VERSION ""

NS_ :

BS_:

BU_: VDM CMR_DSMC SOBDMC_HPCM_FD1 IPMA_ADAS PSCM ABS_ESC TCCM TCM_DSL PCM_HEV PCM ECM_Diesel GENERIC_GWMWakeup GWM _delete TSTR

BO_ 2611055832 PARSEDPhysGWM_ECGtoSODR: 8 GWM
 SG_ PARSEDPhysGWM_ECGtoSODR : 7|29@0+ (1,0) [0|536870911] "unitless" IPMA_ADAS

BO_ 2611054808 PARSEDPhysGWM_ECGtoSODL: 8 GWM
 SG_ PARSEDPhysGWM_ECGtoSODL : 7|29@0+ (1,0) [0|536870911] "unitless" IPMA_ADAS

BO_ 2611026136 PARSEDPhysGWM_ECGtoSODCMD: 8 GWM
 SG_ PARSEDPhysGWM_ECGtoSODCMD : 7|29@0+ (1,0) [0|536870911] "unitless" IPMA_ADAS

BO_ 2611025112 PARSEDPhysGWM_ECGtoSODCMC: 8 GWM
 SG_ PARSEDPhysGWM_ECGtoSODCMC : 7|29@0+ (1,0) [0|536870911] "unitless" IPMA_ADAS

BO_ 2610975960 PARSEDPhysGWM_ECGtoCCM: 8 GWM
 SG_ PARSEDPhysGWM_ECGtoCCM : 7|29@0+ (1,0) [0|536870911] "unitless" IPMA_ADAS

BO_ 2610007256 OTAPhysGWM_ECGtoSODR: 8 GWM
 SG_ OTAPhysGWM_ECGtoSODR : 7|29@0+ (1,0) [0|536870911] "unitless" IPMA_ADAS

BO_ 2610006232 OTAPhysGWM_ECGtoSODL: 8 GWM
 SG_ OTAPhysGWM_ECGtoSODL : 7|29@0+ (1,0) [0|536870911] "unitless" IPMA_ADAS

BO_ 2609977560 OTAPhysGWM_ECGtoSODCMD: 8 GWM
 SG_ OTAPhysGWM_ECGtoSODCMD : 7|29@0+ (1,0) [0|536870911] "unitless" IPMA_ADAS

BO_ 2609976536 OTAPhysGWM_ECGtoSODCMC: 8 GWM
 SG_ OTAPhysGWM_ECGtoSODCMC : 7|29@0+ (1,0) [0|536870911] "unitless" IPMA_ADAS

BO_ 2609927384 OTAPhysGWM_ECGtoCCM: 8 GWM
 SG_ OTAPhysGWM_ECGtoCCM : 7|29@0+ (1,0) [0|536870911] "unitless" IPMA_ADAS

BO_ 2611175523 PARSEDPhysSODRtoGWM_ECG: 8 IPMA_ADAS
 SG_ PARSEDPhysSODRtoGWM_ECG : 7|29@0+ (1,0) [0|536870911] "unitless" GWM

BO_ 2612224099 PARSEDPushSODRtoGWM_ECG: 8 IPMA_ADAS
 SG_ PARSEDPhysSODR2toGWM_ECG : 7|29@0+ (1,0) [0|536870911] "unitless" GWM

BO_ 2611175522 PARSEDPhysSODLtoGWM_ECG: 8 IPMA_ADAS
 SG_ PARSEDPhysSODLtoGWM_ECG : 7|29@0+ (1,0) [0|536870911] "unitless" GWM

BO_ 2612224098 PARSEDPushSODLtoGWM_ECG: 8 IPMA_ADAS
 SG_ PARSEDPhysSODL2toGWM_ECG : 7|29@0+ (1,0) [0|536870911] "unitless" GWM

BO_ 2611175494 PARSEDPhysSODCMDtoGWM_ECG: 8 IPMA_ADAS
 SG_ PARSEDPhysSODCMDtoGWM_ECG : 7|29@0+ (1,0) [0|536870911] "unitless" GWM

BO_ 2612224070 PARSEDPushSODCMDtoGWM: 8 IPMA_ADAS
 SG_ PARSEDPhysSODCMD2toGWM_ECG : 7|29@0+ (1,0) [0|536870911] "unitless" GWM

BO_ 2611175493 PARSEDPhysSODCMCtoGWM_ECG: 8 IPMA_ADAS
 SG_ PARSEDPhysSODCMCtoGWM_ECG : 7|29@0+ (1,0) [0|536870911] "unitless" GWM

BO_ 2612224069 PARSEDPushSODCMCtoGWM: 8 IPMA_ADAS
 SG_ PARSEDPhysSODCMC2toGWM_ECG : 7|29@0+ (1,0) [0|536870911] "unitless" GWM

BO_ 2611175445 PARSEDPhysCCMtoGWM_ECG: 8 IPMA_ADAS
 SG_ PARSEDPhysCCMtoGWM_ECG : 7|29@0+ (1,0) [0|536870911] "unitless" GWM

BO_ 2612224021 PARSEDPushCCMtoGWM_ECG: 8 IPMA_ADAS
 SG_ PARSEDPhysCCM2toGWM_ECG : 7|29@0+ (1,0) [0|536870911] "unitless" GWM

BO_ 2610126947 OTAPhysSODRtoGWM_ECG: 8 IPMA_ADAS
 SG_ OTAPhysSODRtoGWM_ECG : 7|29@0+ (1,0) [0|536870911] "unitless" GWM

BO_ 2610126946 OTAPhysSODLtoGWM_ECG: 8 IPMA_ADAS
 SG_ OTAPhysSODLtoGWM_ECG : 7|29@0+ (1,0) [0|536870911] "unitless" GWM

BO_ 2610126918 OTAPhysSODCMDtoGWM_ECG: 8 IPMA_ADAS
 SG_ OTAPhysSODCMDtoGWM_ECG : 7|29@0+ (1,0) [0|536870911] "unitless" GWM

BO_ 2610126917 OTAPhysSODCMCtoGWM_ECG: 8 IPMA_ADAS
 SG_ OTAPhysSODCMCtoGWM_ECG : 7|29@0+ (1,0) [0|536870911] "unitless" GWM

BO_ 2610126869 OTAPhysCCMtoGWM_ECG: 8 IPMA_ADAS
 SG_ OTAPhysCCMtoGWM_ECG : 7|29@0+ (1,0) [0|536870911] "unitless" GWM

BO_ 984 IPMA_Data: 16 IPMA_ADAS
 SG_ FeatConfigIpmaActl : 7|16@0+ (1,0) [0|65535] "Undefined" GWM
 SG_ FeatNoIpmaActl : 23|16@0+ (1,0) [0|65535] "Number" GWM
 SG_ PersIndexIpma_D_Actl : 39|3@0+ (1,0) [0|7] "SED" GWM
 SG_ AhbcRampingV_D_Rq : 57|2@0+ (1,0) [0|3] "SED" GWM
 SG_ LaActvStats_D_Dsply : 55|5@0+ (1,0) [0|31] "SED" GWM
 SG_ LaDenyStats_B_Dsply : 32|1@0+ (1,0) [0|1] "SED" GWM
 SG_ LaHandsOff_D_Dsply : 50|2@0+ (1,0) [0|3] "SED" GWM
 SG_ CamraDefog_B_Req : 36|1@0+ (1,0) [0|1] "SED" GWM
 SG_ CamraStats_D_Dsply : 35|2@0+ (1,0) [0|3] "SED" GWM
 SG_ DasAlrtLvl_D_Dsply : 42|3@0+ (1,0) [0|7] "SED" GWM
 SG_ DasStats_D_Dsply : 47|2@0+ (1,0) [0|3] "SED" GWM
 SG_ DasWarn_D_Dsply : 44|2@0+ (1,0) [0|3] "SED" GWM
 SG_ AhbHiBeam_D_Rq : 59|2@0+ (1,0) [0|3] "SED" GWM
 SG_ Passthru_63 : 63|4@0+ (1,0) [0|15] "" XXX
 SG_ Passthru_48 : 48|1@0+ (1,0) [0|1] "" XXX

BO_ 985 IPMA_Data2: 16 IPMA_ADAS
 SG_ LdwChime_B_Rq : 34|1@0+ (1,0) [0|1] "SED" GWM
 SG_ TsrRegionTxt_D_Stat : 47|5@0+ (1,0) [0|31] "SED" GWM
 SG_ SblmPedCrossScnr_B_Stat : 33|1@0+ (1,0) [0|1] "SED" GWM
 SG_ LongCtrlEnbl_D_Rq : 42|3@0+ (1,0) [0|7] "SED" ECM_Diesel,PCM,PCM_HEV,GWM
 SG_ SblmRndAbtScnr_B_Stat : 9|1@0+ (1,0) [0|1] "SED" GWM
 SG_ DasAlrtInfo_D_Dsply : 13|2@0+ (1,0) [0|3] "SED" GWM
 SG_ IaccVLim_D_Rq : 23|8@0+ (1,0) [0|255] "SED" ECM_Diesel,GWM
 SG_ IaccVLimUnit_D_Rq : 11|2@0+ (1,0) [0|3] "SED" ECM_Diesel,GWM
 SG_ IsaVLim_D_Rq : 7|8@0+ (1,0) [0|255] "SED" ECM_Diesel,GWM
 SG_ SblmStopScnr_B_Stat : 8|1@0+ (1,0) [0|1] "SED" GWM
 SG_ SblmYieldScnr_B_Stat : 31|1@0+ (1,0) [0|1] "SED" GWM
 SG_ IsaVLimUnit_D_Rq : 15|2@0+ (1,0) [0|3] "SED" ECM_Diesel,GWM
 SG_ AdbDividedRoad_B_Stat : 30|1@0+ (1,0) [0|1] "SED" GWM
 SG_ LcwaMsgTxt_D_Stat : 37|2@0+ (1,0) [0|3] "SED" GWM
 SG_ AdbDrvSide_B_Stat : 35|1@0+ (1,0) [0|1] "SED" GWM

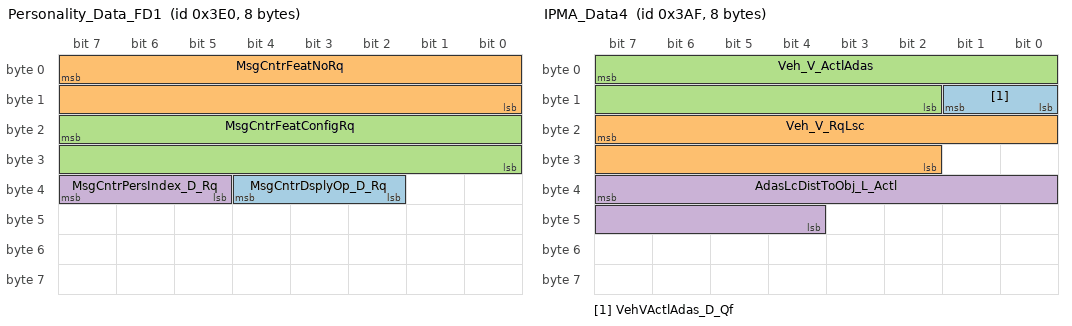
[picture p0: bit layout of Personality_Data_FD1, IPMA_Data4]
BO_ 992 Personality_Data_FD1: 8 GWM
 SG_ MsgCntrDsplyOp_D_Rq : 36|3@0+ (1,0) [0|7] "SED" IPMA_ADAS
 SG_ MsgCntrFeatNoRq : 7|16@0+ (1,0) [0|65535] "Number" IPMA_ADAS
 SG_ MsgCntrFeatConfigRq : 23|16@0+ (1,0) [0|65535] "unitless" IPMA_ADAS
 SG_ MsgCntrPersIndex_D_Rq : 39|3@0+ (1,0) [0|7] "SED" IPMA_ADAS

BO_ 2612019416 PARSEDPushFcGWM_ECGtoPCM: 8 GWM
 SG_ PARSEDPhysGWM_ECG2toPCM : 7|29@0+ (1,0) [0|536870911] "unitless" PCM,PCM_HEV,ECM_Diesel

BO_ 943 IPMA_Data4: 8 IPMA_ADAS
 SG_ VehVActlAdas_D_Qf : 9|2@0+ (1,0) [0|3] "SED" PCM,PCM_HEV,ECM_Diesel
 SG_ Veh_V_RqLsc : 23|14@0+ (0.01,0) [0|163.83] "kph" PCM,PCM_HEV,ECM_Diesel
 SG_ Veh_V_ActlAdas : 7|14@0+ (0.01,0) [0|163.83] "kph" PCM,PCM_HEV,ECM_Diesel
 SG_ AdasLcDistToObj_L_Actl : 39|12@0+ (0.002,0) [0|8.186] "meter" PCM,PCM_HEV,ECM_Diesel

BO_ 515 PowertrainData_12: 8 ECM_Diesel
 SG_ PtIgnSwtch_No_Cs : 15|8@0+ (1,0) [0|255] "Unitless" GWM
 SG_ PtIgnSwtch_No_Cnt : 5|4@0+ (1,0) [0|15] "Unitless" GWM
 SG_ PtIgnSwtch_D_Stat : 7|2@0+ (1,0) [0|3] "SED" GWM

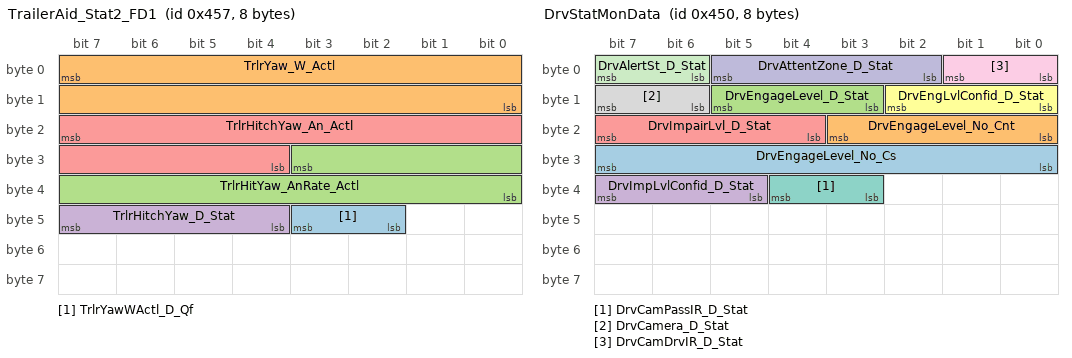
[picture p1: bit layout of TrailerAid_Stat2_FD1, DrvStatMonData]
BO_ 1111 TrailerAid_Stat2_FD1: 8 GWM
 SG_ TrlrYawWActl_D_Qf : 43|2@0+ (1,0) [0|3] "SED" IPMA_ADAS,PSCM
 SG_ TrlrYaw_W_Actl : 7|16@0+ (0.0002,-6.5) [-6.5|6.6066] "radians/second" IPMA_ADAS,PSCM
 SG_ TrlrHitYaw_AnRate_Actl : 27|12@0+ (0.1,-50) [-50|359.3] "degrees/second" IPMA_ADAS,PSCM
 SG_ TrlrHitchYaw_D_Stat : 47|4@0+ (1,0) [0|15] "SED" IPMA_ADAS,PSCM
 SG_ TrlrHitchYaw_An_Actl : 23|12@0+ (0.1,-90) [-90|319.3] "degrees" IPMA_ADAS,PSCM

BO_ 1106 TrailerAid_Stat1_FD1: 8 GWM
 SG_ TrlrSnsId_No_Actl : 7|48@0+ (1,0) [0|281474976710653] "unitless" IPMA_ADAS,PSCM

BO_ 1985 TesterPhysicalReqCMR_DSMC: 64 TSTR
 SG_ TesterPhysicalReqCMR_DSMC : 7|64@0+ (1,0) [0|1.84467E+019] "unitless" CMR_DSMC

BO_ 1993 TesterPhysicalResCMR_DSMC: 64 CMR_DSMC
 SG_ TesterPhysicalResCMR_DSMC : 7|64@0+ (1,0) [0|1.84467E+019] "unitless" TSTR

BO_ 1104 DrvStatMonData: 8 CMR_DSMC
 SG_ DrvEngageLevel_No_Cs : 31|8@0+ (1,0) [0|255] "Unitless" IPMA_ADAS
 SG_ DrvEngageLevel_No_Cnt : 19|4@0+ (1,0) [0|15] "Unitless" IPMA_ADAS
 SG_ DrvEngageLevel_D_Stat : 13|3@0+ (1,0) [0|7] "SED" IPMA_ADAS
 SG_ DrvImpLvlConfid_D_Stat : 39|3@0+ (1,0) [0|7] "SED" IPMA_ADAS
 SG_ DrvImpairLvl_D_Stat : 23|4@0+ (1,0) [0|15] "SED" IPMA_ADAS
 SG_ DrvEngLvlConfid_D_Stat : 10|3@0+ (1,0) [0|7] "SED" IPMA_ADAS
 SG_ DrvCamPassIR_D_Stat : 36|2@0+ (1,0) [0|3] "SED" IPMA_ADAS
 SG_ DrvCamera_D_Stat : 15|2@0+ (1,0) [0|3] "SED" IPMA_ADAS
 SG_ DrvCamDrvIR_D_Stat : 1|2@0+ (1,0) [0|3] "SED" IPMA_ADAS
 SG_ DrvAttentZone_D_Stat : 5|4@0+ (1,0) [0|15] "SED" IPMA_ADAS
 SG_ DrvAlertSt_D_Stat : 7|2@0+ (1,0) [0|3] "SED" IPMA_ADAS

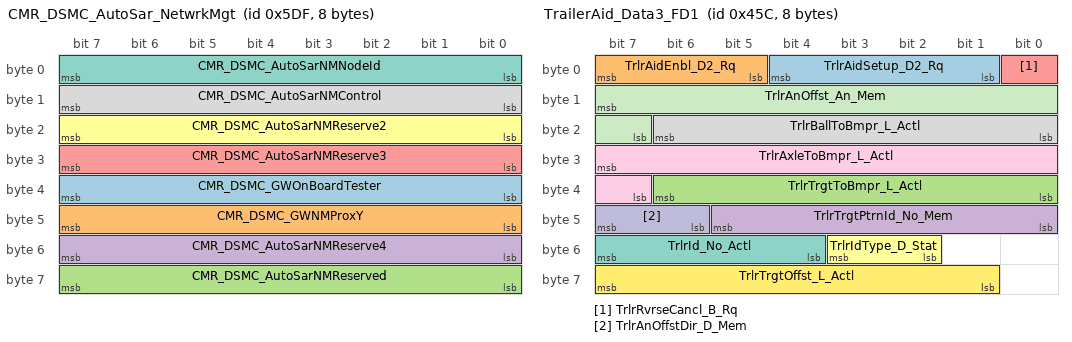
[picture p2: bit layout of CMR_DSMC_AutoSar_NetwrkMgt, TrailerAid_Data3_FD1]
BO_ 1503 CMR_DSMC_AutoSar_NetwrkMgt: 8 CMR_DSMC
 SG_ CMR_DSMC_GWOnBoardTester : 39|8@0+ (1,0) [0|255] "unitless" Vector__XXX
 SG_ CMR_DSMC_GWNMProxY : 47|8@0+ (1,0) [0|255] "unitless" Vector__XXX
 SG_ CMR_DSMC_AutoSarNMReserved : 63|8@0+ (1,0) [0|255] "unitless" Vector__XXX
 SG_ CMR_DSMC_AutoSarNMReserve4 : 55|8@0+ (1,0) [0|255] "unitless" Vector__XXX
 SG_ CMR_DSMC_AutoSarNMReserve3 : 31|8@0+ (1,0) [0|255] "unitless" Vector__XXX
 SG_ CMR_DSMC_AutoSarNMReserve2 : 23|8@0+ (1,0) [0|255] "unitless" Vector__XXX
 SG_ CMR_DSMC_AutoSarNMNodeId : 7|8@0+ (1,0) [0|255] "unitless" Vector__XXX
 SG_ CMR_DSMC_AutoSarNMControl : 15|8@0+ (1,0) [0|255] "unitless" Vector__XXX

BO_ 2610995416 PARSEDPhysGWM_ECGtoABS: 8 GWM
 SG_ PARSEDPhysGWM_ECGtoABS : 7|29@0+ (1,0) [0|536870911] "unitless"  ABS_ESC

BO_ 2612043992 PARSEDPushFcGWM_ECGtoABS: 8 GWM
 SG_ PARSEDPhysGWM_ECG2toABS : 7|29@0+ (1,0) [0|536870911] "unitless"  ABS_ESC

BO_ 2609946840 OTAPhysGWM_ECGtoABS: 8 GWM
 SG_ OTAPhysGWM_ECGtoABS : 7|29@0+ (1,0) [0|536870911] "unitless"  ABS_ESC

BO_ 2611175464 PARSEDPhysABStoGWM_ECG: 8 ABS_ESC
 SG_ PARSEDPhysABStoGWM_ECG : 7|29@0+ (1,0) [0|536870911] "Unitless"  GWM

BO_ 2612224040 PARSEDPushABStoGWM_ECG: 8 ABS_ESC
 SG_ PARSEDPhysABS2toGWM_ECG : 7|29@0+ (1,0) [0|536870911] "unitless"  GWM

BO_ 2610126888 OTAPhysABStoGWM_ECG: 8 ABS_ESC
 SG_ OTAPhysABStoGWM_ECG : 7|29@0+ (1,0) [0|536870911] "unitless"  GWM

BO_ 2610988248 PARSEDPhysGWM_ECGtoIPMA: 8 GWM
 SG_ PARSEDPhysGWM_ECGtoIPMA : 7|29@0+ (1,0) [0|536870911] "unitless"  IPMA_ADAS

BO_ 2609939672 OTAPhysGWM_ECGtoIPMA: 8 GWM
 SG_ OTAPhysGWM_ECGtoIPMA : 7|29@0+ (1,0) [0|536870911] "unitless"  IPMA_ADAS

BO_ 1114 TrailerAid_Data_FD1: 8 GWM
 SG_ TrailCtlSwtch_B_Stat2 : 16|1@0+ (1,0) [0|1] "SED"  ABS_ESC
 SG_ TrlBrkInitOut_D_Rq : 60|2@0+ (1,0) [0|3] "SED" Vector__XXX

BO_ 1116 TrailerAid_Data3_FD1: 8 GWM
 SG_ TrlrAidSetup_D2_Rq : 4|4@0+ (1,0) [0|15] "SED"  IPMA_ADAS,PSCM
 SG_ TrlrAidEnbl_D2_Rq : 7|3@0+ (1,0) [0|7] "SED"  IPMA_ADAS,PSCM
 SG_ TrlrTrgtToBmpr_L_Actl : 38|7@0+ (0.0127,0) [0|1.6129] "meter"  IPMA_ADAS
 SG_ TrlrTrgtPtrnId_No_Mem : 45|6@0+ (1,0) [0|63] "unitless"  IPMA_ADAS
 SG_ TrlrRvrseCancl_B_Rq : 0|1@0+ (1,0) [0|1] "SED"  IPMA_ADAS,PSCM
 SG_ TrlrIdType_D_Stat : 51|2@0+ (1,0) [0|3] "SED"  IPMA_ADAS,PSCM
 SG_ TrlrId_No_Actl : 55|4@0+ (1,0) [0|15] "unitless"  IPMA_ADAS,PSCM
 SG_ TrlrBallToBmpr_L_Actl : 22|7@0+ (0.0127,0) [0|1.6129] "meter"  IPMA_ADAS,PSCM
 SG_ TrlrAxleToBmpr_L_Actl : 31|9@0+ (0.0254,0) [0|12.9794] "meter"  IPMA_ADAS,PSCM
 SG_ TrlrAnOffstDir_D_Mem : 47|2@0+ (1,0) [0|3] "SED"  IPMA_ADAS,PSCM
 SG_ TrlrAnOffst_An_Mem : 15|9@0+ (0.1,0) [0|51.1] "degrees"  IPMA_ADAS
 SG_ TrlrTrgtOffst_L_Actl : 63|7@0+ (0.0127,0) [0|1.6129] "meter"  IPMA_ADAS

BO_ 2611175457 PARSEDPhysIPMAtoGWM_ECG: 8 IPMA_ADAS
 SG_ PARSEDPhysIPMAtoGWM_ECG : 7|29@0+ (1,0) [0|536870911] "unitless"  GWM

BO_ 2612224033 PARSEDPushIPMAtoGWM_ECG: 8 IPMA_ADAS
 SG_ PARSEDPhysIPMA2toGWM_ECG : 7|29@0+ (1,0) [0|536870911] "unitless"  GWM

BO_ 2610126881 OTAPhysIPMAtoGWM_ECG: 8 IPMA_ADAS
 SG_ OTAPhysIPMAtoGWM_ECG : 7|29@0+ (1,0) [0|536870911] "unitless"  GWM

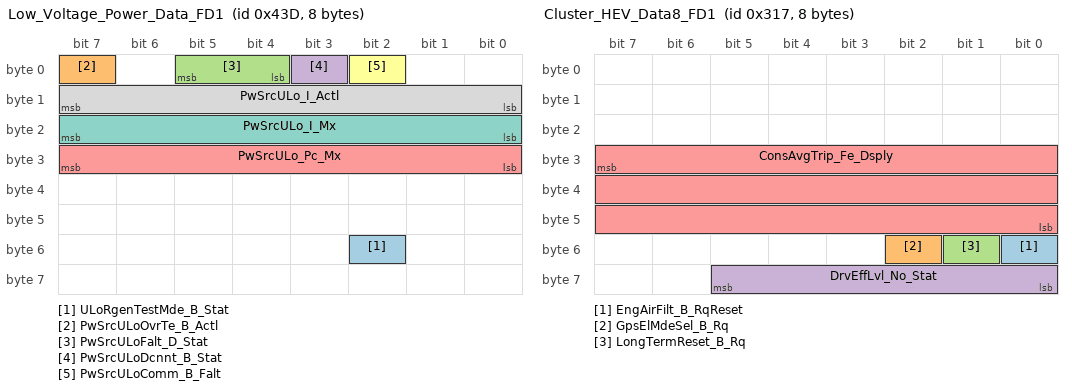
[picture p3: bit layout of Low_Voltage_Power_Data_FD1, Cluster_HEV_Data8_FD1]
BO_ 1085 Low_Voltage_Power_Data_FD1: 8 PCM
 SG_ ULoRgenTestMde_B_Stat : 50|1@0+ (1,0) [0|1] "SED"  GWM
 SG_ PwSrcULoOvrTe_B_Actl : 7|1@0+ (1,0) [0|1] "SED"  GWM
 SG_ PwSrcULoFalt_D_Stat : 5|2@0+ (1,0) [0|3] "SED"  GWM
 SG_ PwSrcULoDcnnt_B_Stat : 3|1@0+ (1,0) [0|1] "SED"  GWM
 SG_ PwSrcULo_Pc_Mx : 31|8@0+ (0.4,0) [0|101.6] "%"  GWM
 SG_ PwSrcULoComm_B_Falt : 2|1@0+ (1,0) [0|1] "SED"  GWM
 SG_ PwSrcULo_I_Mx : 23|8@0+ (1,0) [0|254] "ampere"  PCM_HEV,GWM
 SG_ PwSrcULo_I_Actl : 15|8@0+ (1,0) [0|254] "ampere"  PCM_HEV,GWM

BO_ 791 Cluster_HEV_Data8_FD1: 8 GWM
 SG_ EngAirFilt_B_RqReset : 48|1@0+ (1,0) [0|1] "SED"  ECM_Diesel
 SG_ GpsElMdeSel_B_Rq : 50|1@0+ (1,0) [0|1] "SED" Vector__XXX
 SG_ LongTermReset_B_Rq : 49|1@0+ (1,0) [0|1] "SED" Vector__XXX
 SG_ DrvEffLvl_No_Stat : 61|6@0+ (1,0) [0|61] "unitless" Vector__XXX
 SG_ ConsAvgTrip_Fe_Dsply : 31|24@0+ (0.0001,0) [0|1677.7215] "litre/100km" Vector__XXX

BO_ 2610970840 PARSEDPhysGWM_ECGtoPCM: 8 GWM
 SG_ PARSEDPhysGWM_ECGtoPCM : 7|29@0+ (1,0) [0|536870911] "unitless"  ECM_Diesel,PCM_HEV,PCM

BO_ 2609922264 OTAPhysGWM_ECGtoPCM: 8 GWM
 SG_ OTAPhysGWM_ECGtoPCM : 7|29@0+ (1,0) [0|536870911] "unitless"  ECM_Diesel,PCM_HEV,PCM

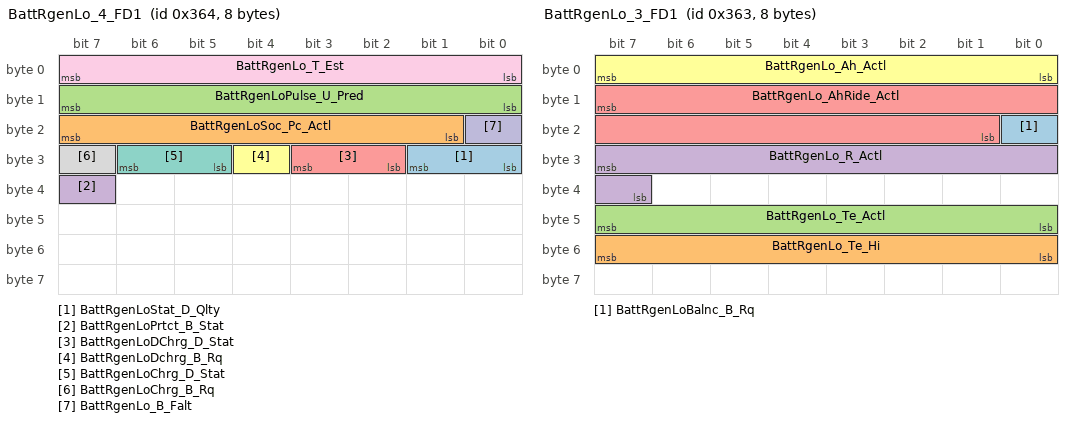
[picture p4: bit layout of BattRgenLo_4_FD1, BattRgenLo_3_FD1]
BO_ 868 BattRgenLo_4_FD1: 8 GWM
 SG_ BattRgenLoStat_D_Qlty : 25|2@0+ (1,0) [0|3] "SED"  PCM_HEV,PCM
 SG_ BattRgenLoSoc_Pc_Actl : 23|7@0+ (1,0) [0|100] "percent"  PCM_HEV,PCM
 SG_ BattRgenLoPulse_U_Pred : 15|8@0+ (0.0625,0) [0|15.9375] "volt"  PCM_HEV,PCM
 SG_ BattRgenLoPrtct_B_Stat : 39|1@0+ (1,0) [0|1] "SED"  PCM_HEV,PCM
 SG_ BattRgenLoDChrg_D_Stat : 27|2@0+ (1,0) [0|3] "SED"  PCM_HEV,PCM
 SG_ BattRgenLoDchrg_B_Rq : 28|1@0+ (1,0) [0|1] "SED"  PCM_HEV,PCM
 SG_ BattRgenLoChrg_D_Stat : 30|2@0+ (1,0) [0|3] "SED"  PCM_HEV,PCM
 SG_ BattRgenLoChrg_B_Rq : 31|1@0+ (1,0) [0|1] "SED"  PCM_HEV,PCM
 SG_ BattRgenLo_T_Est : 7|8@0+ (8,0) [0|2040] "second"  PCM_HEV,PCM
 SG_ BattRgenLo_B_Falt : 16|1@0+ (1,0) [0|1] "SED"  PCM_HEV,PCM

BO_ 867 BattRgenLo_3_FD1: 8 GWM
 SG_ BattRgenLoBalnc_B_Rq : 16|1@0+ (1,0) [0|1] "SED"  PCM_HEV,PCM
 SG_ BattRgenLo_Te_Hi : 55|8@0+ (1,-20) [-20|235] "degC"  PCM_HEV,PCM
 SG_ BattRgenLo_Te_Actl : 47|8@0+ (1,-60) [-60|194] "degC"  PCM_HEV,PCM
 SG_ BattRgenLo_R_Actl : 31|9@0+ (0.0625,0) [0|31.9375] "milliohm"  PCM_HEV,PCM
 SG_ BattRgenLo_AhRide_Actl : 15|15@0+ (0.0078125,-100) [-100|155.9921875] "amperehour"  PCM_HEV,PCM
 SG_ BattRgenLo_Ah_Actl : 7|8@0+ (0.1,0) [0|25.5] "amperehour"  PCM_HEV,PCM

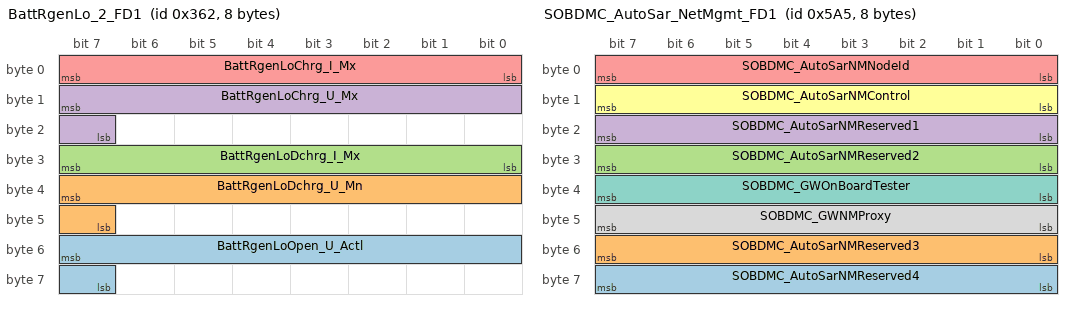
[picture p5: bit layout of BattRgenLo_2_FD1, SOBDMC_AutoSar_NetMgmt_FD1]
BO_ 866 BattRgenLo_2_FD1: 8 GWM
 SG_ BattRgenLoOpen_U_Actl : 55|9@0+ (0.025,8.5) [8.5|21.275] "volt"  PCM_HEV,PCM
 SG_ BattRgenLoDchrg_U_Mn : 39|9@0+ (0.025,4) [4|16.775] "volt"  PCM_HEV,PCM
 SG_ BattRgenLoDchrg_I_Mx : 31|8@0+ (2,0) [0|510] "ampere"  PCM_HEV,PCM
 SG_ BattRgenLoChrg_U_Mx : 15|9@0+ (0.025,10.6) [10.6|23.375] "volt"  PCM_HEV,PCM
 SG_ BattRgenLoChrg_I_Mx : 7|8@0+ (2,0) [0|510] "ampere"  PCM_HEV,PCM

BO_ 865 BattRgenLo_1_FD1: 8 GWM
 SG_ BattRgenLo_U_Actl : 23|11@0+ (0.015625,0) [0|31.96875] "volt"  PCM_HEV,PCM
 SG_ BattRgenLo_I_Actl : 7|16@0+ (0.015625,-512) [-512|511.96875] "ampere"  PCM_HEV,PCM

BO_ 2611175440 PARSEDPhysPCMtoGWM_ECG: 8 PCM
 SG_ PARSEDPhysPCMtoGWM_ECG : 7|29@0+ (1,0) [0|536870911] "unitless"  GWM

BO_ 2610126864 OTAPhysPCMtoGWM_ECG: 8 PCM
 SG_ OTAPhysPCMtoGWM_ECG : 7|29@0+ (1,0) [0|536870911] "unitless"  GWM

BO_ 2611175441 PARSEDHPCMtoGWM_ECG_FD1: 8 SOBDMC_HPCM_FD1
 SG_ PARSEDPhysHPCMtoGWM_ECG : 7|29@0+ (1,0) [0|536870911] "unitless"  GWM

BO_ 2612224017 PARSEDPushSOBDMCtoGWM_FD1: 8 SOBDMC_HPCM_FD1
 SG_ PARSEDPhysHPCM2toGWM_ECG : 7|29@0+ (1,0) [0|536870911] "unitless"  GWM

BO_ 2610126865 OTAPhysSOBDMCtoGWM_FD1: 8 SOBDMC_HPCM_FD1
 SG_ OTAPhysHPCMtoGWM_ECG : 7|29@0+ (1,0) [0|536870911] "unitless"  GWM

BO_ 1679 SOBDMC_RapidData_Resp4_FD1: 8 SOBDMC_HPCM_FD1
 SG_ UUDTSOBDMCResponse4 : 7|64@0+ (1,0) [0|1.84467440737096E+019] "unitless"  TSTR

BO_ 1678 SOBDMC_RapidData_Resp3_FD1: 8 SOBDMC_HPCM_FD1
 SG_ UUDTSOBDMCResponse3 : 7|64@0+ (1,0) [0|1.84467440737096E+019] "unitless"  TSTR

BO_ 1677 SOBDMC_RapidData_Resp2_FD1: 8 SOBDMC_HPCM_FD1
 SG_ UUDTSOBDMCResponse2 : 7|64@0+ (1,0) [0|1.84467440737096E+019] "unitless"  TSTR

BO_ 1676 SOBDMC_RapidData_Resp1_FD1: 8 SOBDMC_HPCM_FD1
 SG_ UUDTSOBDMCResponse1 : 7|64@0+ (1,0) [0|1.84467440737096E+019] "unitless"  TSTR

BO_ 1445 SOBDMC_AutoSar_NetMgmt_FD1: 8 SOBDMC_HPCM_FD1
 SG_ SOBDMC_AutoSarNMReserved4 : 63|8@0+ (1,0) [0|255] "unitless" Vector__XXX
 SG_ SOBDMC_AutoSarNMReserved3 : 55|8@0+ (1,0) [0|255] "unitless" Vector__XXX
 SG_ SOBDMC_AutoSarNMReserved2 : 31|8@0+ (1,0) [0|255] "unitless" Vector__XXX
 SG_ SOBDMC_AutoSarNMReserved1 : 23|8@0+ (1,0) [0|255] "unitless" Vector__XXX
 SG_ SOBDMC_AutoSarNMNodeId : 7|8@0+ (1,0) [0|255] "unitless" Vector__XXX
 SG_ SOBDMC_AutoSarNMControl : 15|8@0+ (1,0) [0|255] "unitless" Vector__XXX
 SG_ SOBDMC_GWOnBoardTester : 39|8@0+ (1,0) [0|255] "unitless" Vector__XXX
 SG_ SOBDMC_GWNMProxy : 47|8@0+ (1,0) [0|255] "unitless" Vector__XXX

BO_ 1144 MHT_EV_Wakeup_FD1: 8 SOBDMC_HPCM_FD1
 SG_ WakeAlarm0_T_Rq : 7|15@0+ (1,0) [0|32767] "minute"  GWM
 SG_ WakeAlarm0_B_Typ : 21|1@0+ (1,0) [0|1] "SED"  GWM
 SG_ PreCondBatt_B_Actl : 32|1@0+ (1,0) [0|1] "SED"  GWM
 SG_ HtrnDcdcDis_B_Rq : 26|1@0+ (1,0) [0|1] "SED"  GWM
 SG_ ChrgNowEvnt_B_Stat : 22|1@0+ (1,0) [0|1] "SED"  GWM
 SG_ CabinDrvSustn_B_Rq : 23|1@0+ (1,0) [0|1] "SED"  GWM
 SG_ BattChrgTrgtSoC_D_Rq : 35|3@0+ (1,0) [0|7] "Percent"  GWM
 SG_ CabnEvapSovFront_B_Rq : 38|1@0+ (1,0) [0|1] "SED"  GWM
 SG_ HeatCoreSovRear_B_Rq : 36|1@0+ (1,0) [0|1] "SED"  GWM
 SG_ BattChlrSov_B_Rq : 39|1@0+ (1,0) [0|1] "SED"  GWM
 SG_ CabnEvapSovRear_B_Rq : 37|1@0+ (1,0) [0|1] "SED"  GWM
 SG_ BrkAppl_D_RqPt : 25|2@0+ (1,0) [0|3] "SED"  GWM
 SG_ HtrnCnnctPwr_B_Stat : 16|1@0+ (1,0) [0|1] "SED"  GWM
 SG_ PtcHtr_D_Stat : 18|2@0+ (1,0) [0|3] "SED"  GWM,PCM_HEV
 SG_ HtrnClntFlw_D_Rq : 20|2@0+ (1,0) [0|3] "SED"  GWM
 SG_ BattTracDrvSustn_B_Rq : 8|1@0+ (1,0) [0|1] "SED"  GWM
 SG_ BattTracClntVlv_B_Rq : 47|1@0+ (1,0) [0|1] "SED"  GWM

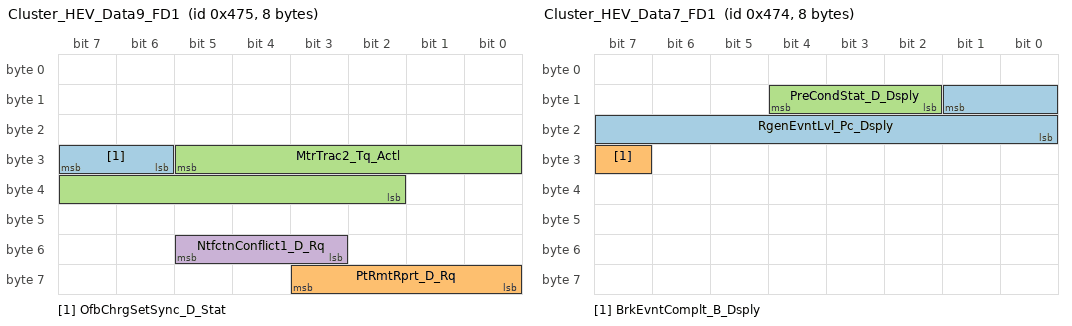
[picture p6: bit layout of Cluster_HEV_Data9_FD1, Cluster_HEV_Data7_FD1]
BO_ 1141 Cluster_HEV_Data9_FD1: 8 SOBDMC_HPCM_FD1
 SG_ OfbChrgSetSync_D_Stat : 31|2@0+ (1,0) [0|3] "SED"  GWM
 SG_ PtRmtRprt_D_Rq : 59|4@0+ (1,0) [0|15] "SED"  GWM
 SG_ MtrTrac2_Tq_Actl : 29|12@0+ (1,-2047) [-2047|2048] "Nm"  GWM
 SG_ NtfctnConflict1_D_Rq : 53|3@0+ (1,0) [0|7] "SED"  GWM

BO_ 1140 Cluster_HEV_Data7_FD1: 8 SOBDMC_HPCM_FD1
 SG_ RgenEvntLvl_Pc_Dsply : 9|10@0+ (0.1,0) [0|102.1] "percent"  GWM
 SG_ BrkEvntComplt_B_Dsply : 31|1@0+ (1,0) [0|1] "SED"  GWM
 SG_ PreCondStat_D_Dsply : 12|3@0+ (1,0) [0|7] "SED"  GWM

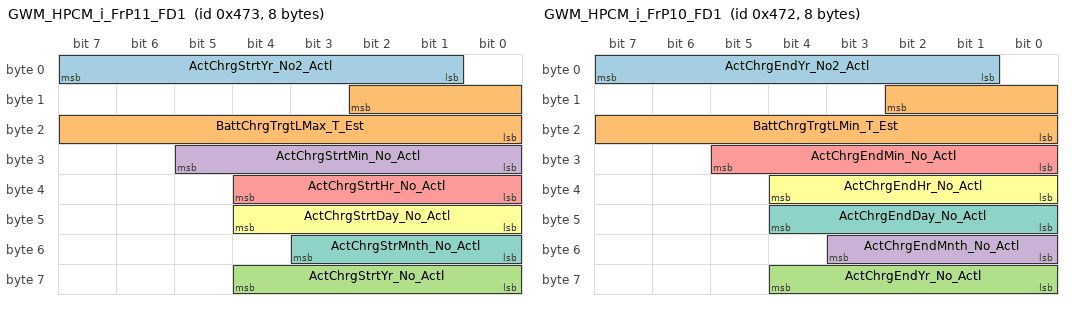
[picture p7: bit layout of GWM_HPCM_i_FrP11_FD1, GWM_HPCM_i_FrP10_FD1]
BO_ 1139 GWM_HPCM_i_FrP11_FD1: 8 SOBDMC_HPCM_FD1
 SG_ ActChrgStrtYr_No2_Actl : 7|7@0+ (1,2017) [2017|2144] "year"  GWM
 SG_ BattChrgTrgtLMax_T_Est : 10|11@0+ (1,0) [0|2045] "minute"  GWM
 SG_ ActChrgStrtYr_No_Actl : 60|5@0+ (1,2010) [2010|2040] "year"  GWM
 SG_ ActChrgStrtMin_No_Actl : 29|6@0+ (1,0) [0|61] "minute"  GWM
 SG_ ActChrgStrtHr_No_Actl : 36|5@0+ (1,0) [0|29] "hour"  GWM
 SG_ ActChrgStrtDay_No_Actl : 44|5@0+ (1,1) [1|31] "days"  GWM
 SG_ ActChrgStrMnth_No_Actl : 51|4@0+ (1,1) [1|15] "month"  GWM

BO_ 1138 GWM_HPCM_i_FrP10_FD1: 8 SOBDMC_HPCM_FD1
 SG_ ActChrgEndYr_No2_Actl : 7|7@0+ (1,2017) [2017|2144] "year"  GWM
 SG_ BattChrgTrgtLMin_T_Est : 10|11@0+ (1,0) [0|2045] "minute"  GWM
 SG_ ActChrgEndYr_No_Actl : 60|5@0+ (1,2010) [2010|2040] "year"  GWM
 SG_ ActChrgEndMnth_No_Actl : 51|4@0+ (1,1) [1|15] "month"  GWM
 SG_ ActChrgEndMin_No_Actl : 29|6@0+ (1,0) [0|61] "minute"  GWM
 SG_ ActChrgEndHr_No_Actl : 36|5@0+ (1,0) [0|29] "hour"  GWM
 SG_ ActChrgEndDay_No_Actl : 44|5@0+ (1,1) [1|31] "days"  GWM

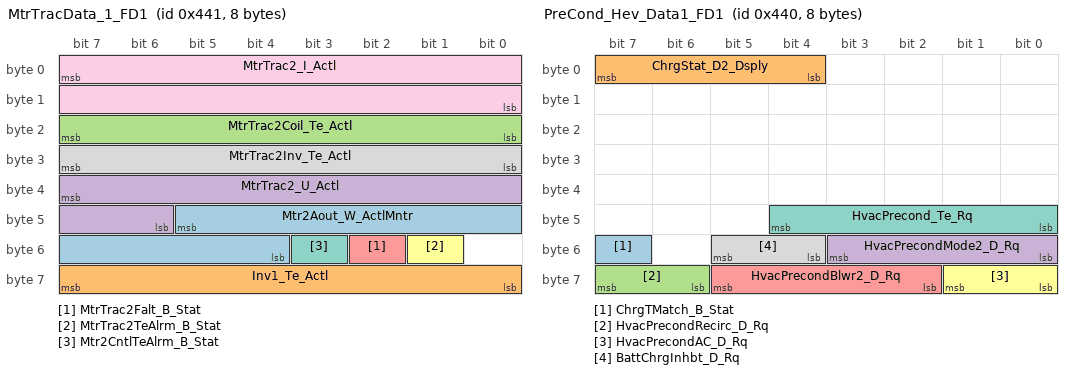
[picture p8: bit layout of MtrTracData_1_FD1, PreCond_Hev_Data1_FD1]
BO_ 1089 MtrTracData_1_FD1: 8 SOBDMC_HPCM_FD1
 SG_ Mtr2Aout_W_ActlMntr : 45|10@0+ (6.28,-3209) [-3209|3209.16] "radians/sec"  GWM
 SG_ Inv1_Te_Actl : 63|8@0+ (1,-40) [-40|213] "degC"  GWM
 SG_ MtrTrac2Coil_Te_Actl : 23|8@0+ (1,-40) [-40|213] "degC"  GWM
 SG_ MtrTrac2_U_Actl : 39|10@0+ (1,0) [0|1023] "volt"  GWM
 SG_ MtrTrac2Falt_B_Stat : 50|1@0+ (1,0) [0|1] "SED"  GWM
 SG_ MtrTrac2TeAlrm_B_Stat : 49|1@0+ (1,0) [0|1] "SED"  GWM
 SG_ Mtr2CntlTeAlrm_B_Stat : 51|1@0+ (1,0) [0|1] "SED"  GWM
 SG_ MtrTrac2Inv_Te_Actl : 31|8@0+ (1,-40) [-40|213] "degC"  GWM
 SG_ MtrTrac2_I_Actl : 7|16@0+ (0.1,-1000) [-1000|5553.4] "ampere"  GWM

BO_ 1088 PreCond_Hev_Data1_FD1: 8 SOBDMC_HPCM_FD1
 SG_ ChrgTMatch_B_Stat : 55|1@0+ (1,0) [0|1] "SED"  GWM
 SG_ ChrgStat_D2_Dsply : 7|4@0+ (1,0) [0|15] "SED"  GWM
 SG_ HvacPrecondRecirc_D_Rq : 63|2@0+ (1,0) [0|3] "SED"  GWM
 SG_ HvacPrecondMode2_D_Rq : 51|4@0+ (1,0) [0|15] "SED"  GWM
 SG_ HvacPrecondBlwr2_D_Rq : 61|4@0+ (1,0) [0|15] "SED"  GWM
 SG_ HvacPrecondAC_D_Rq : 57|2@0+ (1,0) [0|3] "SED"  GWM
 SG_ HvacPrecond_Te_Rq : 44|5@0+ (0.5,14.5) [14.5|30] "deg C"  GWM
 SG_ BattChrgInhbt_D_Rq : 53|2@0+ (1,0) [0|3] "SED"  GWM

BO_ 1040 AC_Compressor_Req_FD1: 8 SOBDMC_HPCM_FD1
 SG_ ElCmprEnbl_B_Rq : 23|1@0+ (1,0) [0|1] "SED"  GWM,PCM_HEV
 SG_ ElCmpr_N_Rq : 15|8@0+ (50,0) [0|12750] "RPM"  GWM

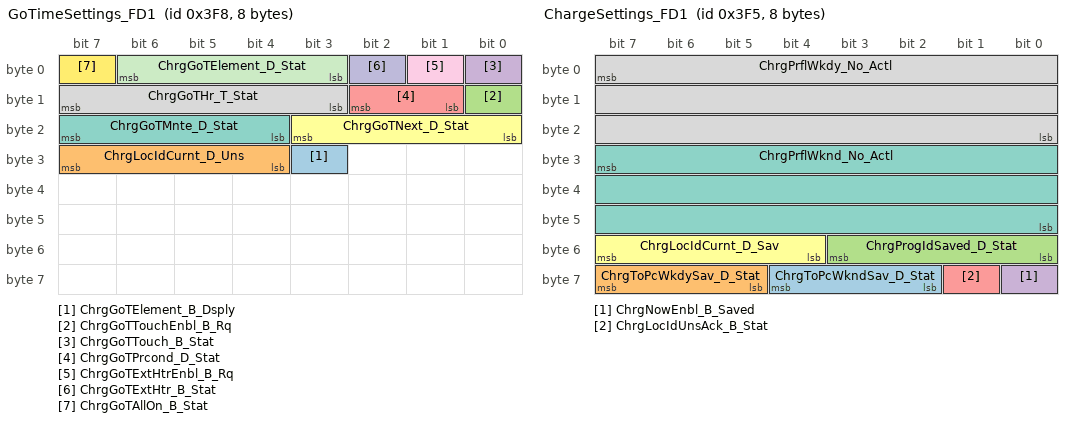
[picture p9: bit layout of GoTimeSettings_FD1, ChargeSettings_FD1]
BO_ 1016 GoTimeSettings_FD1: 8 SOBDMC_HPCM_FD1
 SG_ ChrgGoTElement_B_Dsply : 27|1@0+ (1,0) [0|1] "SED"  GWM
 SG_ ChrgLocIdCurnt_D_Uns : 31|4@0+ (1,0) [0|15] "unitless"  GWM
 SG_ ChrgGoTTouchEnbl_B_Rq : 8|1@0+ (1,0) [0|1] "SED"  GWM
 SG_ ChrgGoTTouch_B_Stat : 0|1@0+ (1,0) [0|1] "SED"  GWM
 SG_ ChrgGoTPrcond_D_Stat : 10|2@0+ (1,0) [0|3] "SED"  GWM
 SG_ ChrgGoTNext_D_Stat : 19|4@0+ (1,0) [0|15] "Unitless"  GWM
 SG_ ChrgGoTMnte_D_Stat : 23|4@0+ (1,0) [0|15] "SED"  GWM
 SG_ ChrgGoTHr_T_Stat : 15|5@0+ (1,0) [0|29] "hour"  GWM
 SG_ ChrgGoTExtHtrEnbl_B_Rq : 1|1@0+ (1,0) [0|1] "SED"  GWM
 SG_ ChrgGoTExtHtr_B_Stat : 2|1@0+ (1,0) [0|1] "SED"  GWM
 SG_ ChrgGoTElement_D_Stat : 6|4@0+ (1,0) [0|15] "Unitless"  GWM
 SG_ ChrgGoTAllOn_B_Stat : 7|1@0+ (1,0) [0|1] "SED"  GWM

BO_ 1013 ChargeSettings_FD1: 8 SOBDMC_HPCM_FD1
 SG_ ChrgToPcWkndSav_D_Stat : 60|3@0+ (1,0) [0|7] "SED"  GWM
 SG_ ChrgToPcWkdySav_D_Stat : 63|3@0+ (1,0) [0|7] "SED"  GWM
 SG_ ChrgProgIdSaved_D_Stat : 51|4@0+ (1,0) [0|15] "Unitless"  GWM
 SG_ ChrgNowEnbl_B_Saved : 56|1@0+ (1,0) [0|1] "SED"  GWM
 SG_ ChrgLocIdUnsAck_B_Stat : 57|1@0+ (1,0) [0|1] "SED"  GWM
 SG_ ChrgLocIdCurnt_D_Sav : 55|4@0+ (1,0) [0|15] "unitless"  GWM
 SG_ ChrgPrflWknd_No_Actl : 31|24@0+ (1,0) [0|16777215] "unitless"  GWM
 SG_ ChrgPrflWkdy_No_Actl : 7|24@0+ (1,0) [0|16777215] "unitless"  GWM

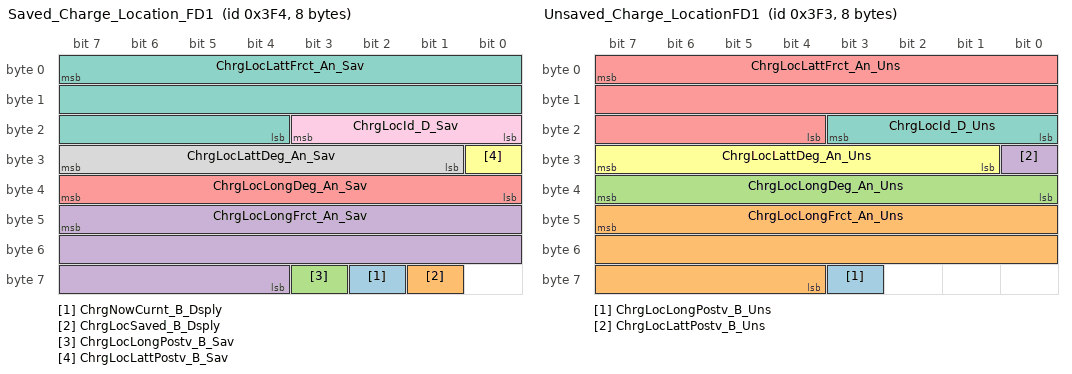
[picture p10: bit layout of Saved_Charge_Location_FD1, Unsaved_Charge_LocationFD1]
BO_ 1012 Saved_Charge_Location_FD1: 8 SOBDMC_HPCM_FD1
 SG_ ChrgNowCurnt_B_Dsply : 58|1@0+ (1,0) [0|1] "SED"  GWM
 SG_ ChrgLocSaved_B_Dsply : 57|1@0+ (1,0) [0|1] "SED"  GWM
 SG_ ChrgLocLongPostv_B_Sav : 59|1@0+ (1,0) [0|1] "SED"  GWM
 SG_ ChrgLocLongFrct_An_Sav : 47|20@0+ (1E-006,0) [0|1.048575] "degrees"  GWM
 SG_ ChrgLocLongDeg_An_Sav : 39|8@0+ (1,0) [0|255] "degrees"  GWM
 SG_ ChrgLocLattPostv_B_Sav : 24|1@0+ (1,0) [0|1] "SED"  GWM
 SG_ ChrgLocLattFrct_An_Sav : 7|20@0+ (1E-006,0) [0|1.048575] "degrees"  GWM
 SG_ ChrgLocLattDeg_An_Sav : 31|7@0+ (1,0) [0|127] "unitless"  GWM
 SG_ ChrgLocId_D_Sav : 19|4@0+ (1,0) [0|15] "unitless"  GWM

BO_ 1011 Unsaved_Charge_LocationFD1: 8 SOBDMC_HPCM_FD1
 SG_ ChrgLocLongPostv_B_Uns : 59|1@0+ (1,0) [0|1] "SED"  GWM
 SG_ ChrgLocLongFrct_An_Uns : 47|20@0+ (1E-006,0) [0|1.048575] "degrees"  GWM
 SG_ ChrgLocLongDeg_An_Uns : 39|8@0+ (1,0) [0|255] "degrees"  GWM
 SG_ ChrgLocLattPostv_B_Uns : 24|1@0+ (1,0) [0|1] "SED"  GWM
 SG_ ChrgLocLattFrct_An_Uns : 7|20@0+ (1E-006,0) [0|1.048575] "degrees"  GWM
 SG_ ChrgLocLattDeg_An_Uns : 31|7@0+ (1,0) [0|127] "unitless"  GWM
 SG_ ChrgLocId_D_Uns : 19|4@0+ (1,0) [0|15] "unitless"  GWM

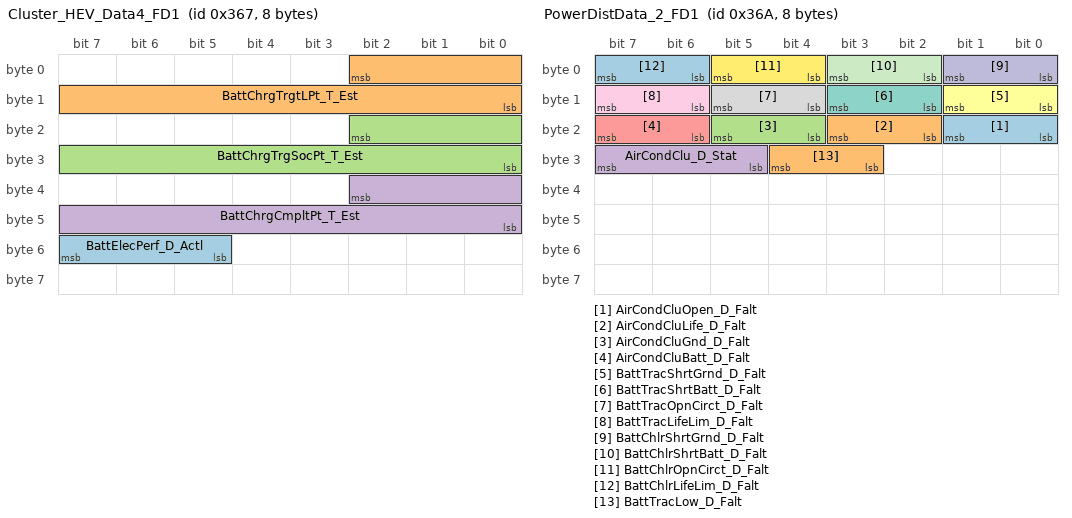
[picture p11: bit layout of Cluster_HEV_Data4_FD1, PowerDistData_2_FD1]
BO_ 871 Cluster_HEV_Data4_FD1: 8 SOBDMC_HPCM_FD1
 SG_ BattElecPerf_D_Actl : 55|3@0+ (1,0) [0|7] "SED"  GWM
 SG_ BattChrgTrgtLPt_T_Est : 2|11@0+ (1,0) [0|2045] "minute"  GWM
 SG_ BattChrgTrgSocPt_T_Est : 18|11@0+ (1,0) [0|2045] "minute"  GWM
 SG_ BattChrgCmpltPt_T_Est : 34|11@0+ (1,0) [0|2045] "minute"  GWM

BO_ 786 Cluster_HEV_Data1_FD1: 8 SOBDMC_HPCM_FD1
 SG_ RgenTrip_Pc_Dsply : 33|10@0+ (0.1,0) [0|102.3] "percent"  GWM
 SG_ RgenTrip_L_Dsply : 55|16@0+ (0.1,0) [0|6553.3] "kilometer"  GWM
 SG_ ChrgStat_D_Dsply : 36|3@0+ (1,0) [0|7] "SED"  GWM

BO_ 72 Global_PATS_Target2_FD1: 8 SOBDMC_HPCM_FD1
 SG_ immoTarget2Status : 7|3@0+ (1,0) [0|7] "SED"  GWM
 SG_ immoTarget2Data : 15|40@0+ (1,0) [0|1099511627775] "Encrypted"  GWM
 SG_ immoTarget2Cmd : 4|3@0+ (1,0) [0|7] "SED"  GWM

BO_ 912 PowerDist_Data1_FD1: 8 GWM
 SG_ CabnEvapSovFront_D_Stat : 15|3@0+ (1,0) [0|7] "SED"  SOBDMC_HPCM_FD1
 SG_ BattChlrSov_D_Stat : 7|3@0+ (1,0) [0|7] "SED"  SOBDMC_HPCM_FD1
 SG_ BattTracClntVlv_D_Stat : 28|3@0+ (1,0) [0|7] "SED"  SOBDMC_HPCM_FD1

BO_ 874 PowerDistData_2_FD1: 8 GWM
 SG_ AirCondCluOpen_D_Falt : 17|2@0+ (1,0) [0|3] "SED" Vector__XXX
 SG_ AirCondCluLife_D_Falt : 19|2@0+ (1,0) [0|3] "SED" Vector__XXX
 SG_ AirCondCluGnd_D_Falt : 21|2@0+ (1,0) [0|3] "SED" Vector__XXX
 SG_ AirCondClu_D_Stat : 31|3@0+ (1,0) [0|7] "SED" Vector__XXX
 SG_ AirCondCluBatt_D_Falt : 23|2@0+ (1,0) [0|3] "SED" Vector__XXX
 SG_ BattTracShrtGrnd_D_Falt : 9|2@0+ (1,0) [0|3] "SED"  SOBDMC_HPCM_FD1
 SG_ BattTracShrtBatt_D_Falt : 11|2@0+ (1,0) [0|3] "SED"  SOBDMC_HPCM_FD1
 SG_ BattTracOpnCirct_D_Falt : 13|2@0+ (1,0) [0|3] "SED"  SOBDMC_HPCM_FD1
 SG_ BattTracLifeLim_D_Falt : 15|2@0+ (1,0) [0|3] "SED"  SOBDMC_HPCM_FD1
 SG_ BattChlrShrtGrnd_D_Falt : 1|2@0+ (1,0) [0|3] "SED"  SOBDMC_HPCM_FD1
 SG_ BattChlrShrtBatt_D_Falt : 3|2@0+ (1,0) [0|3] "SED"  SOBDMC_HPCM_FD1
 SG_ BattChlrOpnCirct_D_Falt : 5|2@0+ (1,0) [0|3] "SED"  SOBDMC_HPCM_FD1
 SG_ BattChlrLifeLim_D_Falt : 7|2@0+ (1,0) [0|3] "SED"  SOBDMC_HPCM_FD1
 SG_ BattTracLow_D_Falt : 28|2@0+ (1,0) [0|3] "SED"  SOBDMC_HPCM_FD1

BO_ 651 TCU_Send_Signals_FD1: 8 GWM
 SG_ TelematicsSrvc_D_St : 47|3@0+ (1,0) [0|7] "SED"  SOBDMC_HPCM_FD1
 SG_ EmgcyCallMute_D_Stat : 39|3@0+ (1,0) [0|7] "SED" Vector__XXX
 SG_ OfbChrgSetSync_D_Rq : 3|2@0+ (1,0) [0|3] "SED" Vector__XXX

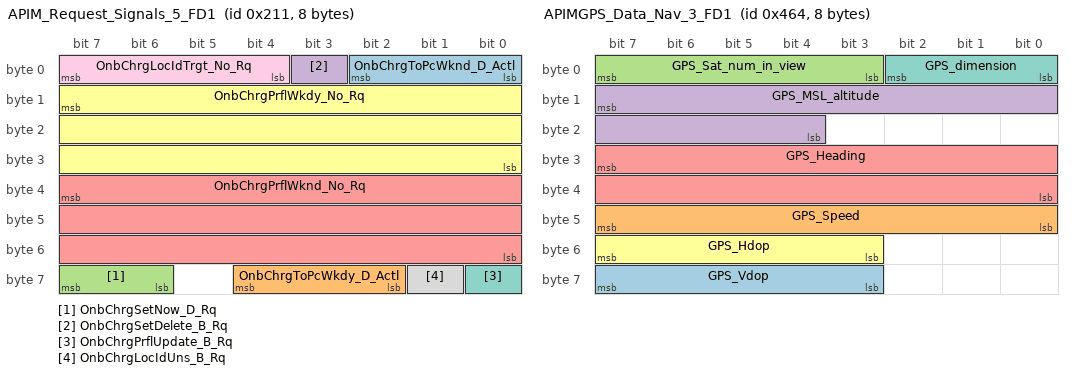
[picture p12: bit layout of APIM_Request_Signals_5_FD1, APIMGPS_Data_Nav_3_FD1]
BO_ 529 APIM_Request_Signals_5_FD1: 8 GWM
 SG_ OnbChrgToPcWknd_D_Actl : 2|3@0+ (1,0) [0|7] "percent"  SOBDMC_HPCM_FD1
 SG_ OnbChrgToPcWkdy_D_Actl : 60|3@0+ (1,0) [0|7] "percent"  SOBDMC_HPCM_FD1
 SG_ OnbChrgSetNow_D_Rq : 63|2@0+ (1,0) [0|3] "SED"  SOBDMC_HPCM_FD1
 SG_ OnbChrgSetDelete_B_Rq : 3|1@0+ (1,0) [0|1] "SED"  SOBDMC_HPCM_FD1
 SG_ OnbChrgPrflWknd_No_Rq : 39|24@0+ (1,0) [0|16777215] "unitless"  SOBDMC_HPCM_FD1
 SG_ OnbChrgPrflWkdy_No_Rq : 15|24@0+ (1,0) [0|16777215] "unitless"  SOBDMC_HPCM_FD1
 SG_ OnbChrgPrflUpdate_B_Rq : 56|1@0+ (1,0) [0|1] "SED"  SOBDMC_HPCM_FD1
 SG_ OnbChrgLocIdUns_B_Rq : 57|1@0+ (1,0) [0|1] "SED"  SOBDMC_HPCM_FD1
 SG_ OnbChrgLocIdTrgt_No_Rq : 7|4@0+ (1,0) [0|15] "Unitless"  SOBDMC_HPCM_FD1

BO_ 66 Global_PATS_Ctrl_Info2_FD1: 8 GWM
 SG_ immoControlData_T2 : 15|40@0+ (1,0) [0|1099511627775] "Encrypted"  SOBDMC_HPCM_FD1
 SG_ immoControlCmd_T2 : 7|3@0+ (1,0) [0|7] "SED"  SOBDMC_HPCM_FD1

BO_ 2610971864 PARSEDPhysGWMtoSOBDMC_FD1: 8 GWM
 SG_ PARSEDPhysGWM_ECGtoHPCM : 7|29@0+ (1,0) [0|536870911] "unitless"  SOBDMC_HPCM_FD1

BO_ 2612002008 PARSEDFuncGWM_ECG_FD1: 8 GWM
 SG_ PARSEDFuncGWM_ECG : 7|29@0+ (1,0) [0|536870911] "unitless"  ABS_ESC,IPMA_ADAS,ECM_Diesel,PCM_HEV,PCM,SOBDMC_HPCM_FD1

BO_ 2609923288 OTAPhysGWM_ECGtoSOBDMC_FD1: 8 GWM
 SG_ OTAPhysGWM_ECGtoHPCM : 7|29@0+ (1,0) [0|536870911] "unitless"  SOBDMC_HPCM_FD1

BO_ 2610953432 OTAFuncGWM_ECG_FD1: 8 GWM
 SG_ OTAFuncGWM_ECG : 7|29@0+ (1,0) [0|536870911] "unitless"  ABS_ESC,IPMA_ADAS,ECM_Diesel,PCM_HEV,PCM,SOBDMC_HPCM_FD1

BO_ 2022 TesterPhysicalReqSOBDMC_FD: 64 TSTR
 SG_ TesterPhysicalReqSOBDMC : 7|64@0+ (1,0) [0|1.84467E+019] "unitless"  SOBDMC_HPCM_FD1

BO_ 1124 APIMGPS_Data_Nav_3_FD1: 8 GWM
 SG_ GPS_Vdop : 63|5@0+ (0.2,0) [0|5.8] "unitless"  IPMA_ADAS
 SG_ GPS_Speed : 47|8@0+ (1,0) [0|253] "MPH" Vector__XXX
 SG_ GPS_Sat_num_in_view : 7|5@0+ (1,0) [0|29] "unitless"  SOBDMC_HPCM_FD1
 SG_ GPS_MSL_altitude : 15|12@0+ (10,-20460) [-20460|20470] "feet" Vector__XXX
 SG_ GPS_Heading : 31|16@0+ (0.01,0) [0|655.33] "Degrees"  IPMA_ADAS
 SG_ GPS_Hdop : 55|5@0+ (0.2,0) [0|5.8] "unitless"  IPMA_ADAS
 SG_ GPS_dimension : 2|3@0+ (1,0) [0|7] "SED"  SOBDMC_HPCM_FD1

BO_ 1119 Voltage_Power_Data2_FD1: 8 GWM
 SG_ CoolFanDcdc_D_Rq : 5|2@0+ (1,0) [0|3] "SED"  SOBDMC_HPCM_FD1
 SG_ DcdcClntFlw_D_Rq : 7|2@0+ (1,0) [0|3] "SED"  SOBDMC_HPCM_FD1

BO_ 132 GlobalClock_Data_FD1: 16 GWM
 SG_ GlblClkYr_No_Actl : 7|8@0+ (1,2000) [2000|2255] "year"  CMR_DSMC,SOBDMC_HPCM_FD1,IPMA_ADAS
 SG_ GlblClkScnd_No_Actl : 47|8@0+ (1,0) [0|255] "second"  CMR_DSMC,SOBDMC_HPCM_FD1,IPMA_ADAS
 SG_ GlblClkMnte_No_Actl : 39|8@0+ (1,0) [0|255] "minute"  CMR_DSMC,SOBDMC_HPCM_FD1,IPMA_ADAS
 SG_ GlblClkHr_No_Actl : 55|8@0+ (1,0) [0|255] "hour"  CMR_DSMC,SOBDMC_HPCM_FD1,IPMA_ADAS
 SG_ GlblClkDay_No_Actl : 23|16@0+ (1,0) [0|65535] "julian day"  CMR_DSMC,SOBDMC_HPCM_FD1,IPMA_ADAS

BO_ 1990 TesterPhysicalReqSODR: 64 TSTR
 SG_ TesterPhysicalReqSODR : 7|64@0+ (1,0) [0|1.84467E+019] "unitless"  IPMA_ADAS

BO_ 1892 TesterPhysicalReqCCM: 64 TSTR
 SG_ TesterPhysicalReqCCM : 7|64@0+ (1,0) [0|1.84467E+019] "unitless"  IPMA_ADAS

BO_ 1798 TesterPhysicalReqIPMA: 64 TSTR
 SG_ TesterPhysicalReqIPMA : 7|64@0+ (1,0) [0|1.84467E+019] "unitless"  IPMA_ADAS

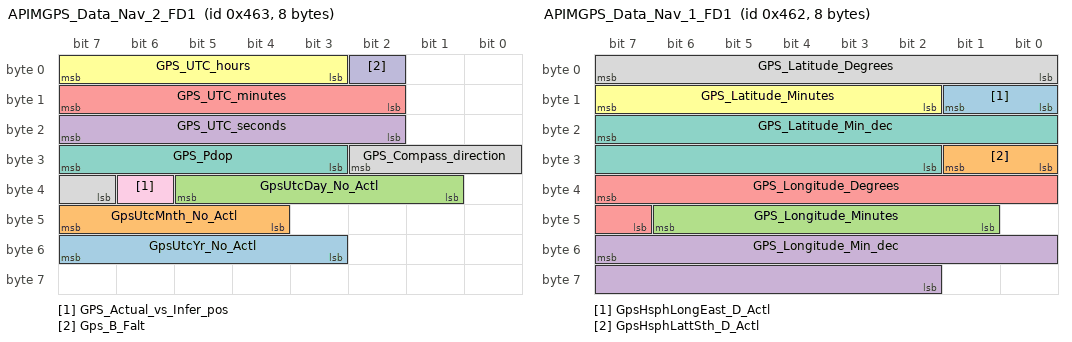
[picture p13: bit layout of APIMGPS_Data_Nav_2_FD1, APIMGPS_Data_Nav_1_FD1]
BO_ 1123 APIMGPS_Data_Nav_2_FD1: 8 GWM
 SG_ GpsUtcYr_No_Actl : 55|5@0+ (1,2010) [2010|2040] "Year"  IPMA_ADAS
 SG_ GpsUtcMnth_No_Actl : 47|4@0+ (1,1) [1|15] "Month"  IPMA_ADAS
 SG_ GpsUtcDay_No_Actl : 37|5@0+ (1,1) [1|32] "Day"  IPMA_ADAS
 SG_ GPS_UTC_seconds : 23|6@0+ (1,0) [0|59] "seconds"  SOBDMC_HPCM_FD1,IPMA_ADAS
 SG_ GPS_UTC_minutes : 15|6@0+ (1,0) [0|59] "Minutes"  IPMA_ADAS
 SG_ GPS_UTC_hours : 7|5@0+ (1,0) [0|23] "Hours"  IPMA_ADAS
 SG_ GPS_Pdop : 31|5@0+ (0.2,0) [0|5.8] "unitless"  IPMA_ADAS
 SG_ GPS_Compass_direction : 26|4@0+ (1,0) [0|15] "SED"  IPMA_ADAS
 SG_ GPS_Actual_vs_Infer_pos : 38|1@0+ (1,0) [0|1] "SED"  SOBDMC_HPCM_FD1,IPMA_ADAS
 SG_ Gps_B_Falt : 2|1@0+ (1,0) [0|1] "SED"  SOBDMC_HPCM_FD1,IPMA_ADAS

BO_ 1122 APIMGPS_Data_Nav_1_FD1: 8 GWM
 SG_ GpsHsphLongEast_D_Actl : 9|2@0+ (1,0) [0|3] "SED"  IPMA_ADAS,SOBDMC_HPCM_FD1
 SG_ GpsHsphLattSth_D_Actl : 25|2@0+ (1,0) [0|3] "SED"  IPMA_ADAS,SOBDMC_HPCM_FD1
 SG_ GPS_Longitude_Minutes : 46|6@0+ (1,0) [0|61] "Minutes"  SOBDMC_HPCM_FD1,IPMA_ADAS
 SG_ GPS_Longitude_Min_dec : 55|14@0+ (0.0001,0) [0|1.6381] "Minutes"  SOBDMC_HPCM_FD1,IPMA_ADAS
 SG_ GPS_Longitude_Degrees : 39|9@0+ (1,-179) [-179|330] "Degrees"  SOBDMC_HPCM_FD1,IPMA_ADAS
 SG_ GPS_Latitude_Minutes : 15|6@0+ (1,0) [0|61] "Minutes"  SOBDMC_HPCM_FD1,IPMA_ADAS
 SG_ GPS_Latitude_Min_dec : 23|14@0+ (0.0001,0) [0|1.6381] "Minutes"  SOBDMC_HPCM_FD1,IPMA_ADAS
 SG_ GPS_Latitude_Degrees : 7|8@0+ (1,-89) [-89|164] "Degrees"  SOBDMC_HPCM_FD1,IPMA_ADAS

BO_ 1003 Personality_BCM2_Data_FD1: 16 GWM
 SG_ PersRecallSrc_D_Actl : 63|3@0+ (1,0) [0|7] "SED" Vector__XXX
 SG_ Pers4Key_D_Stat : 49|2@0+ (1,0) [0|3] "SED" Vector__XXX
 SG_ Pers3Key_D_Stat : 41|2@0+ (1,0) [0|3] "SED" Vector__XXX
 SG_ Pers2Key_D_Stat : 43|2@0+ (1,0) [0|3] "SED" Vector__XXX
 SG_ Pers1Key_D_Stat : 12|2@0+ (1,0) [0|3] "SED" Vector__XXX
 SG_ EmPrflNo_D_Stat : 52|3@0+ (1,0) [0|7] "SED" Vector__XXX
 SG_ EmPrflKeyAssoc_D_Stat : 55|3@0+ (1,0) [0|7] "SED" Vector__XXX
 SG_ VehKeyActv_D_Stat : 47|4@0+ (1,0) [0|15] "SED" Vector__XXX
 SG_ PersNoPos_D_Actl : 18|3@0+ (1,0) [0|7] "SED" Vector__XXX
 SG_ PersSetupRestr_D_Actl : 21|2@0+ (1,0) [0|3] "SED" Vector__XXX
 SG_ PersSetupAccessCtrl : 19|1@0+ (1,0) [0|1] "SED" Vector__XXX
 SG_ PersSetup_No_Actl : 31|16@0+ (1,0) [0|65535] "Number" Vector__XXX
 SG_ PersConflict_D_Actl : 22|1@0+ (1,0) [0|1] "SED" Vector__XXX
 SG_ AssocConfirm_D_Actl : 15|3@0+ (1,0) [0|7] "SED" Vector__XXX
 SG_ RecallEvent_No_Cnt : 7|8@0+ (1,0) [0|255] "Counts"  IPMA_ADAS
 SG_ PersNo_D_Actl : 10|3@0+ (1,0) [0|7] "SED"  ABS_ESC,IPMA_ADAS

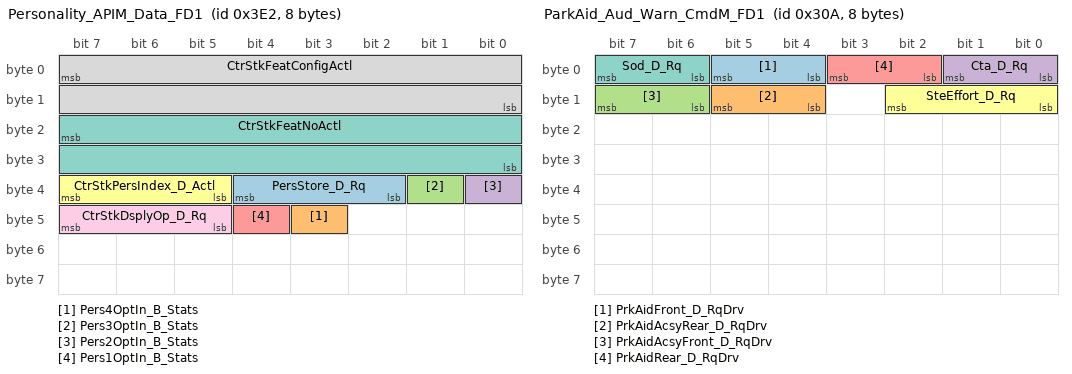
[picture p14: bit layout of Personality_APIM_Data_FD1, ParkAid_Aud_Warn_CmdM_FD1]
BO_ 994 Personality_APIM_Data_FD1: 8 GWM
 SG_ PersStore_D_Rq : 36|3@0+ (1,0) [0|7] "SED" Vector__XXX
 SG_ Pers4OptIn_B_Stats : 43|1@0+ (1,0) [0|1] "SED" Vector__XXX
 SG_ Pers3OptIn_B_Stats : 33|1@0+ (1,0) [0|1] "SED" Vector__XXX
 SG_ Pers2OptIn_B_Stats : 32|1@0+ (1,0) [0|1] "SED" Vector__XXX
 SG_ Pers1OptIn_B_Stats : 44|1@0+ (1,0) [0|1] "SED" Vector__XXX
 SG_ CtrStkPersIndex_D_Actl : 39|3@0+ (1,0) [0|7] "SED"  ABS_ESC,IPMA_ADAS
 SG_ CtrStkFeatNoActl : 23|16@0+ (1,0) [0|65535] "Undefined"  ABS_ESC,IPMA_ADAS
 SG_ CtrStkFeatConfigActl : 7|16@0+ (1,0) [0|65535] "Undefined"  ABS_ESC,IPMA_ADAS
 SG_ CtrStkDsplyOp_D_Rq : 47|3@0+ (1,0) [0|7] "SED"  ABS_ESC,IPMA_ADAS

BO_ 778 ParkAid_Aud_Warn_CmdM_FD1: 8 GWM
 SG_ PrkAidFront_D_RqDrv : 5|2@0+ (1,0) [0|3] "SED"  IPMA_ADAS
 SG_ PrkAidAcsyRear_D_RqDrv : 13|2@0+ (1,0) [0|3] "SED"  IPMA_ADAS
 SG_ PrkAidAcsyFront_D_RqDrv : 15|2@0+ (1,0) [0|3] "SED"  IPMA_ADAS
 SG_ Cta_D_Rq : 1|2@0+ (1,0) [0|3] "SED"  IPMA_ADAS
 SG_ PrkAidRear_D_RqDrv : 3|2@0+ (1,0) [0|3] "SED"  IPMA_ADAS
 SG_ SteEffort_D_Rq : 10|3@0+ (1,0) [0|7] "SED" Vector__XXX
 SG_ Sod_D_Rq : 7|2@0+ (1,0) [0|3] "SED"  IPMA_ADAS

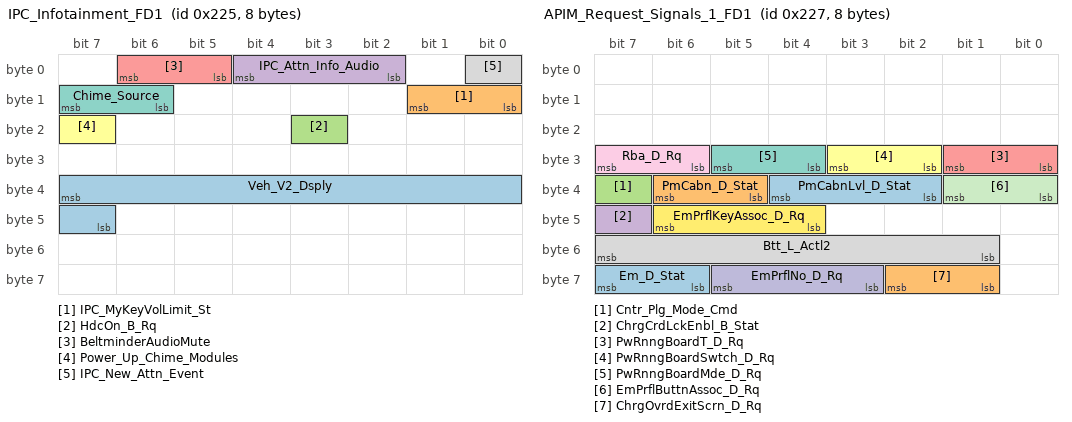
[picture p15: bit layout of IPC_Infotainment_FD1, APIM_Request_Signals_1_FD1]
BO_ 549 IPC_Infotainment_FD1: 8 GWM
 SG_ Veh_V2_Dsply : 39|9@0+ (1,0) [0|511] "unitless"  IPMA_ADAS
 SG_ IPC_MyKeyVolLimit_St : 9|2@0+ (1,0) [0|3] "SED" Vector__XXX
 SG_ HdcOn_B_Rq : 19|1@0+ (1,0) [0|1] "SED" Vector__XXX
 SG_ IPC_Attn_Info_Audio : 4|3@0+ (1,0) [0|7] "SED" Vector__XXX
 SG_ BeltminderAudioMute : 6|2@0+ (1,0) [0|3] "SED" Vector__XXX
 SG_ Power_Up_Chime_Modules : 23|1@0+ (1,0) [0|1] "SED" Vector__XXX
 SG_ Chime_Source : 15|2@0+ (1,0) [0|3] "SED" Vector__XXX
 SG_ IPC_New_Attn_Event : 0|1@0+ (1,0) [0|1] "SED" Vector__XXX

BO_ 551 APIM_Request_Signals_1_FD1: 8 GWM
 SG_ PmCabnLvl_D_Stat : 36|3@0+ (1,0) [0|7] "SED" Vector__XXX
 SG_ PmCabn_D_Stat : 38|2@0+ (1,0) [0|3] "SED" Vector__XXX
 SG_ Cntr_Plg_Mode_Cmd : 39|1@0+ (1,0) [0|1] "SED" Vector__XXX
 SG_ ChrgCrdLckEnbl_B_Stat : 47|1@0+ (1,0) [0|1] "SED" Vector__XXX
 SG_ PwRnngBoardT_D_Rq : 25|2@0+ (1,0) [0|3] "SED" Vector__XXX
 SG_ PwRnngBoardSwtch_D_Rq : 27|2@0+ (1,0) [0|3] "SED" Vector__XXX
 SG_ PwRnngBoardMde_D_Rq : 29|2@0+ (1,0) [0|3] "SED" Vector__XXX
 SG_ Btt_L_Actl2 : 55|7@0+ (0.1,0) [0|12.5] "meter"  IPMA_ADAS
 SG_ Rba_D_Rq : 31|2@0+ (1,0) [0|3] "SED"  IPMA_ADAS
 SG_ EmPrflNo_D_Rq : 61|3@0+ (1,0) [0|7] "SED" Vector__XXX
 SG_ EmPrflButtnAssoc_D_Rq : 33|2@0+ (1,0) [0|3] "SED" Vector__XXX
 SG_ EmPrflKeyAssoc_D_Rq : 46|3@0+ (1,0) [0|7] "SED" Vector__XXX
 SG_ Em_D_Stat : 63|2@0+ (1,0) [0|3] "SED" Vector__XXX
 SG_ ChrgOvrdExitScrn_D_Rq : 58|2@0+ (1,0) [0|3] "SED" Vector__XXX

BO_ 1010 IPMA_Data3: 16 IPMA_ADAS
 SG_ MbdblActv_B_RqAdas : 48|1@0+ (1,0) [0|1] "SED"  GWM
 SG_ CbdblActv_B_RqAdas : 49|1@0+ (1,0) [0|1] "SED"  GWM
 SG_ AdbUrbanArea_B_Stat : 40|1@0+ (1,0) [0|1] "SED"  GWM
 SG_ LightRng_L_Max : 55|6@0+ (2,0) [0|126] "meter"  GWM
 SG_ LightPathOffst_L_Actl : 31|10@0+ (0.01,-5.12) [-5.12|5.11] "meter"  GWM
 SG_ LightPath_An_Actl : 12|11@0+ (0.0005,-0.5) [-0.5|0.5235] "radians"  GWM
 SG_ LightCurv_NoRate_Actl : 37|13@0+ (2.5E-007,-0.001024) [-0.001024|0.00102375] "1/meter"  GWM
 SG_ LightCurv_No_Actl : 7|11@0+ (2E-005,-0.02) [-0.02|0.02094] "1/meter"  GWM

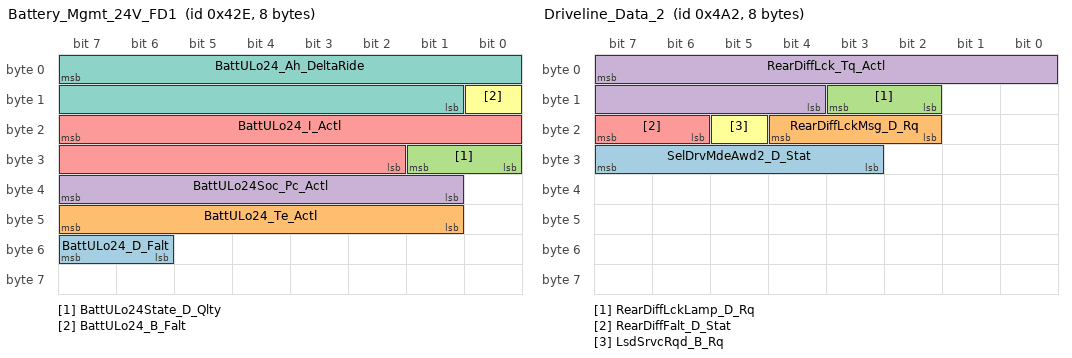
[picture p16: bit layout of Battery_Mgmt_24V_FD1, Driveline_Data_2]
BO_ 1070 Battery_Mgmt_24V_FD1: 8 GWM
 SG_ BattULo24_D_Falt : 55|2@0+ (1,0) [0|3] "SED"  PCM
 SG_ BattULo24_Te_Actl : 47|7@0+ (1,-40) [-40|86] "degC"  PCM
 SG_ BattULo24State_D_Qlty : 25|2@0+ (1,0) [0|3] "SED"  PCM
 SG_ BattULo24Soc_Pc_Actl : 39|7@0+ (1,0) [0|127] "percent"  PCM
 SG_ BattULo24_I_Actl : 23|14@0+ (0.0625,-512) [-512|511.875] "ampere"  PCM
 SG_ BattULo24_B_Falt : 8|1@0+ (1,0) [0|1] "SED"  PCM
 SG_ BattULo24_Ah_DeltaRide : 7|15@0+ (0.0078125,-100) [-100|155.9921875] "amperehour"  PCM

BO_ 1186 Driveline_Data_2: 8 TCCM
 SG_ SelDrvMdeAwd2_D_Stat : 31|5@0+ (1,0) [0|31] "SED"  ABS_ESC,GWM
 SG_ RearDiffLckMsg_D_Rq : 20|3@0+ (1,0) [0|7] "SED"  GWM
 SG_ RearDiffLckLamp_D_Rq : 11|2@0+ (1,0) [0|3] "SED"  VDM,GWM,ABS_ESC
 SG_ RearDiffLck_Tq_Actl : 7|12@0+ (1,0) [0|4093] "Nm"  ABS_ESC,ECM_Diesel,PCM,PCM_HEV,GWM
 SG_ RearDiffFalt_D_Stat : 23|2@0+ (1,0) [0|3] "SED"  ABS_ESC,GWM
 SG_ LsdSrvcRqd_B_Rq : 21|1@0+ (1,0) [0|1] "SED"  GWM

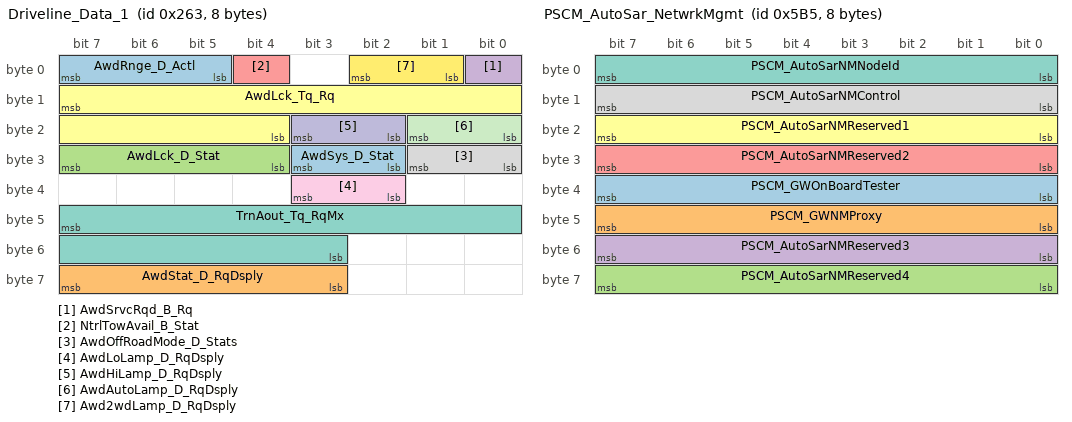
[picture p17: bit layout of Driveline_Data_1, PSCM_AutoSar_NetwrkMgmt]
BO_ 611 Driveline_Data_1: 8 TCCM
 SG_ AwdSys_D_Stat : 27|2@0+ (1,0) [0|3] "SED"  GWM,ECM_Diesel,PCM,PCM_HEV
 SG_ AwdStat_D_RqDsply : 63|5@0+ (1,0) [0|31] "SED"  TCM_DSL,ABS_ESC,GWM
 SG_ AwdLck_D_Stat : 31|4@0+ (1,0) [0|15] "SED"  TCM_DSL,GWM,ABS_ESC
 SG_ AwdSrvcRqd_B_Rq : 0|1@0+ (1,0) [0|1] "SED"  GWM,PCM,PCM_HEV,TCM_DSL,ABS_ESC
 SG_ NtrlTowAvail_B_Stat : 4|1@0+ (1,0) [0|1] "SED"  GWM
 SG_ AwdLck_Tq_Rq : 15|12@0+ (1,0) [0|4093] "Nm"  PCM_HEV,GWM,ABS_ESC
 SG_ TrnAout_Tq_RqMx : 47|13@0+ (1,-1250) [-1250|6941] "Nm"  GWM,ECM_Diesel,PCM,PCM_HEV
 SG_ AwdOffRoadMode_D_Stats : 25|2@0+ (1,0) [0|3] "SED"  IPMA_ADAS,GWM
 SG_ AwdLoLamp_D_RqDsply : 35|2@0+ (1,0) [0|3] "SED"  GWM
 SG_ AwdHiLamp_D_RqDsply : 19|2@0+ (1,0) [0|3] "SED"  GWM,ABS_ESC
 SG_ AwdAutoLamp_D_RqDsply : 17|2@0+ (1,0) [0|3] "SED"  GWM,ABS_ESC
 SG_ Awd2wdLamp_D_RqDsply : 2|2@0+ (1,0) [0|3] "SED"  GWM
 SG_ AwdRnge_D_Actl : 7|3@0+ (1,0) [0|7] "SED"  VDM,ECM_Diesel,PCM,PCM_HEV,TCM_DSL,ABS_ESC,GWM,IPMA_ADAS

BO_ 1461 PSCM_AutoSar_NetwrkMgmt: 8 PSCM
 SG_ PSCM_GWOnBoardTester : 39|8@0+ (1,0) [0|255] "unitless"  GWM,ABS_ESC
 SG_ PSCM_GWNMProxy : 47|8@0+ (1,0) [0|255] "unitless"  GWM,ABS_ESC
 SG_ PSCM_AutoSarNMReserved4 : 63|8@0+ (1,0) [0|255] "unitless"  GWM,ABS_ESC
 SG_ PSCM_AutoSarNMReserved3 : 55|8@0+ (1,0) [0|255] "unitless"  GWM,ABS_ESC
 SG_ PSCM_AutoSarNMReserved2 : 31|8@0+ (1,0) [0|255] "unitless"  GWM,ABS_ESC
 SG_ PSCM_AutoSarNMReserved1 : 23|8@0+ (1,0) [0|255] "unitless"  GWM,ABS_ESC
 SG_ PSCM_AutoSarNMNodeId : 7|8@0+ (1,0) [0|255] "unitless"  GWM,ABS_ESC
 SG_ PSCM_AutoSarNMControl : 15|8@0+ (1,0) [0|255] "unitless"  GWM,ABS_ESC

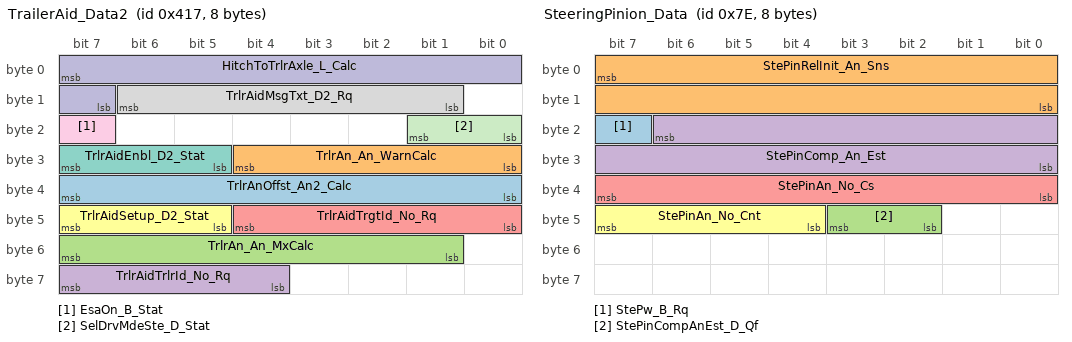
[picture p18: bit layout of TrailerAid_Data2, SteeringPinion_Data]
BO_ 1047 TrailerAid_Data2: 8 PSCM
 SG_ TrlrAnOffst_An2_Calc : 39|8@0+ (0.5,-64) [-64|63.5] "degrees"  IPMA_ADAS
 SG_ TrlrAn_An_WarnCalc : 28|5@0+ (1,0) [0|31] "degrees"  IPMA_ADAS
 SG_ TrlrAn_An_MxCalc : 55|7@0+ (1,0) [0|127] "degrees"  IPMA_ADAS
 SG_ TrlrAidTrlrId_No_Rq : 63|4@0+ (1,0) [0|15] "unitless"  GWM
 SG_ TrlrAidTrgtId_No_Rq : 44|5@0+ (1,0) [0|31] "unitless"  IPMA_ADAS
 SG_ TrlrAidSetup_D2_Stat : 47|3@0+ (1,0) [0|7] "SED"  IPMA_ADAS
 SG_ TrlrAidEnbl_D2_Stat : 31|3@0+ (1,0) [0|7] "SED"  ABS_ESC,IPMA_ADAS,GWM,PCM,ECM_Diesel
 SG_ TrlrAidMsgTxt_D2_Rq : 14|6@0+ (1,0) [0|63] "SED"  IPMA_ADAS,GWM,ABS_ESC
 SG_ EsaOn_B_Stat : 23|1@0+ (1,0) [0|1] "SED"  GWM
 SG_ HitchToTrlrAxle_L_Calc : 7|9@0+ (0.0254,0) [0|12.9794] "meter"  IPMA_ADAS
 SG_ SelDrvMdeSte_D_Stat : 17|2@0+ (1,0) [0|3] "SED"  ABS_ESC

BO_ 972 Lane_Assist_Data3_FD1: 16 PSCM
 SG_ LatCtlSte_D_Stat : 18|3@0+ (1,0) [0|7] "SED"  IPMA_ADAS,GWM
 SG_ LatCtlLim_D_Stat : 33|2@0+ (1,0) [0|3] "SED"  IPMA_ADAS,GWM
 SG_ LatCtlCpblty_D_Stat : 39|2@0+ (1,0) [0|3] "SED"  IPMA_ADAS,GWM
 SG_ LatCtlCpbltyDStat_No_Cnt : 37|4@0+ (1,0) [0|15] "Unitless"  IPMA_ADAS,GWM
 SG_ LatCtlCpbltyDStat_No_Cs : 47|8@0+ (1,0) [0|255] "Unitless"  IPMA_ADAS,GWM
 SG_ TrlrAn_An_TrgtCalc : 31|8@0+ (1,-128) [-128|127] "degrees"  IPMA_ADAS
 SG_ LsmcBrkDecelEnbl_D_Rq : 1|2@0+ (1,0) [0|3] "SED"  ABS_ESC
 SG_ TjaHandsOnCnfdnc_B_Est : 3|1@0+ (1,0) [0|1] "SED"  IPMA_ADAS
 SG_ LaHandsOff_B_Actl : 7|1@0+ (1,0) [0|1] "SED"  IPMA_ADAS,GWM
 SG_ LaActDeny_B_Actl : 6|1@0+ (1,0) [0|1] "SED"  IPMA_ADAS,GWM
 SG_ LaActAvail_D_Actl : 5|2@0+ (1,0) [0|3] "SED"  IPMA_ADAS,GWM
 SG_ LsmcBrk_Tq_Rq : 15|13@0+ (4,0) [0|32764] "Nm"  ABS_ESC

BO_ 130 EPAS_INFO: 16 PSCM
 SG_ TrlrHitchLamp_D_Rqst : 24|1@0+ (1,0) [0|1] "SED"  IPMA_ADAS,GWM
 SG_ VehVTrlrAid_B_Rq : 25|1@0+ (1,0) [0|1] "SED"  PCM_HEV,GWM,ECM_Diesel,PCM
 SG_ Veh_V_RqMxTrlrAid : 63|8@0+ (0.1,0) [0|25.5] "km/h"  PCM_HEV,GWM,ECM_Diesel,PCM
 SG_ DrvSteActv_B_Stat : 10|1@0+ (1,0) [0|1] "SED"  GWM,ABS_ESC
 SG_ DrvSte_Tq_Actl : 47|8@0+ (0.0625,-8) [-8|7.8125] "Nm"  GWM,ABS_ESC
 SG_ SteMdule_D_Stat : 55|3@0+ (1,0) [0|7] "SED"  GWM
 SG_ SteMdule_U_Meas : 39|8@0+ (0.05,6) [6|18.7] "Volts"  GWM
 SG_ SteMdule_I_Est : 21|12@0+ (0.05,-64) [-64|140.7] "Amps"  GWM
 SG_ EPAS_Failure : 9|2@0+ (1,0) [0|3] "SED"  IPMA_ADAS,GWM
 SG_ SteeringColumnTorque : 7|8@0+ (0.0625,-8) [-8|7.8125] "Nm"  GWM,IPMA_ADAS,ABS_ESC
 SG_ SAPPAngleControlStat6 : 15|1@0+ (1,0) [0|1] "SED"  GWM,IPMA_ADAS
 SG_ SAPPAngleControlStat5 : 14|1@0+ (1,0) [0|1] "SED"  GWM,IPMA_ADAS
 SG_ SAPPAngleControlStat4 : 13|1@0+ (1,0) [0|1] "SED"  GWM,IPMA_ADAS
 SG_ SAPPAngleControlStat3 : 12|1@0+ (1,0) [0|1] "SED"  GWM,IPMA_ADAS
 SG_ SAPPAngleControlStat2 : 11|1@0+ (1,0) [0|1] "SED"  GWM,IPMA_ADAS
 SG_ SAPPAngleControlStat1 : 23|2@0+ (1,0) [0|3] "SED"  GWM,IPMA_ADAS

BO_ 126 SteeringPinion_Data: 8 PSCM
 SG_ StePw_B_Rq : 23|1@0+ (1,0) [0|1] "SED"  GWM,ECM_Diesel,PCM
 SG_ StePinRelInit_An_Sns : 7|16@0+ (0.1,-3200) [-3200|3353.3] "degrees"  VDM,IPMA_ADAS,GWM,ECM_Diesel,PCM,PCM_HEV,ABS_ESC,TCCM
 SG_ StePinCompAnEst_D_Qf : 43|2@0+ (1,0) [0|3] "SED"  VDM,CMR_DSMC,IPMA_ADAS,TCM_DSL,ECM_Diesel,PCM,PCM_HEV,ABS_ESC,TCCM,GWM
 SG_ StePinComp_An_Est : 22|15@0+ (0.1,-1600) [-1600|1676.7] "degrees"  VDM,CMR_DSMC,IPMA_ADAS,TCM_DSL,ECM_Diesel,PCM,PCM_HEV,ABS_ESC,TCCM,GWM
 SG_ StePinAn_No_Cs : 39|8@0+ (1,0) [0|255] "Unitless"  VDM,ABS_ESC,TCCM,GWM
 SG_ StePinAn_No_Cnt : 47|4@0+ (1,0) [0|15] "unitless"  VDM,TCCM,GWM,ABS_ESC

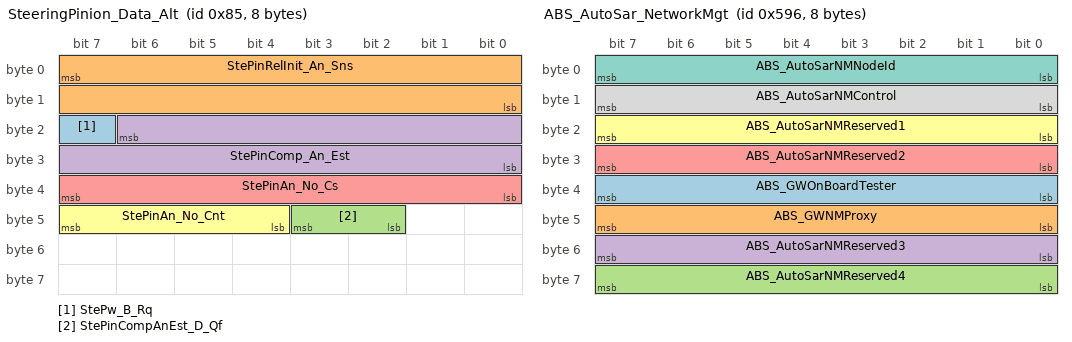
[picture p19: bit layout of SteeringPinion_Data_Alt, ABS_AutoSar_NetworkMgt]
BO_ 133 SteeringPinion_Data_Alt: 8 PSCM
 SG_ StePw_B_Rq : 23|1@0+ (1,0) [0|1] "SED"  GWM,ECM_Diesel,PCM
 SG_ StePinRelInit_An_Sns : 7|16@0+ (0.1,-3200) [-3200|3353.3] "degrees"  VDM,IPMA_ADAS,GWM,ECM_Diesel,PCM,PCM_HEV,ABS_ESC,TCCM
 SG_ StePinCompAnEst_D_Qf : 43|2@0+ (1,0) [0|3] "SED"  VDM,CMR_DSMC,IPMA_ADAS,TCM_DSL,ECM_Diesel,PCM,PCM_HEV,ABS_ESC,TCCM,GWM
 SG_ StePinComp_An_Est : 22|15@0+ (0.1,-1600) [-1600|1676.7] "degrees"  VDM,CMR_DSMC,IPMA_ADAS,TCM_DSL,ECM_Diesel,PCM,PCM_HEV,ABS_ESC,TCCM,GWM
 SG_ StePinAn_No_Cs : 39|8@0+ (1,0) [0|255] "Unitless"  VDM,ABS_ESC,TCCM,GWM
 SG_ StePinAn_No_Cnt : 47|4@0+ (1,0) [0|15] "unitless"  VDM,TCCM,GWM,ABS_ESC

BO_ 1430 ABS_AutoSar_NetworkMgt: 8 ABS_ESC
 SG_ ABS_GWOnBoardTester : 39|8@0+ (1,0) [0|255] "unitless"  GWM
 SG_ ABS_GWNMProxy : 47|8@0+ (1,0) [0|255] "unitless"  GWM
 SG_ ABS_AutoSarNMReserved4 : 63|8@0+ (1,0) [0|255] "unitless"  GWM
 SG_ ABS_AutoSarNMReserved3 : 55|8@0+ (1,0) [0|255] "unitless"  GWM
 SG_ ABS_AutoSarNMReserved2 : 31|8@0+ (1,0) [0|255] "unitless"  GWM
 SG_ ABS_AutoSarNMReserved1 : 23|8@0+ (1,0) [0|255] "unitless"  GWM
 SG_ ABS_AutoSarNMNodeId : 7|8@0+ (1,0) [0|255] "unitless"  GWM
 SG_ ABS_AutoSarNMControl : 15|8@0+ (1,0) [0|255] "unitless"  GWM

BO_TX_BU_ 1085 : ECM_Diesel,PCM;
BO_TX_BU_ 2611175440 : ECM_Diesel,PCM_HEV,PCM;
BO_TX_BU_ 2610126864 : ECM_Diesel,PCM_HEV,PCM;
BO_TX_BU_ 786 : PCM_HEV,SOBDMC_HPCM_FD1;
CM_ SG_ 1104 DrvEngageLevel_No_Cs "Signal not transmitted on gas variants.";
CM_ SG_ 1104 DrvEngageLevel_No_Cnt "Signal not transmitted on gas variants.";
CM_ SG_ 1085 ULoRgenTestMde_B_Stat "Signal not transmitted on HEV variants.";
CM_ SG_ 1085 PwSrcULoComm_B_Falt "Signal not transmitted on HEV variants.";
CM_ SG_ 1445 SOBDMC_AutoSarNMReserved4 "Signal not transmitted on gas and diesel variants.";
CM_ SG_ 1445 SOBDMC_AutoSarNMReserved3 "Signal not transmitted on gas and diesel variants.";
CM_ SG_ 1445 SOBDMC_AutoSarNMReserved2 "Signal not transmitted on gas and diesel variants.";
CM_ SG_ 1445 SOBDMC_AutoSarNMReserved1 "Signal not transmitted on gas and diesel variants.";
CM_ SG_ 1445 SOBDMC_AutoSarNMNodeId "Signal not transmitted on gas and diesel variants.";
CM_ SG_ 1445 SOBDMC_AutoSarNMControl "Signal not transmitted on gas and diesel variants.";
CM_ SG_ 1088 HvacPrecondMode2_D_Rq "Signal not transmitted on vehicles that do not have the Fuel operated heater feature.";
CM_ SG_ 1088 HvacPrecondBlwr2_D_Rq "Signal not transmitted on vehicles that do not have the Fuel operated heater feature.";
CM_ SG_ 786 ChrgStat_D_Dsply "Signal not transmitted by PCM_HEV";
CM_ SG_ 66 immoControlData_T2 "Not transmitted on all vehicle variants";
CM_ SG_ 66 immoControlCmd_T2 "Not transmitted on all vehicle variants";
CM_ SG_ 549 BeltminderAudioMute "Object.MyKey.BeltMinderAudioMute.St";
CM_ SG_ 549 Power_Up_Chime_Modules "Object.AlertMethod.IPC _Infotainment";
CM_ SG_ 549 Chime_Source "Object.AlertMethod.IPC_infotainment";
CM_ SG_ 611 AwdStat_D_RqDsply "Signal not transmitted on programs that do not have AWD.";
CM_ SG_ 611 AwdSrvcRqd_B_Rq "Signal not transmitted on programs that do not have AWD.";
CM_ SG_ 611 AwdLck_Tq_Rq "Signal not transmitted on programs that do not have AWD.";
CM_ SG_ 130 VehVTrlrAid_B_Rq "VR session start- req. limit blower speed no more than X volts.  CC restriction on time msg. will be honored.Double Event msg1st event to request limit, 2nd event to release limit, No msg. CC Grammar v7.xls";
CM_ SG_ 130 SteMdule_U_Meas "DCR 1745  to update Tx from GWM to EP100ms. SteMdule_I_Est & SteMdule_U_Meas are used by BMS system & filtered. The filter uses standard periodic rate & changing to EP would adversely affect the filter.(jweinfur)";
CM_ SG_ 130 SteMdule_I_Est "DCR 1745  to update Tx from GWM to EP100ms. SteMdule_I_Est & SteMdule_U_Meas are used by BMS system & filtered. The filter uses standard periodic rate & changing to EP would adversely affect the filter.(jweinfur)";
CM_ SG_ 126 StePinRelInit_An_Sns "SASM will transmit these signals on vehicles with SASM and without PSCM.  SCCM will not Tx this signal when SASM is present.";
CM_ SG_ 126 StePinAn_No_Cs "Signal not transmitted on gas variants.";
CM_ BO_ 133 "Seen on Ford Edge MK2";
CM_ SG_ 133 StePinRelInit_An_Sns "SASM will transmit these signals on vehicles with SASM and without PSCM.  SCCM will not Tx this signal when SASM is present.";
CM_ SG_ 133 StePinAn_No_Cs "Signal not transmitted on gas variants.";

BA_DEF_ BO_  "OvtpPushApplication" ENUM  "FALSE","TRUE";
BA_DEF_ SG_  "ECGUsedRxSignal" ENUM  "No","Yes";
BA_DEF_ SG_  "ECGUsedTxSignal" ENUM  "No","Yes";
BA_DEF_ BO_  "VFrameFormat" ENUM  "StandardCAN","ExtendedCAN","reserved","reserved","reserved","reserved","reserved","reserved","reserved","reserved","reserved","reserved","reserved","reserved","StandardCAN_FD","ExtendedCAN_FD";
BA_DEF_ BO_  "FrameRouting" STRING;
BA_DEF_ BO_  "FrameGatewayNetwork" STRING;
BA_DEF_ BO_  "NetworkInitialization" ENUM  "No","Yes";
BA_DEF_ BO_  "FrameGatewayId" HEX 0 1407;
BA_DEF_ BO_  "EventRateOfChange" INT 10 10000;
BA_DEF_ BO_  "GenMsgStartDelayTime" INT 0 10000;
BA_DEF_ BO_  "GenMsgNrOfRepetition" INT 0 100;
BA_DEF_ BO_  "GenMsgDelayTime" INT 0 1000;
BA_DEF_ BO_  "GenMsgCycleTime" INT 0 100000;
BA_DEF_ BO_  "GenMsgSendType" ENUM  "FixedPeriodic","Event","EnabledPeriodic","NotUsed","NotUsed","EventPeriodic","NotUsed","NotUsed","NoMsgSendType";
BA_DEF_ SG_  "U_T6_MCA_MY2020_Tx" ENUM  "No","Yes";
BA_DEF_ SG_  "U_P702_MY2021_Tx" ENUM  "No","Yes";
BA_DEF_ SG_  "U_CX727_MY2021_Tx" ENUM  "No","Yes";
BA_DEF_ SG_  "U_T6_MCA_MY2020_Rx" ENUM  "No","Yes";
BA_DEF_ SG_  "U_P702_MY2021_Rx" ENUM  "No","Yes";
BA_DEF_ SG_  "U_CX727_MY2021_Rx" ENUM  "No","Yes";
BA_DEF_ SG_  "GenSigStartValue" HEX 0 268435455;
BA_DEF_ SG_  "MetaData" ENUM  "No","Yes";
BA_DEF_ SG_  "ContentDependant" ENUM  "No","Yes";
BA_DEF_ SG_  "GenSigStartValueInteger" INT 0 1000000000;
BA_DEF_ SG_  "UsedOnPgmDBC" ENUM  "No","Yes";
BA_DEF_ SG_  "CrossOver_InfoCAN" ENUM  "No","Yes";
BA_DEF_ SG_  "WakeupSignal" ENUM  "No","Yes";
BA_DEF_ SG_  "GenSigInactiveValue" INT 0 100000;
BA_DEF_ SG_  "GenSigSendType" ENUM  "Cyclic","OnWrite","vector_leerstring","OnChange","vector_leerstring","IfActive","vector_leerstring","NoSigSendType";
BA_DEF_ BO_  "SCP_FreshnessValueLength" INT 0 512;
BA_DEF_ BO_  "AuthFreshnessCounterSyncAttempt" INT 0 512;
BA_DEF_ BO_  "SCP_FreshnessValueTxLength" INT 0 512;
BA_DEF_ BO_  "SCP_AuthInfoTxLength" INT 0 512;
BA_DEF_ BO_  "ProgBWConditional" STRING;
BA_DEF_ BO_  "NmAsrMessage" ENUM  "No","Yes";
BA_DEF_ BO_  "TpApplType" STRING;
BA_DEF_ BO_  "DiagState" ENUM  "No","Yes";
BA_DEF_ BO_  "TpTxIndex" INT 0 536870911;
BA_DEF_ BO_  "DiagRequest" ENUM  "No","Yes";
BA_DEF_ BO_  "DiagResponse" ENUM  "No","Yes";
BA_DEF_ BO_  "GenMsgILSupport" ENUM  "No","Yes";
BA_DEF_DEF_  "OvtpPushApplication" "FALSE";
BA_DEF_DEF_  "ECGUsedRxSignal" "No";
BA_DEF_DEF_  "ECGUsedTxSignal" "No";
BA_DEF_DEF_  "VFrameFormat" "ExtendedCAN_FD";
BA_DEF_DEF_  "FrameRouting" "NONE";
BA_DEF_DEF_  "FrameGatewayNetwork" "NONE";
BA_DEF_DEF_  "NetworkInitialization" "Yes";
BA_DEF_DEF_  "FrameGatewayId" 0;
BA_DEF_DEF_  "EventRateOfChange" 10000;
BA_DEF_DEF_  "GenMsgStartDelayTime" 0;
BA_DEF_DEF_  "GenMsgNrOfRepetition" 1;
BA_DEF_DEF_  "GenMsgDelayTime" 20;
BA_DEF_DEF_  "GenMsgCycleTime" 0;
BA_DEF_DEF_  "GenMsgSendType" "NoMsgSendType";
BA_DEF_DEF_  "U_T6_MCA_MY2020_Tx" "No";
BA_DEF_DEF_  "U_P702_MY2021_Tx" "No";
BA_DEF_DEF_  "U_CX727_MY2021_Tx" "No";
BA_DEF_DEF_  "U_T6_MCA_MY2020_Rx" "No";
BA_DEF_DEF_  "U_P702_MY2021_Rx" "No";
BA_DEF_DEF_  "U_CX727_MY2021_Rx" "No";
BA_DEF_DEF_  "GenSigStartValue" 0;
BA_DEF_DEF_  "MetaData" "No";
BA_DEF_DEF_  "ContentDependant" "No";
BA_DEF_DEF_  "GenSigStartValueInteger" 0;
BA_DEF_DEF_  "UsedOnPgmDBC" "Yes";
BA_DEF_DEF_  "CrossOver_InfoCAN" "No";
BA_DEF_DEF_  "WakeupSignal" "No";
BA_DEF_DEF_  "GenSigInactiveValue" 0;
BA_DEF_DEF_  "GenSigSendType" "NoSigSendType";
BA_DEF_DEF_  "SCP_FreshnessValueLength" 64;
BA_DEF_DEF_  "AuthFreshnessCounterSyncAttempt" 2;
BA_DEF_DEF_  "SCP_FreshnessValueTxLength" 8;
BA_DEF_DEF_  "SCP_AuthInfoTxLength" 56;
BA_DEF_DEF_  "ProgBWConditional" "NONE";
BA_DEF_DEF_  "NmAsrMessage" "No";
BA_DEF_DEF_  "TpApplType" "";
BA_DEF_DEF_  "DiagState" "No";
BA_DEF_DEF_  "TpTxIndex" 0;
BA_DEF_DEF_  "DiagRequest" "No";
BA_DEF_DEF_  "DiagResponse" "No";
BA_DEF_DEF_  "GenMsgILSupport" "Yes";
BA_ "TpTxIndex" BO_ 2611055832 463572184;
BA_ "FrameRouting" BO_ 2611055832 "";
BA_ "NetworkInitialization" BO_ 2611055832 0;
BA_ "GenMsgDelayTime" BO_ 2611055832 0;
BA_ "GenMsgSendType" BO_ 2611055832 1;
BA_ "TpTxIndex" BO_ 2611054808 463571160;
BA_ "FrameRouting" BO_ 2611054808 "";
BA_ "NetworkInitialization" BO_ 2611054808 0;
BA_ "GenMsgDelayTime" BO_ 2611054808 0;
BA_ "GenMsgSendType" BO_ 2611054808 1;
BA_ "TpTxIndex" BO_ 2611026136 463542488;
BA_ "FrameRouting" BO_ 2611026136 "";
BA_ "NetworkInitialization" BO_ 2611026136 0;
BA_ "GenMsgDelayTime" BO_ 2611026136 0;
BA_ "GenMsgSendType" BO_ 2611026136 1;
BA_ "TpTxIndex" BO_ 2611025112 463541464;
BA_ "FrameRouting" BO_ 2611025112 "";
BA_ "NetworkInitialization" BO_ 2611025112 0;
BA_ "GenMsgDelayTime" BO_ 2611025112 0;
BA_ "GenMsgSendType" BO_ 2611025112 1;
BA_ "TpTxIndex" BO_ 2610975960 463492312;
BA_ "FrameRouting" BO_ 2610975960 "";
BA_ "NetworkInitialization" BO_ 2610975960 0;
BA_ "GenMsgDelayTime" BO_ 2610975960 0;
BA_ "GenMsgSendType" BO_ 2610975960 1;
BA_ "FrameRouting" BO_ 2610007256 "";
BA_ "NetworkInitialization" BO_ 2610007256 0;
BA_ "GenMsgDelayTime" BO_ 2610007256 0;
BA_ "GenMsgSendType" BO_ 2610007256 1;
BA_ "TpTxIndex" BO_ 2610007256 462523608;
BA_ "FrameRouting" BO_ 2610006232 "";
BA_ "NetworkInitialization" BO_ 2610006232 0;
BA_ "GenMsgDelayTime" BO_ 2610006232 0;
BA_ "GenMsgSendType" BO_ 2610006232 1;
BA_ "TpTxIndex" BO_ 2610006232 462522584;
BA_ "FrameRouting" BO_ 2609977560 "";
BA_ "NetworkInitialization" BO_ 2609977560 0;
BA_ "GenMsgDelayTime" BO_ 2609977560 0;
BA_ "GenMsgSendType" BO_ 2609977560 1;
BA_ "TpTxIndex" BO_ 2609977560 462493912;
BA_ "FrameRouting" BO_ 2609976536 "";
BA_ "NetworkInitialization" BO_ 2609976536 0;
BA_ "GenMsgDelayTime" BO_ 2609976536 0;
BA_ "GenMsgSendType" BO_ 2609976536 1;
BA_ "TpTxIndex" BO_ 2609976536 462492888;
BA_ "FrameRouting" BO_ 2609927384 "";
BA_ "NetworkInitialization" BO_ 2609927384 0;
BA_ "GenMsgDelayTime" BO_ 2609927384 0;
BA_ "GenMsgSendType" BO_ 2609927384 1;
BA_ "TpTxIndex" BO_ 2609927384 462443736;
BA_ "TpTxIndex" BO_ 2611175523 463572184;
BA_ "FrameRouting" BO_ 2611175523 "";
BA_ "NetworkInitialization" BO_ 2611175523 0;
BA_ "GenMsgDelayTime" BO_ 2611175523 0;
BA_ "GenMsgSendType" BO_ 2611175523 1;
BA_ "TpTxIndex" BO_ 2612224099 464620760;
BA_ "OvtpPushApplication" BO_ 2612224099 1;
BA_ "FrameRouting" BO_ 2612224099 "";
BA_ "NetworkInitialization" BO_ 2612224099 0;
BA_ "GenMsgDelayTime" BO_ 2612224099 0;
BA_ "GenMsgSendType" BO_ 2612224099 1;
BA_ "TpTxIndex" BO_ 2611175522 463571160;
BA_ "FrameRouting" BO_ 2611175522 "";
BA_ "NetworkInitialization" BO_ 2611175522 0;
BA_ "GenMsgDelayTime" BO_ 2611175522 0;
BA_ "GenMsgSendType" BO_ 2611175522 1;
BA_ "TpTxIndex" BO_ 2612224098 464619736;
BA_ "OvtpPushApplication" BO_ 2612224098 1;
BA_ "FrameRouting" BO_ 2612224098 "";
BA_ "NetworkInitialization" BO_ 2612224098 0;
BA_ "GenMsgDelayTime" BO_ 2612224098 0;
BA_ "GenMsgSendType" BO_ 2612224098 1;
BA_ "TpTxIndex" BO_ 2611175494 463542488;
BA_ "FrameRouting" BO_ 2611175494 "";
BA_ "NetworkInitialization" BO_ 2611175494 0;
BA_ "GenMsgDelayTime" BO_ 2611175494 0;
BA_ "GenMsgSendType" BO_ 2611175494 1;
BA_ "TpTxIndex" BO_ 2612224070 464591064;
BA_ "OvtpPushApplication" BO_ 2612224070 1;
BA_ "FrameRouting" BO_ 2612224070 "";
BA_ "NetworkInitialization" BO_ 2612224070 0;
BA_ "GenMsgDelayTime" BO_ 2612224070 0;
BA_ "GenMsgSendType" BO_ 2612224070 1;
BA_ "TpTxIndex" BO_ 2611175493 463541464;
BA_ "FrameRouting" BO_ 2611175493 "";
BA_ "NetworkInitialization" BO_ 2611175493 0;
BA_ "GenMsgDelayTime" BO_ 2611175493 0;
BA_ "GenMsgSendType" BO_ 2611175493 1;
BA_ "TpTxIndex" BO_ 2612224069 464590040;
BA_ "OvtpPushApplication" BO_ 2612224069 1;
BA_ "FrameRouting" BO_ 2612224069 "";
BA_ "NetworkInitialization" BO_ 2612224069 0;
BA_ "GenMsgDelayTime" BO_ 2612224069 0;
BA_ "GenMsgSendType" BO_ 2612224069 1;
BA_ "TpTxIndex" BO_ 2611175445 463492312;
BA_ "FrameRouting" BO_ 2611175445 "";
BA_ "NetworkInitialization" BO_ 2611175445 0;
BA_ "GenMsgDelayTime" BO_ 2611175445 0;
BA_ "GenMsgSendType" BO_ 2611175445 1;
BA_ "TpTxIndex" BO_ 2612224021 464540888;
BA_ "OvtpPushApplication" BO_ 2612224021 1;
BA_ "FrameRouting" BO_ 2612224021 "";
BA_ "NetworkInitialization" BO_ 2612224021 0;
BA_ "GenMsgDelayTime" BO_ 2612224021 0;
BA_ "GenMsgSendType" BO_ 2612224021 1;
BA_ "TpTxIndex" BO_ 2610126947 462523608;
BA_ "FrameRouting" BO_ 2610126947 "";
BA_ "NetworkInitialization" BO_ 2610126947 0;
BA_ "GenMsgDelayTime" BO_ 2610126947 0;
BA_ "GenMsgSendType" BO_ 2610126947 1;
BA_ "TpTxIndex" BO_ 2610126946 462522584;
BA_ "FrameRouting" BO_ 2610126946 "";
BA_ "NetworkInitialization" BO_ 2610126946 0;
BA_ "GenMsgDelayTime" BO_ 2610126946 0;
BA_ "GenMsgSendType" BO_ 2610126946 1;
BA_ "TpTxIndex" BO_ 2610126918 462493912;
BA_ "FrameRouting" BO_ 2610126918 "";
BA_ "NetworkInitialization" BO_ 2610126918 0;
BA_ "GenMsgDelayTime" BO_ 2610126918 0;
BA_ "GenMsgSendType" BO_ 2610126918 1;
BA_ "TpTxIndex" BO_ 2610126917 462492888;
BA_ "FrameRouting" BO_ 2610126917 "";
BA_ "NetworkInitialization" BO_ 2610126917 0;
BA_ "GenMsgDelayTime" BO_ 2610126917 0;
BA_ "GenMsgSendType" BO_ 2610126917 1;
BA_ "FrameRouting" BO_ 2610126869 "";
BA_ "NetworkInitialization" BO_ 2610126869 0;
BA_ "GenMsgDelayTime" BO_ 2610126869 0;
BA_ "GenMsgSendType" BO_ 2610126869 1;
BA_ "TpTxIndex" BO_ 2610126869 462443736;
BA_ "FrameRouting" BO_ 984 "";
BA_ "GenMsgCycleTime" BO_ 984 1000;
BA_ "GenMsgSendType" BO_ 984 5;
BA_ "VFrameFormat" BO_ 984 14;
BA_ "FrameRouting" BO_ 985 "";
BA_ "GenMsgSendType" BO_ 985 5;
BA_ "GenMsgCycleTime" BO_ 985 1000;
BA_ "VFrameFormat" BO_ 985 14;
BA_ "FrameRouting" BO_ 992 "";
BA_ "FrameGatewayNetwork" BO_ 992 "HS3_CAN";
BA_ "FrameGatewayId" BO_ 992 992;
BA_ "VFrameFormat" BO_ 992 14;
BA_ "OvtpPushApplication" BO_ 2612019416 1;
BA_ "FrameRouting" BO_ 2612019416 "";
BA_ "TpTxIndex" BO_ 2612019416 464535768;
BA_ "NetworkInitialization" BO_ 2612019416 0;
BA_ "GenMsgDelayTime" BO_ 2612019416 0;
BA_ "GenMsgSendType" BO_ 2612019416 1;
BA_ "FrameRouting" BO_ 943 "";
BA_ "GenMsgSendType" BO_ 943 0;
BA_ "GenMsgCycleTime" BO_ 943 20;
BA_ "GenMsgDelayTime" BO_ 943 10;
BA_ "VFrameFormat" BO_ 943 14;
BA_ "FrameRouting" BO_ 515 "";
BA_ "GenMsgSendType" BO_ 515 5;
BA_ "GenMsgCycleTime" BO_ 515 100;
BA_ "VFrameFormat" BO_ 515 14;
BA_ "FrameRouting" BO_ 1111 "";
BA_ "FrameGatewayId" BO_ 1111 1111;
BA_ "FrameGatewayNetwork" BO_ 1111 "HS2_CAN";
BA_ "VFrameFormat" BO_ 1111 14;
BA_ "FrameRouting" BO_ 1106 "";
BA_ "FrameGatewayId" BO_ 1106 1106;
BA_ "FrameGatewayNetwork" BO_ 1106 "HS2_CAN";
BA_ "VFrameFormat" BO_ 1106 14;
BA_ "FrameRouting" BO_ 1985 "";
BA_ "NetworkInitialization" BO_ 1985 0;
BA_ "GenMsgDelayTime" BO_ 1985 0;
BA_ "GenMsgSendType" BO_ 1985 1;
BA_ "DiagRequest" BO_ 1985 1;
BA_ "GenMsgILSupport" BO_ 1985 0;
BA_ "VFrameFormat" BO_ 1985 14;
BA_ "FrameRouting" BO_ 1993 "";
BA_ "NetworkInitialization" BO_ 1993 0;
BA_ "GenMsgDelayTime" BO_ 1993 0;
BA_ "GenMsgSendType" BO_ 1993 1;
BA_ "DiagResponse" BO_ 1993 1;
BA_ "GenMsgILSupport" BO_ 1993 0;
BA_ "VFrameFormat" BO_ 1993 14;
BA_ "FrameRouting" BO_ 1104 "";
BA_ "GenMsgCycleTime" BO_ 1104 200;
BA_ "GenMsgSendType" BO_ 1104 0;
BA_ "VFrameFormat" BO_ 1104 14;
BA_ "FrameRouting" BO_ 1503 "";
BA_ "NetworkInitialization" BO_ 1503 0;
BA_ "GenMsgCycleTime" BO_ 1503 1000;
BA_ "GenMsgSendType" BO_ 1503 0;
BA_ "NmAsrMessage" BO_ 1503 1;
BA_ "GenMsgILSupport" BO_ 1503 0;
BA_ "VFrameFormat" BO_ 1503 14;
BA_ "TpTxIndex" BO_ 2610995416 463511768;
BA_ "FrameRouting" BO_ 2610995416 "";
BA_ "NetworkInitialization" BO_ 2610995416 0;
BA_ "GenMsgDelayTime" BO_ 2610995416 0;
BA_ "GenMsgSendType" BO_ 2610995416 1;
BA_ "TpTxIndex" BO_ 2612043992 464560344;
BA_ "OvtpPushApplication" BO_ 2612043992 1;
BA_ "FrameRouting" BO_ 2612043992 "";
BA_ "NetworkInitialization" BO_ 2612043992 0;
BA_ "GenMsgDelayTime" BO_ 2612043992 0;
BA_ "GenMsgSendType" BO_ 2612043992 1;
BA_ "FrameRouting" BO_ 2609946840 "";
BA_ "NetworkInitialization" BO_ 2609946840 0;
BA_ "GenMsgDelayTime" BO_ 2609946840 0;
BA_ "GenMsgSendType" BO_ 2609946840 1;
BA_ "TpTxIndex" BO_ 2609946840 462463192;
BA_ "TpTxIndex" BO_ 2611175464 463511768;
BA_ "FrameRouting" BO_ 2611175464 "";
BA_ "NetworkInitialization" BO_ 2611175464 0;
BA_ "GenMsgDelayTime" BO_ 2611175464 0;
BA_ "GenMsgSendType" BO_ 2611175464 1;
BA_ "TpTxIndex" BO_ 2612224040 464560344;
BA_ "OvtpPushApplication" BO_ 2612224040 1;
BA_ "FrameRouting" BO_ 2612224040 "";
BA_ "NetworkInitialization" BO_ 2612224040 0;
BA_ "GenMsgDelayTime" BO_ 2612224040 0;
BA_ "GenMsgSendType" BO_ 2612224040 1;
BA_ "TpTxIndex" BO_ 2610126888 462463192;
BA_ "FrameRouting" BO_ 2610126888 "";
BA_ "NetworkInitialization" BO_ 2610126888 0;
BA_ "GenMsgDelayTime" BO_ 2610126888 0;
BA_ "GenMsgSendType" BO_ 2610126888 1;
BA_ "TpTxIndex" BO_ 2610988248 463504600;
BA_ "FrameRouting" BO_ 2610988248 "";
BA_ "NetworkInitialization" BO_ 2610988248 0;
BA_ "GenMsgDelayTime" BO_ 2610988248 0;
BA_ "GenMsgSendType" BO_ 2610988248 1;
BA_ "FrameRouting" BO_ 2609939672 "";
BA_ "NetworkInitialization" BO_ 2609939672 0;
BA_ "GenMsgDelayTime" BO_ 2609939672 0;
BA_ "GenMsgSendType" BO_ 2609939672 1;
BA_ "TpTxIndex" BO_ 2609939672 462456024;
BA_ "FrameRouting" BO_ 1114 "";
BA_ "FrameGatewayNetwork" BO_ 1114 "HS3_CAN";
BA_ "FrameGatewayId" BO_ 1114 1114;
BA_ "VFrameFormat" BO_ 1114 14;
BA_ "FrameRouting" BO_ 1116 "";
BA_ "FrameGatewayNetwork" BO_ 1116 "HS3_CAN";
BA_ "FrameGatewayId" BO_ 1116 1116;
BA_ "VFrameFormat" BO_ 1116 14;
BA_ "TpTxIndex" BO_ 2611175457 463504600;
BA_ "FrameRouting" BO_ 2611175457 "";
BA_ "NetworkInitialization" BO_ 2611175457 0;
BA_ "GenMsgDelayTime" BO_ 2611175457 0;
BA_ "GenMsgSendType" BO_ 2611175457 1;
BA_ "TpTxIndex" BO_ 2612224033 464553176;
BA_ "OvtpPushApplication" BO_ 2612224033 1;
BA_ "FrameRouting" BO_ 2612224033 "";
BA_ "NetworkInitialization" BO_ 2612224033 0;
BA_ "GenMsgDelayTime" BO_ 2612224033 0;
BA_ "GenMsgSendType" BO_ 2612224033 1;
BA_ "TpTxIndex" BO_ 2610126881 462456024;
BA_ "FrameRouting" BO_ 2610126881 "";
BA_ "NetworkInitialization" BO_ 2610126881 0;
BA_ "GenMsgDelayTime" BO_ 2610126881 0;
BA_ "GenMsgSendType" BO_ 2610126881 1;
BA_ "FrameRouting" BO_ 1085 "";
BA_ "GenMsgSendType" BO_ 1085 0;
BA_ "GenMsgCycleTime" BO_ 1085 50;
BA_ "VFrameFormat" BO_ 1085 14;
BA_ "FrameRouting" BO_ 791 "";
BA_ "FrameGatewayId" BO_ 791 791;
BA_ "FrameGatewayNetwork" BO_ 791 "HS3_CAN";
BA_ "VFrameFormat" BO_ 791 14;
BA_ "TpTxIndex" BO_ 2610970840 463487192;
BA_ "FrameRouting" BO_ 2610970840 "";
BA_ "NetworkInitialization" BO_ 2610970840 0;
BA_ "GenMsgDelayTime" BO_ 2610970840 0;
BA_ "GenMsgSendType" BO_ 2610970840 1;
BA_ "TpTxIndex" BO_ 2609922264 462438616;
BA_ "FrameRouting" BO_ 2609922264 "";
BA_ "NetworkInitialization" BO_ 2609922264 0;
BA_ "GenMsgDelayTime" BO_ 2609922264 0;
BA_ "GenMsgSendType" BO_ 2609922264 1;
BA_ "FrameRouting" BO_ 868 "";
BA_ "FrameGatewayNetwork" BO_ 868 "HS1_CAN";
BA_ "FrameGatewayId" BO_ 868 868;
BA_ "VFrameFormat" BO_ 868 14;
BA_ "FrameRouting" BO_ 867 "";
BA_ "FrameGatewayNetwork" BO_ 867 "HS1_CAN";
BA_ "FrameGatewayId" BO_ 867 867;
BA_ "VFrameFormat" BO_ 867 14;
BA_ "FrameRouting" BO_ 866 "";
BA_ "FrameGatewayNetwork" BO_ 866 "HS1_CAN";
BA_ "FrameGatewayId" BO_ 866 866;
BA_ "VFrameFormat" BO_ 866 14;
BA_ "FrameRouting" BO_ 865 "";
BA_ "FrameGatewayNetwork" BO_ 865 "HS1_CAN";
BA_ "FrameGatewayId" BO_ 865 865;
BA_ "VFrameFormat" BO_ 865 14;
BA_ "TpTxIndex" BO_ 2611175440 463487192;
BA_ "FrameRouting" BO_ 2611175440 "";
BA_ "NetworkInitialization" BO_ 2611175440 0;
BA_ "GenMsgDelayTime" BO_ 2611175440 0;
BA_ "GenMsgSendType" BO_ 2611175440 1;
BA_ "TpTxIndex" BO_ 2610126864 462438616;
BA_ "FrameRouting" BO_ 2610126864 "";
BA_ "NetworkInitialization" BO_ 2610126864 0;
BA_ "GenMsgDelayTime" BO_ 2610126864 0;
BA_ "GenMsgSendType" BO_ 2610126864 1;
BA_ "TpTxIndex" BO_ 2611175441 463488216;
BA_ "FrameRouting" BO_ 2611175441 "";
BA_ "NetworkInitialization" BO_ 2611175441 0;
BA_ "GenMsgDelayTime" BO_ 2611175441 0;
BA_ "GenMsgSendType" BO_ 2611175441 1;
BA_ "TpTxIndex" BO_ 2612224017 463488216;
BA_ "OvtpPushApplication" BO_ 2612224017 1;
BA_ "FrameRouting" BO_ 2612224017 "";
BA_ "NetworkInitialization" BO_ 2612224017 0;
BA_ "GenMsgDelayTime" BO_ 2612224017 0;
BA_ "GenMsgSendType" BO_ 2612224017 1;
BA_ "FrameRouting" BO_ 2610126865 "";
BA_ "NetworkInitialization" BO_ 2610126865 0;
BA_ "GenMsgDelayTime" BO_ 2610126865 0;
BA_ "GenMsgSendType" BO_ 2610126865 1;
BA_ "TpTxIndex" BO_ 2610126865 462439640;
BA_ "FrameRouting" BO_ 1679 "";
BA_ "GenMsgSendType" BO_ 1679 1;
BA_ "TpApplType" BO_ 1679 "DiagUUDTResponse";
BA_ "GenMsgILSupport" BO_ 1679 0;
BA_ "VFrameFormat" BO_ 1679 14;
BA_ "FrameRouting" BO_ 1678 "";
BA_ "GenMsgSendType" BO_ 1678 1;
BA_ "TpApplType" BO_ 1678 "DiagUUDTResponse";
BA_ "GenMsgILSupport" BO_ 1678 0;
BA_ "VFrameFormat" BO_ 1678 14;
BA_ "FrameRouting" BO_ 1677 "";
BA_ "GenMsgSendType" BO_ 1677 1;
BA_ "TpApplType" BO_ 1677 "DiagUUDTResponse";
BA_ "GenMsgILSupport" BO_ 1677 0;
BA_ "VFrameFormat" BO_ 1677 14;
BA_ "FrameRouting" BO_ 1676 "";
BA_ "GenMsgSendType" BO_ 1676 1;
BA_ "TpApplType" BO_ 1676 "DiagUUDTResponse";
BA_ "GenMsgILSupport" BO_ 1676 0;
BA_ "VFrameFormat" BO_ 1676 14;
BA_ "FrameRouting" BO_ 1445 "";
BA_ "GenMsgILSupport" BO_ 1445 0;
BA_ "NmAsrMessage" BO_ 1445 1;
BA_ "GenMsgSendType" BO_ 1445 0;
BA_ "GenMsgCycleTime" BO_ 1445 1000;
BA_ "NetworkInitialization" BO_ 1445 0;
BA_ "VFrameFormat" BO_ 1445 14;
BA_ "FrameRouting" BO_ 1144 "";
BA_ "GenMsgSendType" BO_ 1144 5;
BA_ "GenMsgCycleTime" BO_ 1144 1000;
BA_ "VFrameFormat" BO_ 1144 14;
BA_ "FrameRouting" BO_ 1141 "";
BA_ "GenMsgSendType" BO_ 1141 0;
BA_ "GenMsgCycleTime" BO_ 1141 500;
BA_ "VFrameFormat" BO_ 1141 14;
BA_ "FrameRouting" BO_ 1140 "";
BA_ "GenMsgSendType" BO_ 1140 0;
BA_ "GenMsgCycleTime" BO_ 1140 1000;
BA_ "VFrameFormat" BO_ 1140 14;
BA_ "FrameRouting" BO_ 1139 "";
BA_ "GenMsgCycleTime" BO_ 1139 1500;
BA_ "GenMsgSendType" BO_ 1139 0;
BA_ "VFrameFormat" BO_ 1139 14;
BA_ "FrameRouting" BO_ 1138 "";
BA_ "GenMsgCycleTime" BO_ 1138 1500;
BA_ "GenMsgSendType" BO_ 1138 0;
BA_ "VFrameFormat" BO_ 1138 14;
BA_ "FrameRouting" BO_ 1089 "";
BA_ "GenMsgCycleTime" BO_ 1089 1000;
BA_ "GenMsgSendType" BO_ 1089 0;
BA_ "VFrameFormat" BO_ 1089 14;
BA_ "FrameRouting" BO_ 1088 "";
BA_ "GenMsgCycleTime" BO_ 1088 1000;
BA_ "GenMsgSendType" BO_ 1088 0;
BA_ "VFrameFormat" BO_ 1088 14;
BA_ "FrameRouting" BO_ 1040 "";
BA_ "GenMsgCycleTime" BO_ 1040 100;
BA_ "GenMsgSendType" BO_ 1040 0;
BA_ "VFrameFormat" BO_ 1040 14;
BA_ "FrameRouting" BO_ 1016 "";
BA_ "GenMsgCycleTime" BO_ 1016 1000;
BA_ "GenMsgSendType" BO_ 1016 5;
BA_ "VFrameFormat" BO_ 1016 14;
BA_ "FrameRouting" BO_ 1013 "";
BA_ "GenMsgCycleTime" BO_ 1013 1000;
BA_ "GenMsgSendType" BO_ 1013 5;
BA_ "VFrameFormat" BO_ 1013 14;
BA_ "FrameRouting" BO_ 1012 "";
BA_ "GenMsgCycleTime" BO_ 1012 1000;
BA_ "GenMsgSendType" BO_ 1012 5;
BA_ "VFrameFormat" BO_ 1012 14;
BA_ "FrameRouting" BO_ 1011 "";
BA_ "GenMsgCycleTime" BO_ 1011 1000;
BA_ "GenMsgSendType" BO_ 1011 5;
BA_ "VFrameFormat" BO_ 1011 14;
BA_ "FrameRouting" BO_ 871 "";
BA_ "GenMsgCycleTime" BO_ 871 100;
BA_ "GenMsgSendType" BO_ 871 0;
BA_ "VFrameFormat" BO_ 871 14;
BA_ "FrameRouting" BO_ 786 "";
BA_ "GenMsgCycleTime" BO_ 786 100;
BA_ "GenMsgSendType" BO_ 786 0;
BA_ "VFrameFormat" BO_ 786 14;
BA_ "FrameRouting" BO_ 72 "";
BA_ "GenMsgDelayTime" BO_ 72 10;
BA_ "GenMsgCycleTime" BO_ 72 20;
BA_ "GenMsgSendType" BO_ 72 0;
BA_ "VFrameFormat" BO_ 72 14;
BA_ "FrameRouting" BO_ 912 "";
BA_ "FrameGatewayNetwork" BO_ 912 "HS1_CAN";
BA_ "FrameGatewayId" BO_ 912 912;
BA_ "VFrameFormat" BO_ 912 14;
BA_ "FrameRouting" BO_ 874 "";
BA_ "FrameGatewayNetwork" BO_ 874 "HS1_CAN";
BA_ "FrameGatewayId" BO_ 874 874;
BA_ "VFrameFormat" BO_ 874 14;
BA_ "FrameRouting" BO_ 651 "";
BA_ "FrameGatewayNetwork" BO_ 651 "HS4_CAN";
BA_ "FrameGatewayId" BO_ 651 651;
BA_ "VFrameFormat" BO_ 651 14;
BA_ "FrameRouting" BO_ 529 "";
BA_ "FrameGatewayNetwork" BO_ 529 "HS3_CAN";
BA_ "FrameGatewayId" BO_ 529 529;
BA_ "VFrameFormat" BO_ 529 14;
BA_ "FrameRouting" BO_ 66 "";
BA_ "FrameGatewayNetwork" BO_ 66 "HS1_CAN";
BA_ "FrameGatewayId" BO_ 66 66;
BA_ "VFrameFormat" BO_ 66 14;
BA_ "TpTxIndex" BO_ 2610971864 463488216;
BA_ "FrameRouting" BO_ 2610971864 "";
BA_ "NetworkInitialization" BO_ 2610971864 0;
BA_ "GenMsgDelayTime" BO_ 2610971864 0;
BA_ "GenMsgSendType" BO_ 2610971864 1;
BA_ "TpTxIndex" BO_ 2612002008 464518360;
BA_ "FrameRouting" BO_ 2612002008 "";
BA_ "NetworkInitialization" BO_ 2612002008 0;
BA_ "GenMsgDelayTime" BO_ 2612002008 0;
BA_ "GenMsgSendType" BO_ 2612002008 1;
BA_ "FrameRouting" BO_ 2609923288 "";
BA_ "NetworkInitialization" BO_ 2609923288 0;
BA_ "GenMsgDelayTime" BO_ 2609923288 0;
BA_ "GenMsgSendType" BO_ 2609923288 1;
BA_ "TpTxIndex" BO_ 2609923288 462439640;
BA_ "TpTxIndex" BO_ 2610953432 463469784;
BA_ "FrameRouting" BO_ 2610953432 "";
BA_ "NetworkInitialization" BO_ 2610953432 0;
BA_ "GenMsgDelayTime" BO_ 2610953432 0;
BA_ "GenMsgSendType" BO_ 2610953432 1;
BA_ "FrameRouting" BO_ 2022 "";
BA_ "GenMsgILSupport" BO_ 2022 0;
BA_ "DiagRequest" BO_ 2022 1;
BA_ "GenMsgSendType" BO_ 2022 1;
BA_ "GenMsgDelayTime" BO_ 2022 0;
BA_ "VFrameFormat" BO_ 2022 14;
BA_ "FrameRouting" BO_ 1124 "";
BA_ "FrameGatewayId" BO_ 1124 1124;
BA_ "FrameGatewayNetwork" BO_ 1124 "HS3_CAN";
BA_ "VFrameFormat" BO_ 1124 14;
BA_ "FrameRouting" BO_ 1119 "";
BA_ "FrameGatewayId" BO_ 1119 1119;
BA_ "FrameGatewayNetwork" BO_ 1119 "HS1_CAN";
BA_ "VFrameFormat" BO_ 1119 14;
BA_ "FrameRouting" BO_ 132 "";
BA_ "FrameGatewayNetwork" BO_ 132 "HS1_CAN";
BA_ "FrameGatewayId" BO_ 132 132;
BA_ "VFrameFormat" BO_ 132 14;
BA_ "FrameRouting" BO_ 1990 "";
BA_ "NetworkInitialization" BO_ 1990 0;
BA_ "GenMsgDelayTime" BO_ 1990 0;
BA_ "GenMsgSendType" BO_ 1990 1;
BA_ "DiagRequest" BO_ 1990 1;
BA_ "GenMsgILSupport" BO_ 1990 0;
BA_ "VFrameFormat" BO_ 1990 14;
BA_ "FrameRouting" BO_ 1892 "";
BA_ "NetworkInitialization" BO_ 1892 0;
BA_ "GenMsgDelayTime" BO_ 1892 0;
BA_ "GenMsgSendType" BO_ 1892 1;
BA_ "DiagRequest" BO_ 1892 1;
BA_ "GenMsgILSupport" BO_ 1892 0;
BA_ "VFrameFormat" BO_ 1892 14;
BA_ "FrameRouting" BO_ 1798 "";
BA_ "NetworkInitialization" BO_ 1798 0;
BA_ "GenMsgDelayTime" BO_ 1798 0;
BA_ "GenMsgSendType" BO_ 1798 1;
BA_ "DiagRequest" BO_ 1798 1;
BA_ "GenMsgILSupport" BO_ 1798 0;
BA_ "VFrameFormat" BO_ 1798 14;
BA_ "FrameRouting" BO_ 1123 "";
BA_ "FrameGatewayNetwork" BO_ 1123 "HS3_CAN";
BA_ "FrameGatewayId" BO_ 1123 1123;
BA_ "VFrameFormat" BO_ 1123 14;
BA_ "FrameRouting" BO_ 1122 "";
BA_ "FrameGatewayNetwork" BO_ 1122 "HS3_CAN";
BA_ "FrameGatewayId" BO_ 1122 1122;
BA_ "VFrameFormat" BO_ 1122 14;
BA_ "FrameRouting" BO_ 1003 "";
BA_ "FrameGatewayNetwork" BO_ 1003 "HS1_CAN";
BA_ "FrameGatewayId" BO_ 1003 1003;
BA_ "VFrameFormat" BO_ 1003 14;
BA_ "FrameRouting" BO_ 994 "";
BA_ "FrameGatewayNetwork" BO_ 994 "HS3_CAN";
BA_ "FrameGatewayId" BO_ 994 994;
BA_ "VFrameFormat" BO_ 994 14;
BA_ "FrameRouting" BO_ 778 "";
BA_ "FrameGatewayId" BO_ 778 778;
BA_ "FrameGatewayNetwork" BO_ 778 "HS3_CAN";
BA_ "VFrameFormat" BO_ 778 14;
BA_ "FrameRouting" BO_ 549 "";
BA_ "FrameGatewayId" BO_ 549 549;
BA_ "FrameGatewayNetwork" BO_ 549 "HS3_CAN";
BA_ "VFrameFormat" BO_ 549 14;
BA_ "FrameRouting" BO_ 551 "";
BA_ "FrameGatewayId" BO_ 551 551;
BA_ "FrameGatewayNetwork" BO_ 551 "HS3_CAN";
BA_ "VFrameFormat" BO_ 551 14;
BA_ "FrameRouting" BO_ 1010 "";
BA_ "GenMsgCycleTime" BO_ 1010 50;
BA_ "GenMsgSendType" BO_ 1010 0;
BA_ "VFrameFormat" BO_ 1010 14;
BA_ "FrameRouting" BO_ 1070 "";
BA_ "FrameGatewayNetwork" BO_ 1070 "HS1_CAN";
BA_ "FrameGatewayId" BO_ 1070 1070;
BA_ "VFrameFormat" BO_ 1070 14;
BA_ "FrameRouting" BO_ 1186 "";
BA_ "GenMsgSendType" BO_ 1186 0;
BA_ "GenMsgCycleTime" BO_ 1186 100;
BA_ "VFrameFormat" BO_ 1186 14;
BA_ "FrameRouting" BO_ 611 "";
BA_ "GenMsgSendType" BO_ 611 0;
BA_ "GenMsgCycleTime" BO_ 611 100;
BA_ "VFrameFormat" BO_ 611 14;
BA_ "FrameRouting" BO_ 1461 "";
BA_ "GenMsgILSupport" BO_ 1461 0;
BA_ "NmAsrMessage" BO_ 1461 1;
BA_ "GenMsgSendType" BO_ 1461 0;
BA_ "GenMsgCycleTime" BO_ 1461 1000;
BA_ "NetworkInitialization" BO_ 1461 0;
BA_ "VFrameFormat" BO_ 1461 14;
BA_ "FrameRouting" BO_ 1047 "";
BA_ "GenMsgSendType" BO_ 1047 5;
BA_ "GenMsgCycleTime" BO_ 1047 1000;
BA_ "VFrameFormat" BO_ 1047 14;
BA_ "FrameRouting" BO_ 972 "";
BA_ "GenMsgSendType" BO_ 972 0;
BA_ "GenMsgCycleTime" BO_ 972 30;
BA_ "GenMsgDelayTime" BO_ 972 10;
BA_ "VFrameFormat" BO_ 972 14;
BA_ "FrameRouting" BO_ 130 "";
BA_ "GenMsgSendType" BO_ 130 0;
BA_ "GenMsgCycleTime" BO_ 130 20;
BA_ "GenMsgDelayTime" BO_ 130 10;
BA_ "VFrameFormat" BO_ 130 14;
BA_ "FrameRouting" BO_ 126 "";
BA_ "GenMsgSendType" BO_ 126 0;
BA_ "GenMsgCycleTime" BO_ 126 10;
BA_ "GenMsgDelayTime" BO_ 126 0;
BA_ "VFrameFormat" BO_ 126 14;
BA_ "FrameRouting" BO_ 133 "";
BA_ "GenMsgSendType" BO_ 133 0;
BA_ "GenMsgCycleTime" BO_ 133 10;
BA_ "GenMsgDelayTime" BO_ 133 0;
BA_ "VFrameFormat" BO_ 133 14;
BA_ "FrameRouting" BO_ 1430 "";
BA_ "GenMsgILSupport" BO_ 1430 0;
BA_ "NmAsrMessage" BO_ 1430 1;
BA_ "GenMsgSendType" BO_ 1430 0;
BA_ "GenMsgCycleTime" BO_ 1430 1000;
BA_ "NetworkInitialization" BO_ 1430 0;
BA_ "VFrameFormat" BO_ 1430 14;
BA_ "ECGUsedTxSignal" SG_ 2611055832 PARSEDPhysGWM_ECGtoSODR 1;
BA_ "GenSigSendType" SG_ 2611055832 PARSEDPhysGWM_ECGtoSODR 3;
BA_ "ECGUsedTxSignal" SG_ 2611054808 PARSEDPhysGWM_ECGtoSODL 1;
BA_ "GenSigSendType" SG_ 2611054808 PARSEDPhysGWM_ECGtoSODL 3;
BA_ "ECGUsedTxSignal" SG_ 2611026136 PARSEDPhysGWM_ECGtoSODCMD 1;
BA_ "GenSigSendType" SG_ 2611026136 PARSEDPhysGWM_ECGtoSODCMD 3;
BA_ "ECGUsedTxSignal" SG_ 2611025112 PARSEDPhysGWM_ECGtoSODCMC 1;
BA_ "GenSigSendType" SG_ 2611025112 PARSEDPhysGWM_ECGtoSODCMC 3;
BA_ "ECGUsedTxSignal" SG_ 2610975960 PARSEDPhysGWM_ECGtoCCM 1;
BA_ "GenSigSendType" SG_ 2610975960 PARSEDPhysGWM_ECGtoCCM 3;
BA_ "ECGUsedTxSignal" SG_ 2610007256 OTAPhysGWM_ECGtoSODR 1;
BA_ "GenSigSendType" SG_ 2610007256 OTAPhysGWM_ECGtoSODR 3;
BA_ "ECGUsedTxSignal" SG_ 2610006232 OTAPhysGWM_ECGtoSODL 1;
BA_ "GenSigSendType" SG_ 2610006232 OTAPhysGWM_ECGtoSODL 3;
BA_ "ECGUsedTxSignal" SG_ 2609977560 OTAPhysGWM_ECGtoSODCMD 1;
BA_ "GenSigSendType" SG_ 2609977560 OTAPhysGWM_ECGtoSODCMD 3;
BA_ "ECGUsedTxSignal" SG_ 2609976536 OTAPhysGWM_ECGtoSODCMC 1;
BA_ "GenSigSendType" SG_ 2609976536 OTAPhysGWM_ECGtoSODCMC 3;
BA_ "ECGUsedTxSignal" SG_ 2609927384 OTAPhysGWM_ECGtoCCM 1;
BA_ "GenSigSendType" SG_ 2609927384 OTAPhysGWM_ECGtoCCM 3;
BA_ "ECGUsedRxSignal" SG_ 2611175523 PARSEDPhysSODRtoGWM_ECG 1;
BA_ "GenSigSendType" SG_ 2611175523 PARSEDPhysSODRtoGWM_ECG 3;
BA_ "ECGUsedRxSignal" SG_ 2612224099 PARSEDPhysSODR2toGWM_ECG 1;
BA_ "GenSigSendType" SG_ 2612224099 PARSEDPhysSODR2toGWM_ECG 3;
BA_ "ECGUsedRxSignal" SG_ 2611175522 PARSEDPhysSODLtoGWM_ECG 1;
BA_ "GenSigSendType" SG_ 2611175522 PARSEDPhysSODLtoGWM_ECG 3;
BA_ "ECGUsedRxSignal" SG_ 2612224098 PARSEDPhysSODL2toGWM_ECG 1;
BA_ "GenSigSendType" SG_ 2612224098 PARSEDPhysSODL2toGWM_ECG 3;
BA_ "ECGUsedRxSignal" SG_ 2611175494 PARSEDPhysSODCMDtoGWM_ECG 1;
BA_ "GenSigSendType" SG_ 2611175494 PARSEDPhysSODCMDtoGWM_ECG 3;
BA_ "ECGUsedRxSignal" SG_ 2612224070 PARSEDPhysSODCMD2toGWM_ECG 1;
BA_ "GenSigSendType" SG_ 2612224070 PARSEDPhysSODCMD2toGWM_ECG 3;
BA_ "ECGUsedRxSignal" SG_ 2611175493 PARSEDPhysSODCMCtoGWM_ECG 1;
BA_ "GenSigSendType" SG_ 2611175493 PARSEDPhysSODCMCtoGWM_ECG 3;
BA_ "ECGUsedRxSignal" SG_ 2612224069 PARSEDPhysSODCMC2toGWM_ECG 1;
BA_ "GenSigSendType" SG_ 2612224069 PARSEDPhysSODCMC2toGWM_ECG 3;
BA_ "ECGUsedRxSignal" SG_ 2611175445 PARSEDPhysCCMtoGWM_ECG 1;
BA_ "GenSigSendType" SG_ 2611175445 PARSEDPhysCCMtoGWM_ECG 3;
BA_ "ECGUsedRxSignal" SG_ 2612224021 PARSEDPhysCCM2toGWM_ECG 1;
BA_ "GenSigSendType" SG_ 2612224021 PARSEDPhysCCM2toGWM_ECG 3;
BA_ "ECGUsedRxSignal" SG_ 2610126947 OTAPhysSODRtoGWM_ECG 1;
BA_ "GenSigSendType" SG_ 2610126947 OTAPhysSODRtoGWM_ECG 3;
BA_ "ECGUsedRxSignal" SG_ 2610126946 OTAPhysSODLtoGWM_ECG 1;
BA_ "GenSigSendType" SG_ 2610126946 OTAPhysSODLtoGWM_ECG 3;
BA_ "ECGUsedRxSignal" SG_ 2610126918 OTAPhysSODCMDtoGWM_ECG 1;
BA_ "GenSigSendType" SG_ 2610126918 OTAPhysSODCMDtoGWM_ECG 3;
BA_ "ECGUsedRxSignal" SG_ 2610126917 OTAPhysSODCMCtoGWM_ECG 1;
BA_ "GenSigSendType" SG_ 2610126917 OTAPhysSODCMCtoGWM_ECG 3;
BA_ "ECGUsedRxSignal" SG_ 2610126869 OTAPhysCCMtoGWM_ECG 1;
BA_ "GenSigSendType" SG_ 2610126869 OTAPhysCCMtoGWM_ECG 3;
BA_ "CrossOver_InfoCAN" SG_ 984 FeatConfigIpmaActl 1;
BA_ "CrossOver_InfoCAN" SG_ 984 FeatNoIpmaActl 1;
BA_ "GenSigStartValue" SG_ 984 PersIndexIpma_D_Actl 4;
BA_ "GenSigStartValueInteger" SG_ 984 PersIndexIpma_D_Actl 4;
BA_ "CrossOver_InfoCAN" SG_ 984 PersIndexIpma_D_Actl 1;
BA_ "GenSigSendType" SG_ 984 PersIndexIpma_D_Actl 3;
BA_ "U_P702_MY2021_Rx" SG_ 984 AhbcRampingV_D_Rq 1;
BA_ "GenSigSendType" SG_ 984 AhbcRampingV_D_Rq 3;
BA_ "CrossOver_InfoCAN" SG_ 984 LaActvStats_D_Dsply 1;
BA_ "GenSigSendType" SG_ 984 LaActvStats_D_Dsply 3;
BA_ "CrossOver_InfoCAN" SG_ 984 LaDenyStats_B_Dsply 1;
BA_ "GenSigSendType" SG_ 984 LaDenyStats_B_Dsply 3;
BA_ "CrossOver_InfoCAN" SG_ 984 LaHandsOff_D_Dsply 1;
BA_ "GenSigSendType" SG_ 984 LaHandsOff_D_Dsply 3;
BA_ "CrossOver_InfoCAN" SG_ 984 CamraDefog_B_Req 1;
BA_ "GenSigSendType" SG_ 984 CamraDefog_B_Req 3;
BA_ "CrossOver_InfoCAN" SG_ 984 CamraStats_D_Dsply 1;
BA_ "GenSigSendType" SG_ 984 CamraStats_D_Dsply 3;
BA_ "CrossOver_InfoCAN" SG_ 984 DasAlrtLvl_D_Dsply 1;
BA_ "GenSigSendType" SG_ 984 DasAlrtLvl_D_Dsply 3;
BA_ "CrossOver_InfoCAN" SG_ 984 DasStats_D_Dsply 1;
BA_ "GenSigSendType" SG_ 984 DasStats_D_Dsply 3;
BA_ "CrossOver_InfoCAN" SG_ 984 DasWarn_D_Dsply 1;
BA_ "GenSigSendType" SG_ 984 DasWarn_D_Dsply 3;
BA_ "GenSigSendType" SG_ 984 AhbHiBeam_D_Rq 3;
BA_ "GenSigSendType" SG_ 985 LdwChime_B_Rq 3;
BA_ "GenSigSendType" SG_ 985 TsrRegionTxt_D_Stat 3;
BA_ "GenSigSendType" SG_ 985 SblmPedCrossScnr_B_Stat 3;
BA_ "GenSigSendType" SG_ 985 LongCtrlEnbl_D_Rq 3;
BA_ "GenSigSendType" SG_ 985 SblmRndAbtScnr_B_Stat 3;
BA_ "GenSigSendType" SG_ 985 DasAlrtInfo_D_Dsply 3;
BA_ "U_T6_MCA_MY2020_Rx" SG_ 985 IaccVLim_D_Rq 1;
BA_ "U_P702_MY2021_Rx" SG_ 985 IaccVLim_D_Rq 1;
BA_ "GenSigStartValue" SG_ 985 IaccVLim_D_Rq 254;
BA_ "GenSigStartValueInteger" SG_ 985 IaccVLim_D_Rq 254;
BA_ "GenSigSendType" SG_ 985 IaccVLim_D_Rq 3;
BA_ "U_T6_MCA_MY2020_Rx" SG_ 985 IaccVLimUnit_D_Rq 1;
BA_ "U_P702_MY2021_Rx" SG_ 985 IaccVLimUnit_D_Rq 1;
BA_ "GenSigStartValue" SG_ 985 IaccVLimUnit_D_Rq 3;
BA_ "GenSigStartValueInteger" SG_ 985 IaccVLimUnit_D_Rq 3;
BA_ "GenSigSendType" SG_ 985 IaccVLimUnit_D_Rq 3;
BA_ "U_T6_MCA_MY2020_Rx" SG_ 985 IsaVLim_D_Rq 1;
BA_ "U_P702_MY2021_Rx" SG_ 985 IsaVLim_D_Rq 1;
BA_ "GenSigStartValue" SG_ 985 IsaVLim_D_Rq 254;
BA_ "GenSigStartValueInteger" SG_ 985 IsaVLim_D_Rq 254;
BA_ "GenSigSendType" SG_ 985 IsaVLim_D_Rq 3;
BA_ "GenSigSendType" SG_ 985 SblmStopScnr_B_Stat 3;
BA_ "GenSigSendType" SG_ 985 SblmYieldScnr_B_Stat 3;
BA_ "U_T6_MCA_MY2020_Rx" SG_ 985 IsaVLimUnit_D_Rq 1;
BA_ "U_P702_MY2021_Rx" SG_ 985 IsaVLimUnit_D_Rq 1;
BA_ "GenSigSendType" SG_ 985 IsaVLimUnit_D_Rq 3;
BA_ "GenSigSendType" SG_ 985 AdbDividedRoad_B_Stat 3;
BA_ "GenSigSendType" SG_ 985 LcwaMsgTxt_D_Stat 3;
BA_ "GenSigSendType" SG_ 985 AdbDrvSide_B_Stat 3;
BA_ "U_P702_MY2021_Rx" SG_ 992 MsgCntrDsplyOp_D_Rq 1;
BA_ "CrossOver_InfoCAN" SG_ 992 MsgCntrDsplyOp_D_Rq 1;
BA_ "U_P702_MY2021_Rx" SG_ 992 MsgCntrFeatNoRq 1;
BA_ "CrossOver_InfoCAN" SG_ 992 MsgCntrFeatNoRq 1;
BA_ "U_P702_MY2021_Rx" SG_ 992 MsgCntrFeatConfigRq 1;
BA_ "CrossOver_InfoCAN" SG_ 992 MsgCntrFeatConfigRq 1;
BA_ "U_P702_MY2021_Rx" SG_ 992 MsgCntrPersIndex_D_Rq 1;
BA_ "GenSigStartValue" SG_ 992 MsgCntrPersIndex_D_Rq 4;
BA_ "GenSigStartValueInteger" SG_ 992 MsgCntrPersIndex_D_Rq 4;
BA_ "CrossOver_InfoCAN" SG_ 992 MsgCntrPersIndex_D_Rq 1;
BA_ "GenSigSendType" SG_ 2612019416 PARSEDPhysGWM_ECG2toPCM 3;
BA_ "ECGUsedTxSignal" SG_ 2612019416 PARSEDPhysGWM_ECG2toPCM 1;
BA_ "MetaData" SG_ 943 VehVActlAdas_D_Qf 1;
BA_ "GenSigStartValue" SG_ 943 VehVActlAdas_D_Qf 1;
BA_ "GenSigStartValue" SG_ 943 AdasLcDistToObj_L_Actl 4094;
BA_ "MetaData" SG_ 515 PtIgnSwtch_No_Cs 1;
BA_ "MetaData" SG_ 515 PtIgnSwtch_No_Cnt 1;
BA_ "GenSigSendType" SG_ 515 PtIgnSwtch_D_Stat 3;
BA_ "GenSigStartValue" SG_ 515 PtIgnSwtch_D_Stat 2;
BA_ "GenSigStartValueInteger" SG_ 1111 TrlrYawWActl_D_Qf 1;
BA_ "GenSigStartValue" SG_ 1111 TrlrYawWActl_D_Qf 1;
BA_ "U_P702_MY2021_Rx" SG_ 1111 TrlrYawWActl_D_Qf 1;
BA_ "U_T6_MCA_MY2020_Rx" SG_ 1111 TrlrYawWActl_D_Qf 1;
BA_ "GenSigStartValueInteger" SG_ 1111 TrlrYaw_W_Actl 65534;
BA_ "GenSigStartValue" SG_ 1111 TrlrYaw_W_Actl 65534;
BA_ "U_P702_MY2021_Rx" SG_ 1111 TrlrYaw_W_Actl 1;
BA_ "U_T6_MCA_MY2020_Rx" SG_ 1111 TrlrYaw_W_Actl 1;
BA_ "GenSigStartValueInteger" SG_ 1111 TrlrHitYaw_AnRate_Actl 4094;
BA_ "GenSigStartValue" SG_ 1111 TrlrHitYaw_AnRate_Actl 4093;
BA_ "U_P702_MY2021_Rx" SG_ 1111 TrlrHitYaw_AnRate_Actl 1;
BA_ "U_T6_MCA_MY2020_Rx" SG_ 1111 TrlrHitYaw_AnRate_Actl 1;
BA_ "U_P702_MY2021_Rx" SG_ 1111 TrlrHitchYaw_D_Stat 1;
BA_ "U_T6_MCA_MY2020_Rx" SG_ 1111 TrlrHitchYaw_D_Stat 1;
BA_ "GenSigStartValueInteger" SG_ 1111 TrlrHitchYaw_An_Actl 4094;
BA_ "GenSigStartValue" SG_ 1111 TrlrHitchYaw_An_Actl 4093;
BA_ "U_P702_MY2021_Rx" SG_ 1111 TrlrHitchYaw_An_Actl 1;
BA_ "U_T6_MCA_MY2020_Rx" SG_ 1111 TrlrHitchYaw_An_Actl 1;
BA_ "U_P702_MY2021_Rx" SG_ 1106 TrlrSnsId_No_Actl 1;
BA_ "U_T6_MCA_MY2020_Rx" SG_ 1106 TrlrSnsId_No_Actl 1;
BA_ "GenSigSendType" SG_ 1985 TesterPhysicalReqCMR_DSMC 3;
BA_ "GenSigSendType" SG_ 1993 TesterPhysicalResCMR_DSMC 3;
BA_ "MetaData" SG_ 1104 DrvEngageLevel_No_Cs 1;
BA_ "ContentDependant" SG_ 1104 DrvEngageLevel_No_Cs 1;
BA_ "MetaData" SG_ 1104 DrvEngageLevel_No_Cnt 1;
BA_ "ContentDependant" SG_ 1104 DrvEngageLevel_No_Cnt 1;
BA_ "GenSigStartValue" SG_ 1503 CMR_DSMC_GWOnBoardTester 255;
BA_ "ContentDependant" SG_ 1503 CMR_DSMC_GWOnBoardTester 1;
BA_ "GenSigStartValueInteger" SG_ 1503 CMR_DSMC_GWOnBoardTester 255;
BA_ "GenSigStartValue" SG_ 1503 CMR_DSMC_GWNMProxY 255;
BA_ "ContentDependant" SG_ 1503 CMR_DSMC_GWNMProxY 1;
BA_ "GenSigStartValueInteger" SG_ 1503 CMR_DSMC_GWNMProxY 255;
BA_ "GenSigStartValue" SG_ 1503 CMR_DSMC_AutoSarNMReserved 255;
BA_ "ContentDependant" SG_ 1503 CMR_DSMC_AutoSarNMReserved 1;
BA_ "GenSigStartValueInteger" SG_ 1503 CMR_DSMC_AutoSarNMReserved 255;
BA_ "GenSigStartValue" SG_ 1503 CMR_DSMC_AutoSarNMReserve4 255;
BA_ "ContentDependant" SG_ 1503 CMR_DSMC_AutoSarNMReserve4 1;
BA_ "GenSigStartValueInteger" SG_ 1503 CMR_DSMC_AutoSarNMReserve4 255;
BA_ "GenSigStartValue" SG_ 1503 CMR_DSMC_AutoSarNMReserve3 255;
BA_ "ContentDependant" SG_ 1503 CMR_DSMC_AutoSarNMReserve3 1;
BA_ "GenSigStartValueInteger" SG_ 1503 CMR_DSMC_AutoSarNMReserve3 255;
BA_ "GenSigStartValue" SG_ 1503 CMR_DSMC_AutoSarNMReserve2 255;
BA_ "ContentDependant" SG_ 1503 CMR_DSMC_AutoSarNMReserve2 1;
BA_ "GenSigStartValueInteger" SG_ 1503 CMR_DSMC_AutoSarNMReserve2 255;
BA_ "GenSigStartValue" SG_ 1503 CMR_DSMC_AutoSarNMNodeId 223;
BA_ "ContentDependant" SG_ 1503 CMR_DSMC_AutoSarNMNodeId 1;
BA_ "GenSigStartValueInteger" SG_ 1503 CMR_DSMC_AutoSarNMNodeId 222;
BA_ "ContentDependant" SG_ 1503 CMR_DSMC_AutoSarNMControl 1;
BA_ "ECGUsedTxSignal" SG_ 2610995416 PARSEDPhysGWM_ECGtoABS 1;
BA_ "GenSigSendType" SG_ 2610995416 PARSEDPhysGWM_ECGtoABS 3;
BA_ "ECGUsedTxSignal" SG_ 2612043992 PARSEDPhysGWM_ECG2toABS 1;
BA_ "GenSigSendType" SG_ 2612043992 PARSEDPhysGWM_ECG2toABS 3;
BA_ "ECGUsedTxSignal" SG_ 2609946840 OTAPhysGWM_ECGtoABS 1;
BA_ "GenSigSendType" SG_ 2609946840 OTAPhysGWM_ECGtoABS 3;
BA_ "ECGUsedRxSignal" SG_ 2611175464 PARSEDPhysABStoGWM_ECG 1;
BA_ "GenSigSendType" SG_ 2611175464 PARSEDPhysABStoGWM_ECG 3;
BA_ "ECGUsedRxSignal" SG_ 2612224040 PARSEDPhysABS2toGWM_ECG 1;
BA_ "GenSigSendType" SG_ 2612224040 PARSEDPhysABS2toGWM_ECG 3;
BA_ "ECGUsedRxSignal" SG_ 2610126888 OTAPhysABStoGWM_ECG 1;
BA_ "GenSigSendType" SG_ 2610126888 OTAPhysABStoGWM_ECG 3;
BA_ "ECGUsedTxSignal" SG_ 2610988248 PARSEDPhysGWM_ECGtoIPMA 1;
BA_ "ECGUsedTxSignal" SG_ 2609939672 OTAPhysGWM_ECGtoIPMA 1;
BA_ "GenSigSendType" SG_ 2609939672 OTAPhysGWM_ECGtoIPMA 3;
BA_ "U_T6_MCA_MY2020_Rx" SG_ 1114 TrailCtlSwtch_B_Stat2 1;
BA_ "U_P702_MY2021_Rx" SG_ 1114 TrailCtlSwtch_B_Stat2 1;
BA_ "U_T6_MCA_MY2020_Rx" SG_ 1116 TrlrAidSetup_D2_Rq 1;
BA_ "U_P702_MY2021_Rx" SG_ 1116 TrlrAidSetup_D2_Rq 1;
BA_ "U_T6_MCA_MY2020_Rx" SG_ 1116 TrlrAidEnbl_D2_Rq 1;
BA_ "U_P702_MY2021_Rx" SG_ 1116 TrlrAidEnbl_D2_Rq 1;
BA_ "U_P702_MY2021_Rx" SG_ 1116 TrlrIdType_D_Stat 1;
BA_ "U_T6_MCA_MY2020_Rx" SG_ 1116 TrlrIdType_D_Stat 1;
BA_ "ECGUsedRxSignal" SG_ 2611175457 PARSEDPhysIPMAtoGWM_ECG 1;
BA_ "GenSigSendType" SG_ 2611175457 PARSEDPhysIPMAtoGWM_ECG 3;
BA_ "ECGUsedRxSignal" SG_ 2612224033 PARSEDPhysIPMA2toGWM_ECG 1;
BA_ "GenSigSendType" SG_ 2612224033 PARSEDPhysIPMA2toGWM_ECG 3;
BA_ "ECGUsedRxSignal" SG_ 2610126881 OTAPhysIPMAtoGWM_ECG 1;
BA_ "GenSigSendType" SG_ 2610126881 OTAPhysIPMAtoGWM_ECG 3;
BA_ "ContentDependant" SG_ 1085 ULoRgenTestMde_B_Stat 1;
BA_ "U_P702_MY2021_Tx" SG_ 1085 ULoRgenTestMde_B_Stat 1;
BA_ "U_T6_MCA_MY2020_Tx" SG_ 1085 ULoRgenTestMde_B_Stat 1;
BA_ "U_P702_MY2021_Tx" SG_ 1085 PwSrcULoOvrTe_B_Actl 1;
BA_ "U_T6_MCA_MY2020_Tx" SG_ 1085 PwSrcULoOvrTe_B_Actl 1;
BA_ "U_P702_MY2021_Tx" SG_ 1085 PwSrcULoFalt_D_Stat 1;
BA_ "U_T6_MCA_MY2020_Tx" SG_ 1085 PwSrcULoFalt_D_Stat 1;
BA_ "U_P702_MY2021_Tx" SG_ 1085 PwSrcULoDcnnt_B_Stat 1;
BA_ "U_T6_MCA_MY2020_Tx" SG_ 1085 PwSrcULoDcnnt_B_Stat 1;
BA_ "U_P702_MY2021_Tx" SG_ 1085 PwSrcULo_Pc_Mx 1;
BA_ "U_T6_MCA_MY2020_Tx" SG_ 1085 PwSrcULo_Pc_Mx 1;
BA_ "ContentDependant" SG_ 1085 PwSrcULoComm_B_Falt 1;
BA_ "U_P702_MY2021_Tx" SG_ 1085 PwSrcULoComm_B_Falt 1;
BA_ "U_T6_MCA_MY2020_Tx" SG_ 1085 PwSrcULoComm_B_Falt 1;
BA_ "U_P702_MY2021_Rx" SG_ 1085 PwSrcULo_I_Mx 1;
BA_ "U_P702_MY2021_Tx" SG_ 1085 PwSrcULo_I_Mx 1;
BA_ "U_T6_MCA_MY2020_Tx" SG_ 1085 PwSrcULo_I_Mx 1;
BA_ "U_P702_MY2021_Rx" SG_ 1085 PwSrcULo_I_Actl 1;
BA_ "U_P702_MY2021_Tx" SG_ 1085 PwSrcULo_I_Actl 1;
BA_ "U_T6_MCA_MY2020_Tx" SG_ 1085 PwSrcULo_I_Actl 1;
BA_ "U_P702_MY2021_Rx" SG_ 791 EngAirFilt_B_RqReset 1;
BA_ "CrossOver_InfoCAN" SG_ 791 GpsElMdeSel_B_Rq 1;
BA_ "CrossOver_InfoCAN" SG_ 791 LongTermReset_B_Rq 1;
BA_ "CrossOver_InfoCAN" SG_ 791 DrvEffLvl_No_Stat 1;
BA_ "ECGUsedTxSignal" SG_ 2610970840 PARSEDPhysGWM_ECGtoPCM 1;
BA_ "U_T6_MCA_MY2020_Rx" SG_ 2610970840 PARSEDPhysGWM_ECGtoPCM 1;
BA_ "U_P702_MY2021_Rx" SG_ 2610970840 PARSEDPhysGWM_ECGtoPCM 1;
BA_ "GenSigSendType" SG_ 2610970840 PARSEDPhysGWM_ECGtoPCM 3;
BA_ "ECGUsedTxSignal" SG_ 2609922264 OTAPhysGWM_ECGtoPCM 1;
BA_ "U_T6_MCA_MY2020_Rx" SG_ 2609922264 OTAPhysGWM_ECGtoPCM 1;
BA_ "U_P702_MY2021_Rx" SG_ 2609922264 OTAPhysGWM_ECGtoPCM 1;
BA_ "GenSigSendType" SG_ 2609922264 OTAPhysGWM_ECGtoPCM 3;
BA_ "U_P702_MY2021_Rx" SG_ 868 BattRgenLoStat_D_Qlty 1;
BA_ "GenSigStartValue" SG_ 868 BattRgenLoStat_D_Qlty 1;
BA_ "U_P702_MY2021_Rx" SG_ 868 BattRgenLoSoc_Pc_Actl 1;
BA_ "GenSigStartValue" SG_ 868 BattRgenLoSoc_Pc_Actl 50;
BA_ "U_P702_MY2021_Rx" SG_ 868 BattRgenLoPulse_U_Pred 1;
BA_ "GenSigStartValue" SG_ 868 BattRgenLoPulse_U_Pred 216;
BA_ "U_P702_MY2021_Rx" SG_ 868 BattRgenLoPrtct_B_Stat 1;
BA_ "U_P702_MY2021_Rx" SG_ 868 BattRgenLoDChrg_D_Stat 1;
BA_ "U_P702_MY2021_Rx" SG_ 868 BattRgenLoDchrg_B_Rq 1;
BA_ "U_P702_MY2021_Rx" SG_ 868 BattRgenLoChrg_D_Stat 1;
BA_ "U_P702_MY2021_Rx" SG_ 868 BattRgenLoChrg_B_Rq 1;
BA_ "U_P702_MY2021_Rx" SG_ 868 BattRgenLo_T_Est 1;
BA_ "U_P702_MY2021_Rx" SG_ 868 BattRgenLo_B_Falt 1;
BA_ "U_P702_MY2021_Rx" SG_ 867 BattRgenLoBalnc_B_Rq 1;
BA_ "U_P702_MY2021_Rx" SG_ 867 BattRgenLo_Te_Hi 1;
BA_ "GenSigStartValue" SG_ 867 BattRgenLo_Te_Hi 45;
BA_ "U_P702_MY2021_Rx" SG_ 867 BattRgenLo_Te_Actl 1;
BA_ "GenSigStartValue" SG_ 867 BattRgenLo_Te_Actl 85;
BA_ "U_P702_MY2021_Rx" SG_ 867 BattRgenLo_R_Actl 1;
BA_ "U_P702_MY2021_Rx" SG_ 867 BattRgenLo_AhRide_Actl 1;
BA_ "GenSigStartValue" SG_ 867 BattRgenLo_AhRide_Actl 12800;
BA_ "U_P702_MY2021_Rx" SG_ 867 BattRgenLo_Ah_Actl 1;
BA_ "GenSigStartValue" SG_ 867 BattRgenLo_Ah_Actl 50;
BA_ "U_P702_MY2021_Rx" SG_ 866 BattRgenLoOpen_U_Actl 1;
BA_ "GenSigStartValue" SG_ 866 BattRgenLoOpen_U_Actl 180;
BA_ "U_P702_MY2021_Rx" SG_ 866 BattRgenLoDchrg_U_Mn 1;
BA_ "GenSigStartValue" SG_ 866 BattRgenLoDchrg_U_Mn 280;
BA_ "U_P702_MY2021_Rx" SG_ 866 BattRgenLoDchrg_I_Mx 1;
BA_ "U_P702_MY2021_Rx" SG_ 866 BattRgenLoChrg_U_Mx 1;
BA_ "GenSigStartValue" SG_ 866 BattRgenLoChrg_U_Mx 96;
BA_ "U_P702_MY2021_Rx" SG_ 866 BattRgenLoChrg_I_Mx 1;
BA_ "U_P702_MY2021_Rx" SG_ 865 BattRgenLo_U_Actl 1;
BA_ "GenSigStartValue" SG_ 865 BattRgenLo_U_Actl 768;
BA_ "U_P702_MY2021_Rx" SG_ 865 BattRgenLo_I_Actl 1;
BA_ "GenSigStartValue" SG_ 865 BattRgenLo_I_Actl 32768;
BA_ "U_T6_MCA_MY2020_Tx" SG_ 2611175440 PARSEDPhysPCMtoGWM_ECG 1;
BA_ "U_P702_MY2021_Tx" SG_ 2611175440 PARSEDPhysPCMtoGWM_ECG 1;
BA_ "ECGUsedRxSignal" SG_ 2611175440 PARSEDPhysPCMtoGWM_ECG 1;
BA_ "GenSigSendType" SG_ 2611175440 PARSEDPhysPCMtoGWM_ECG 3;
BA_ "U_T6_MCA_MY2020_Tx" SG_ 2610126864 OTAPhysPCMtoGWM_ECG 1;
BA_ "U_P702_MY2021_Tx" SG_ 2610126864 OTAPhysPCMtoGWM_ECG 1;
BA_ "ECGUsedRxSignal" SG_ 2610126864 OTAPhysPCMtoGWM_ECG 1;
BA_ "GenSigSendType" SG_ 2610126864 OTAPhysPCMtoGWM_ECG 3;
BA_ "GenSigSendType" SG_ 2611175441 PARSEDPhysHPCMtoGWM_ECG 3;
BA_ "GenSigSendType" SG_ 2612224017 PARSEDPhysHPCM2toGWM_ECG 3;
BA_ "U_P702_MY2021_Tx" SG_ 2610126865 OTAPhysHPCMtoGWM_ECG 1;
BA_ "GenSigSendType" SG_ 2610126865 OTAPhysHPCMtoGWM_ECG 3;
BA_ "U_P702_MY2021_Tx" SG_ 1679 UUDTSOBDMCResponse4 1;
BA_ "GenSigSendType" SG_ 1679 UUDTSOBDMCResponse4 3;
BA_ "U_P702_MY2021_Tx" SG_ 1678 UUDTSOBDMCResponse3 1;
BA_ "GenSigSendType" SG_ 1678 UUDTSOBDMCResponse3 3;
BA_ "U_P702_MY2021_Tx" SG_ 1677 UUDTSOBDMCResponse2 1;
BA_ "GenSigSendType" SG_ 1677 UUDTSOBDMCResponse2 3;
BA_ "U_P702_MY2021_Tx" SG_ 1676 UUDTSOBDMCResponse1 1;
BA_ "GenSigSendType" SG_ 1676 UUDTSOBDMCResponse1 3;
BA_ "GenSigStartValueInteger" SG_ 1445 SOBDMC_AutoSarNMReserved4 255;
BA_ "ContentDependant" SG_ 1445 SOBDMC_AutoSarNMReserved4 1;
BA_ "GenSigStartValue" SG_ 1445 SOBDMC_AutoSarNMReserved4 255;
BA_ "U_P702_MY2021_Tx" SG_ 1445 SOBDMC_AutoSarNMReserved4 1;
BA_ "GenSigStartValueInteger" SG_ 1445 SOBDMC_AutoSarNMReserved3 255;
BA_ "ContentDependant" SG_ 1445 SOBDMC_AutoSarNMReserved3 1;
BA_ "GenSigStartValue" SG_ 1445 SOBDMC_AutoSarNMReserved3 255;
BA_ "U_P702_MY2021_Tx" SG_ 1445 SOBDMC_AutoSarNMReserved3 1;
BA_ "GenSigStartValueInteger" SG_ 1445 SOBDMC_AutoSarNMReserved2 255;
BA_ "ContentDependant" SG_ 1445 SOBDMC_AutoSarNMReserved2 1;
BA_ "GenSigStartValue" SG_ 1445 SOBDMC_AutoSarNMReserved2 255;
BA_ "U_P702_MY2021_Tx" SG_ 1445 SOBDMC_AutoSarNMReserved2 1;
BA_ "GenSigStartValueInteger" SG_ 1445 SOBDMC_AutoSarNMReserved1 255;
BA_ "ContentDependant" SG_ 1445 SOBDMC_AutoSarNMReserved1 1;
BA_ "GenSigStartValue" SG_ 1445 SOBDMC_AutoSarNMReserved1 255;
BA_ "U_P702_MY2021_Tx" SG_ 1445 SOBDMC_AutoSarNMReserved1 1;
BA_ "GenSigStartValueInteger" SG_ 1445 SOBDMC_AutoSarNMNodeId 165;
BA_ "ContentDependant" SG_ 1445 SOBDMC_AutoSarNMNodeId 1;
BA_ "GenSigStartValue" SG_ 1445 SOBDMC_AutoSarNMNodeId 165;
BA_ "U_P702_MY2021_Tx" SG_ 1445 SOBDMC_AutoSarNMNodeId 1;
BA_ "ContentDependant" SG_ 1445 SOBDMC_AutoSarNMControl 1;
BA_ "U_P702_MY2021_Tx" SG_ 1445 SOBDMC_AutoSarNMControl 1;
BA_ "GenSigStartValueInteger" SG_ 1445 SOBDMC_GWOnBoardTester 255;
BA_ "ContentDependant" SG_ 1445 SOBDMC_GWOnBoardTester 1;
BA_ "GenSigStartValue" SG_ 1445 SOBDMC_GWOnBoardTester 255;
BA_ "U_P702_MY2021_Tx" SG_ 1445 SOBDMC_GWOnBoardTester 1;
BA_ "GenSigStartValueInteger" SG_ 1445 SOBDMC_GWNMProxy 255;
BA_ "ContentDependant" SG_ 1445 SOBDMC_GWNMProxy 1;
BA_ "GenSigStartValue" SG_ 1445 SOBDMC_GWNMProxy 255;
BA_ "U_P702_MY2021_Tx" SG_ 1445 SOBDMC_GWNMProxy 1;
BA_ "U_CX727_MY2021_Tx" SG_ 1144 WakeAlarm0_T_Rq 1;
BA_ "GenSigStartValue" SG_ 1144 WakeAlarm0_T_Rq 32767;
BA_ "GenSigStartValueInteger" SG_ 1144 WakeAlarm0_T_Rq 32767;
BA_ "U_CX727_MY2021_Tx" SG_ 1144 WakeAlarm0_B_Typ 1;
BA_ "GenSigSendType" SG_ 1144 WakeAlarm0_B_Typ 3;
BA_ "U_CX727_MY2021_Tx" SG_ 1144 PreCondBatt_B_Actl 1;
BA_ "GenSigSendType" SG_ 1144 PreCondBatt_B_Actl 3;
BA_ "U_CX727_MY2021_Tx" SG_ 1144 HtrnDcdcDis_B_Rq 1;
BA_ "U_CX727_MY2021_Rx" SG_ 1144 HtrnDcdcDis_B_Rq 1;
BA_ "GenSigSendType" SG_ 1144 HtrnDcdcDis_B_Rq 3;
BA_ "U_CX727_MY2021_Tx" SG_ 1144 ChrgNowEvnt_B_Stat 1;
BA_ "GenSigSendType" SG_ 1144 ChrgNowEvnt_B_Stat 3;
BA_ "U_CX727_MY2021_Tx" SG_ 1144 CabinDrvSustn_B_Rq 1;
BA_ "U_CX727_MY2021_Rx" SG_ 1144 CabinDrvSustn_B_Rq 1;
BA_ "GenSigSendType" SG_ 1144 CabinDrvSustn_B_Rq 3;
BA_ "U_P702_MY2021_Tx" SG_ 1144 BattChrgTrgtSoC_D_Rq 1;
BA_ "GenSigSendType" SG_ 1144 CabnEvapSovFront_B_Rq 3;
BA_ "WakeupSignal" SG_ 1144 CabnEvapSovFront_B_Rq 1;
BA_ "U_P702_MY2021_Tx" SG_ 1144 CabnEvapSovFront_B_Rq 1;
BA_ "GenSigSendType" SG_ 1144 HeatCoreSovRear_B_Rq 3;
BA_ "WakeupSignal" SG_ 1144 HeatCoreSovRear_B_Rq 1;
BA_ "U_P702_MY2021_Tx" SG_ 1144 HeatCoreSovRear_B_Rq 1;
BA_ "GenSigSendType" SG_ 1144 BattChlrSov_B_Rq 3;
BA_ "WakeupSignal" SG_ 1144 BattChlrSov_B_Rq 1;
BA_ "U_P702_MY2021_Tx" SG_ 1144 BattChlrSov_B_Rq 1;
BA_ "GenSigSendType" SG_ 1144 CabnEvapSovRear_B_Rq 3;
BA_ "WakeupSignal" SG_ 1144 CabnEvapSovRear_B_Rq 1;
BA_ "U_P702_MY2021_Tx" SG_ 1144 CabnEvapSovRear_B_Rq 1;
BA_ "GenSigSendType" SG_ 1144 BrkAppl_D_RqPt 3;
BA_ "U_CX727_MY2021_Rx" SG_ 1144 BrkAppl_D_RqPt 1;
BA_ "U_T6_MCA_MY2020_Rx" SG_ 1144 BrkAppl_D_RqPt 1;
BA_ "U_P702_MY2021_Tx" SG_ 1144 BrkAppl_D_RqPt 1;
BA_ "GenSigSendType" SG_ 1144 HtrnCnnctPwr_B_Stat 3;
BA_ "U_P702_MY2021_Tx" SG_ 1144 HtrnCnnctPwr_B_Stat 1;
BA_ "GenSigSendType" SG_ 1144 PtcHtr_D_Stat 3;
BA_ "U_CX727_MY2021_Rx" SG_ 1144 PtcHtr_D_Stat 1;
BA_ "U_P702_MY2021_Rx" SG_ 1144 PtcHtr_D_Stat 1;
BA_ "U_P702_MY2021_Tx" SG_ 1144 PtcHtr_D_Stat 1;
BA_ "GenSigSendType" SG_ 1144 HtrnClntFlw_D_Rq 3;
BA_ "U_P702_MY2021_Tx" SG_ 1144 HtrnClntFlw_D_Rq 1;
BA_ "GenSigSendType" SG_ 1144 BattTracDrvSustn_B_Rq 3;
BA_ "U_CX727_MY2021_Rx" SG_ 1144 BattTracDrvSustn_B_Rq 1;
BA_ "U_P702_MY2021_Tx" SG_ 1144 BattTracDrvSustn_B_Rq 1;
BA_ "GenSigSendType" SG_ 1144 BattTracClntVlv_B_Rq 3;
BA_ "U_P702_MY2021_Tx" SG_ 1144 BattTracClntVlv_B_Rq 1;
BA_ "U_CX727_MY2021_Tx" SG_ 1141 OfbChrgSetSync_D_Stat 1;
BA_ "ECGUsedRxSignal" SG_ 1141 OfbChrgSetSync_D_Stat 1;
BA_ "U_CX727_MY2021_Tx" SG_ 1141 PtRmtRprt_D_Rq 1;
BA_ "ECGUsedRxSignal" SG_ 1141 PtRmtRprt_D_Rq 1;
BA_ "WakeupSignal" SG_ 1141 PtRmtRprt_D_Rq 1;
BA_ "GenSigStartValueInteger" SG_ 1141 MtrTrac2_Tq_Actl 4095;
BA_ "GenSigStartValue" SG_ 1141 MtrTrac2_Tq_Actl 4095;
BA_ "U_P702_MY2021_Tx" SG_ 1141 MtrTrac2_Tq_Actl 1;
BA_ "ECGUsedRxSignal" SG_ 1141 MtrTrac2_Tq_Actl 1;
BA_ "ECGUsedRxSignal" SG_ 1141 NtfctnConflict1_D_Rq 1;
BA_ "U_P702_MY2021_Tx" SG_ 1141 NtfctnConflict1_D_Rq 1;
BA_ "U_CX727_MY2021_Tx" SG_ 1140 RgenEvntLvl_Pc_Dsply 1;
BA_ "GenSigStartValue" SG_ 1140 RgenEvntLvl_Pc_Dsply 1022;
BA_ "GenSigStartValueInteger" SG_ 1140 RgenEvntLvl_Pc_Dsply 1023;
BA_ "U_CX727_MY2021_Tx" SG_ 1140 BrkEvntComplt_B_Dsply 1;
BA_ "U_P702_MY2021_Tx" SG_ 1140 PreCondStat_D_Dsply 1;
BA_ "ECGUsedRxSignal" SG_ 1140 PreCondStat_D_Dsply 1;
BA_ "U_CX727_MY2021_Tx" SG_ 1139 ActChrgStrtYr_No2_Actl 1;
BA_ "ECGUsedRxSignal" SG_ 1139 ActChrgStrtYr_No2_Actl 1;
BA_ "U_P702_MY2021_Tx" SG_ 1139 BattChrgTrgtLMax_T_Est 1;
BA_ "U_P702_MY2021_Tx" SG_ 1139 ActChrgStrtYr_No_Actl 1;
BA_ "ECGUsedRxSignal" SG_ 1139 ActChrgStrtYr_No_Actl 1;
BA_ "U_P702_MY2021_Tx" SG_ 1139 ActChrgStrtMin_No_Actl 1;
BA_ "ECGUsedRxSignal" SG_ 1139 ActChrgStrtMin_No_Actl 1;
BA_ "U_P702_MY2021_Tx" SG_ 1139 ActChrgStrtHr_No_Actl 1;
BA_ "ECGUsedRxSignal" SG_ 1139 ActChrgStrtHr_No_Actl 1;
BA_ "U_P702_MY2021_Tx" SG_ 1139 ActChrgStrtDay_No_Actl 1;
BA_ "GenSigStartValue" SG_ 1139 ActChrgStrtDay_No_Actl 1;
BA_ "GenSigStartValueInteger" SG_ 1139 ActChrgStrtDay_No_Actl 1;
BA_ "ECGUsedRxSignal" SG_ 1139 ActChrgStrtDay_No_Actl 1;
BA_ "U_P702_MY2021_Tx" SG_ 1139 ActChrgStrMnth_No_Actl 1;
BA_ "GenSigStartValue" SG_ 1139 ActChrgStrMnth_No_Actl 1;
BA_ "GenSigStartValueInteger" SG_ 1139 ActChrgStrMnth_No_Actl 1;
BA_ "ECGUsedRxSignal" SG_ 1139 ActChrgStrMnth_No_Actl 1;
BA_ "ECGUsedRxSignal" SG_ 1138 ActChrgEndYr_No2_Actl 1;
BA_ "U_CX727_MY2021_Tx" SG_ 1138 ActChrgEndYr_No2_Actl 1;
BA_ "U_P702_MY2021_Tx" SG_ 1138 BattChrgTrgtLMin_T_Est 1;
BA_ "U_P702_MY2021_Tx" SG_ 1138 ActChrgEndYr_No_Actl 1;
BA_ "ECGUsedRxSignal" SG_ 1138 ActChrgEndYr_No_Actl 1;
BA_ "U_P702_MY2021_Tx" SG_ 1138 ActChrgEndMnth_No_Actl 1;
BA_ "GenSigStartValue" SG_ 1138 ActChrgEndMnth_No_Actl 1;
BA_ "GenSigStartValueInteger" SG_ 1138 ActChrgEndMnth_No_Actl 1;
BA_ "ECGUsedRxSignal" SG_ 1138 ActChrgEndMnth_No_Actl 1;
BA_ "U_P702_MY2021_Tx" SG_ 1138 ActChrgEndMin_No_Actl 1;
BA_ "ECGUsedRxSignal" SG_ 1138 ActChrgEndMin_No_Actl 1;
BA_ "U_P702_MY2021_Tx" SG_ 1138 ActChrgEndHr_No_Actl 1;
BA_ "ECGUsedRxSignal" SG_ 1138 ActChrgEndHr_No_Actl 1;
BA_ "U_P702_MY2021_Tx" SG_ 1138 ActChrgEndDay_No_Actl 1;
BA_ "GenSigStartValue" SG_ 1138 ActChrgEndDay_No_Actl 1;
BA_ "GenSigStartValueInteger" SG_ 1138 ActChrgEndDay_No_Actl 1;
BA_ "ECGUsedRxSignal" SG_ 1138 ActChrgEndDay_No_Actl 1;
BA_ "U_P702_MY2021_Tx" SG_ 1089 Mtr2Aout_W_ActlMntr 1;
BA_ "GenSigStartValue" SG_ 1089 Mtr2Aout_W_ActlMntr 1023;
BA_ "GenSigStartValueInteger" SG_ 1089 Mtr2Aout_W_ActlMntr 1023;
BA_ "ECGUsedRxSignal" SG_ 1089 Mtr2Aout_W_ActlMntr 1;
BA_ "U_P702_MY2021_Tx" SG_ 1089 Inv1_Te_Actl 1;
BA_ "GenSigStartValue" SG_ 1089 Inv1_Te_Actl 254;
BA_ "GenSigStartValueInteger" SG_ 1089 Inv1_Te_Actl 254;
BA_ "U_P702_MY2021_Tx" SG_ 1089 MtrTrac2Coil_Te_Actl 1;
BA_ "GenSigStartValue" SG_ 1089 MtrTrac2Coil_Te_Actl 254;
BA_ "GenSigStartValueInteger" SG_ 1089 MtrTrac2Coil_Te_Actl 254;
BA_ "ECGUsedRxSignal" SG_ 1089 MtrTrac2Coil_Te_Actl 1;
BA_ "U_P702_MY2021_Tx" SG_ 1089 MtrTrac2_U_Actl 1;
BA_ "GenSigStartValue" SG_ 1089 MtrTrac2_U_Actl 1023;
BA_ "GenSigStartValueInteger" SG_ 1089 MtrTrac2_U_Actl 1023;
BA_ "U_P702_MY2021_Tx" SG_ 1089 MtrTrac2Falt_B_Stat 1;
BA_ "U_P702_MY2021_Tx" SG_ 1089 MtrTrac2TeAlrm_B_Stat 1;
BA_ "ECGUsedRxSignal" SG_ 1089 MtrTrac2TeAlrm_B_Stat 1;
BA_ "U_P702_MY2021_Tx" SG_ 1089 Mtr2CntlTeAlrm_B_Stat 1;
BA_ "ECGUsedRxSignal" SG_ 1089 Mtr2CntlTeAlrm_B_Stat 1;
BA_ "U_P702_MY2021_Tx" SG_ 1089 MtrTrac2Inv_Te_Actl 1;
BA_ "GenSigStartValue" SG_ 1089 MtrTrac2Inv_Te_Actl 214;
BA_ "GenSigStartValueInteger" SG_ 1089 MtrTrac2Inv_Te_Actl 214;
BA_ "ECGUsedRxSignal" SG_ 1089 MtrTrac2Inv_Te_Actl 1;
BA_ "U_P702_MY2021_Tx" SG_ 1089 MtrTrac2_I_Actl 1;
BA_ "GenSigStartValueInteger" SG_ 1089 MtrTrac2_I_Actl 10000;
BA_ "U_CX727_MY2021_Tx" SG_ 1088 ChrgTMatch_B_Stat 1;
BA_ "U_P702_MY2021_Tx" SG_ 1088 ChrgStat_D2_Dsply 1;
BA_ "ECGUsedRxSignal" SG_ 1088 ChrgStat_D2_Dsply 1;
BA_ "U_P702_MY2021_Tx" SG_ 1088 HvacPrecondRecirc_D_Rq 1;
BA_ "U_P702_MY2021_Tx" SG_ 1088 HvacPrecondMode2_D_Rq 1;
BA_ "ContentDependant" SG_ 1088 HvacPrecondMode2_D_Rq 1;
BA_ "WakeupSignal" SG_ 1088 HvacPrecondMode2_D_Rq 1;
BA_ "U_P702_MY2021_Tx" SG_ 1088 HvacPrecondBlwr2_D_Rq 1;
BA_ "ContentDependant" SG_ 1088 HvacPrecondBlwr2_D_Rq 1;
BA_ "WakeupSignal" SG_ 1088 HvacPrecondBlwr2_D_Rq 1;
BA_ "U_P702_MY2021_Tx" SG_ 1088 HvacPrecondAC_D_Rq 1;
BA_ "U_P702_MY2021_Tx" SG_ 1088 HvacPrecond_Te_Rq 1;
BA_ "GenSigStartValue" SG_ 1088 HvacPrecond_Te_Rq 2;
BA_ "GenSigStartValueInteger" SG_ 1088 HvacPrecond_Te_Rq 2;
BA_ "U_P702_MY2021_Tx" SG_ 1088 BattChrgInhbt_D_Rq 1;
BA_ "U_P702_MY2021_Tx" SG_ 1040 ElCmprEnbl_B_Rq 1;
BA_ "U_P702_MY2021_Rx" SG_ 1040 ElCmprEnbl_B_Rq 1;
BA_ "U_CX727_MY2021_Rx" SG_ 1040 ElCmprEnbl_B_Rq 1;
BA_ "U_P702_MY2021_Tx" SG_ 1040 ElCmpr_N_Rq 1;
BA_ "GenSigSendType" SG_ 1016 ChrgGoTElement_B_Dsply 3;
BA_ "ECGUsedRxSignal" SG_ 1016 ChrgGoTElement_B_Dsply 1;
BA_ "U_CX727_MY2021_Tx" SG_ 1016 ChrgGoTElement_B_Dsply 1;
BA_ "U_P702_MY2021_Tx" SG_ 1016 ChrgLocIdCurnt_D_Uns 1;
BA_ "GenSigSendType" SG_ 1016 ChrgLocIdCurnt_D_Uns 3;
BA_ "ECGUsedRxSignal" SG_ 1016 ChrgLocIdCurnt_D_Uns 1;
BA_ "U_P702_MY2021_Tx" SG_ 1016 ChrgGoTTouchEnbl_B_Rq 1;
BA_ "GenSigSendType" SG_ 1016 ChrgGoTTouchEnbl_B_Rq 3;
BA_ "U_P702_MY2021_Tx" SG_ 1016 ChrgGoTTouch_B_Stat 1;
BA_ "GenSigSendType" SG_ 1016 ChrgGoTTouch_B_Stat 3;
BA_ "ECGUsedRxSignal" SG_ 1016 ChrgGoTTouch_B_Stat 1;
BA_ "U_P702_MY2021_Tx" SG_ 1016 ChrgGoTPrcond_D_Stat 1;
BA_ "ECGUsedRxSignal" SG_ 1016 ChrgGoTPrcond_D_Stat 1;
BA_ "U_P702_MY2021_Tx" SG_ 1016 ChrgGoTNext_D_Stat 1;
BA_ "MetaData" SG_ 1016 ChrgGoTNext_D_Stat 1;
BA_ "CrossOver_InfoCAN" SG_ 1016 ChrgGoTNext_D_Stat 1;
BA_ "GenSigSendType" SG_ 1016 ChrgGoTNext_D_Stat 3;
BA_ "ECGUsedRxSignal" SG_ 1016 ChrgGoTNext_D_Stat 1;
BA_ "U_P702_MY2021_Tx" SG_ 1016 ChrgGoTMnte_D_Stat 1;
BA_ "MetaData" SG_ 1016 ChrgGoTMnte_D_Stat 1;
BA_ "CrossOver_InfoCAN" SG_ 1016 ChrgGoTMnte_D_Stat 1;
BA_ "ECGUsedRxSignal" SG_ 1016 ChrgGoTMnte_D_Stat 1;
BA_ "U_P702_MY2021_Tx" SG_ 1016 ChrgGoTHr_T_Stat 1;
BA_ "GenSigStartValue" SG_ 1016 ChrgGoTHr_T_Stat 30;
BA_ "GenSigStartValueInteger" SG_ 1016 ChrgGoTHr_T_Stat 30;
BA_ "ECGUsedRxSignal" SG_ 1016 ChrgGoTHr_T_Stat 1;
BA_ "U_P702_MY2021_Tx" SG_ 1016 ChrgGoTExtHtrEnbl_B_Rq 1;
BA_ "GenSigSendType" SG_ 1016 ChrgGoTExtHtrEnbl_B_Rq 3;
BA_ "U_P702_MY2021_Tx" SG_ 1016 ChrgGoTExtHtr_B_Stat 1;
BA_ "GenSigSendType" SG_ 1016 ChrgGoTExtHtr_B_Stat 3;
BA_ "ECGUsedRxSignal" SG_ 1016 ChrgGoTExtHtr_B_Stat 1;
BA_ "U_P702_MY2021_Tx" SG_ 1016 ChrgGoTElement_D_Stat 1;
BA_ "MetaData" SG_ 1016 ChrgGoTElement_D_Stat 1;
BA_ "CrossOver_InfoCAN" SG_ 1016 ChrgGoTElement_D_Stat 1;
BA_ "GenSigSendType" SG_ 1016 ChrgGoTElement_D_Stat 3;
BA_ "ECGUsedRxSignal" SG_ 1016 ChrgGoTElement_D_Stat 1;
BA_ "U_P702_MY2021_Tx" SG_ 1016 ChrgGoTAllOn_B_Stat 1;
BA_ "GenSigSendType" SG_ 1016 ChrgGoTAllOn_B_Stat 3;
BA_ "ECGUsedRxSignal" SG_ 1016 ChrgGoTAllOn_B_Stat 1;
BA_ "U_P702_MY2021_Tx" SG_ 1013 ChrgToPcWkndSav_D_Stat 1;
BA_ "CrossOver_InfoCAN" SG_ 1013 ChrgToPcWkndSav_D_Stat 1;
BA_ "ECGUsedRxSignal" SG_ 1013 ChrgToPcWkndSav_D_Stat 1;
BA_ "U_P702_MY2021_Tx" SG_ 1013 ChrgToPcWkdySav_D_Stat 1;
BA_ "CrossOver_InfoCAN" SG_ 1013 ChrgToPcWkdySav_D_Stat 1;
BA_ "ECGUsedRxSignal" SG_ 1013 ChrgToPcWkdySav_D_Stat 1;
BA_ "U_P702_MY2021_Tx" SG_ 1013 ChrgProgIdSaved_D_Stat 1;
BA_ "MetaData" SG_ 1013 ChrgProgIdSaved_D_Stat 1;
BA_ "GenSigSendType" SG_ 1013 ChrgProgIdSaved_D_Stat 3;
BA_ "ECGUsedRxSignal" SG_ 1013 ChrgProgIdSaved_D_Stat 1;
BA_ "U_P702_MY2021_Tx" SG_ 1013 ChrgNowEnbl_B_Saved 1;
BA_ "ECGUsedRxSignal" SG_ 1013 ChrgNowEnbl_B_Saved 1;
BA_ "U_P702_MY2021_Tx" SG_ 1013 ChrgLocIdUnsAck_B_Stat 1;
BA_ "GenSigSendType" SG_ 1013 ChrgLocIdUnsAck_B_Stat 3;
BA_ "ECGUsedRxSignal" SG_ 1013 ChrgLocIdUnsAck_B_Stat 1;
BA_ "U_P702_MY2021_Tx" SG_ 1013 ChrgLocIdCurnt_D_Sav 1;
BA_ "MetaData" SG_ 1013 ChrgLocIdCurnt_D_Sav 1;
BA_ "GenSigSendType" SG_ 1013 ChrgLocIdCurnt_D_Sav 3;
BA_ "ECGUsedRxSignal" SG_ 1013 ChrgLocIdCurnt_D_Sav 1;
BA_ "U_P702_MY2021_Tx" SG_ 1013 ChrgPrflWknd_No_Actl 1;
BA_ "ECGUsedRxSignal" SG_ 1013 ChrgPrflWknd_No_Actl 1;
BA_ "U_P702_MY2021_Tx" SG_ 1013 ChrgPrflWkdy_No_Actl 1;
BA_ "ECGUsedRxSignal" SG_ 1013 ChrgPrflWkdy_No_Actl 1;
BA_ "GenSigSendType" SG_ 1012 ChrgNowCurnt_B_Dsply 3;
BA_ "ECGUsedRxSignal" SG_ 1012 ChrgNowCurnt_B_Dsply 1;
BA_ "U_CX727_MY2021_Tx" SG_ 1012 ChrgNowCurnt_B_Dsply 1;
BA_ "U_P702_MY2021_Tx" SG_ 1012 ChrgNowCurnt_B_Dsply 1;
BA_ "GenSigSendType" SG_ 1012 ChrgLocSaved_B_Dsply 3;
BA_ "ECGUsedRxSignal" SG_ 1012 ChrgLocSaved_B_Dsply 1;
BA_ "U_CX727_MY2021_Tx" SG_ 1012 ChrgLocSaved_B_Dsply 1;
BA_ "U_P702_MY2021_Tx" SG_ 1012 ChrgLocSaved_B_Dsply 1;
BA_ "U_P702_MY2021_Tx" SG_ 1012 ChrgLocLongPostv_B_Sav 1;
BA_ "CrossOver_InfoCAN" SG_ 1012 ChrgLocLongPostv_B_Sav 1;
BA_ "ECGUsedRxSignal" SG_ 1012 ChrgLocLongPostv_B_Sav 1;
BA_ "U_P702_MY2021_Tx" SG_ 1012 ChrgLocLongFrct_An_Sav 1;
BA_ "GenSigStartValue" SG_ 1012 ChrgLocLongFrct_An_Sav 1048575;
BA_ "GenSigStartValueInteger" SG_ 1012 ChrgLocLongFrct_An_Sav 1048575;
BA_ "ECGUsedRxSignal" SG_ 1012 ChrgLocLongFrct_An_Sav 1;
BA_ "U_P702_MY2021_Tx" SG_ 1012 ChrgLocLongDeg_An_Sav 1;
BA_ "ECGUsedRxSignal" SG_ 1012 ChrgLocLongDeg_An_Sav 1;
BA_ "U_P702_MY2021_Tx" SG_ 1012 ChrgLocLattPostv_B_Sav 1;
BA_ "CrossOver_InfoCAN" SG_ 1012 ChrgLocLattPostv_B_Sav 1;
BA_ "ECGUsedRxSignal" SG_ 1012 ChrgLocLattPostv_B_Sav 1;
BA_ "U_P702_MY2021_Tx" SG_ 1012 ChrgLocLattFrct_An_Sav 1;
BA_ "GenSigStartValue" SG_ 1012 ChrgLocLattFrct_An_Sav 1048575;
BA_ "GenSigStartValueInteger" SG_ 1012 ChrgLocLattFrct_An_Sav 1048575;
BA_ "ECGUsedRxSignal" SG_ 1012 ChrgLocLattFrct_An_Sav 1;
BA_ "U_P702_MY2021_Tx" SG_ 1012 ChrgLocLattDeg_An_Sav 1;
BA_ "ECGUsedRxSignal" SG_ 1012 ChrgLocLattDeg_An_Sav 1;
BA_ "U_P702_MY2021_Tx" SG_ 1012 ChrgLocId_D_Sav 1;
BA_ "GenSigSendType" SG_ 1012 ChrgLocId_D_Sav 3;
BA_ "ECGUsedRxSignal" SG_ 1012 ChrgLocId_D_Sav 1;
BA_ "U_P702_MY2021_Tx" SG_ 1011 ChrgLocLongPostv_B_Uns 1;
BA_ "CrossOver_InfoCAN" SG_ 1011 ChrgLocLongPostv_B_Uns 1;
BA_ "ECGUsedRxSignal" SG_ 1011 ChrgLocLongPostv_B_Uns 1;
BA_ "U_P702_MY2021_Tx" SG_ 1011 ChrgLocLongFrct_An_Uns 1;
BA_ "GenSigStartValue" SG_ 1011 ChrgLocLongFrct_An_Uns 1048575;
BA_ "GenSigStartValueInteger" SG_ 1011 ChrgLocLongFrct_An_Uns 1048575;
BA_ "ECGUsedRxSignal" SG_ 1011 ChrgLocLongFrct_An_Uns 1;
BA_ "U_P702_MY2021_Tx" SG_ 1011 ChrgLocLongDeg_An_Uns 1;
BA_ "ECGUsedRxSignal" SG_ 1011 ChrgLocLongDeg_An_Uns 1;
BA_ "U_P702_MY2021_Tx" SG_ 1011 ChrgLocLattPostv_B_Uns 1;
BA_ "CrossOver_InfoCAN" SG_ 1011 ChrgLocLattPostv_B_Uns 1;
BA_ "ECGUsedRxSignal" SG_ 1011 ChrgLocLattPostv_B_Uns 1;
BA_ "U_P702_MY2021_Tx" SG_ 1011 ChrgLocLattFrct_An_Uns 1;
BA_ "GenSigStartValue" SG_ 1011 ChrgLocLattFrct_An_Uns 1048575;
BA_ "GenSigStartValueInteger" SG_ 1011 ChrgLocLattFrct_An_Uns 1048575;
BA_ "ECGUsedRxSignal" SG_ 1011 ChrgLocLattFrct_An_Uns 1;
BA_ "U_P702_MY2021_Tx" SG_ 1011 ChrgLocLattDeg_An_Uns 1;
BA_ "ECGUsedRxSignal" SG_ 1011 ChrgLocLattDeg_An_Uns 1;
BA_ "U_P702_MY2021_Tx" SG_ 1011 ChrgLocId_D_Uns 1;
BA_ "GenSigSendType" SG_ 1011 ChrgLocId_D_Uns 3;
BA_ "ECGUsedRxSignal" SG_ 1011 ChrgLocId_D_Uns 1;
BA_ "U_P702_MY2021_Tx" SG_ 871 BattElecPerf_D_Actl 1;
BA_ "ECGUsedRxSignal" SG_ 871 BattElecPerf_D_Actl 1;
BA_ "U_P702_MY2021_Tx" SG_ 871 BattChrgTrgtLPt_T_Est 1;
BA_ "ECGUsedRxSignal" SG_ 871 BattChrgTrgtLPt_T_Est 1;
BA_ "U_P702_MY2021_Tx" SG_ 871 BattChrgTrgSocPt_T_Est 1;
BA_ "ECGUsedRxSignal" SG_ 871 BattChrgTrgSocPt_T_Est 1;
BA_ "U_P702_MY2021_Tx" SG_ 871 BattChrgCmpltPt_T_Est 1;
BA_ "ECGUsedRxSignal" SG_ 871 BattChrgCmpltPt_T_Est 1;
BA_ "U_P702_MY2021_Tx" SG_ 786 RgenTrip_Pc_Dsply 1;
BA_ "CrossOver_InfoCAN" SG_ 786 RgenTrip_Pc_Dsply 1;
BA_ "ECGUsedRxSignal" SG_ 786 RgenTrip_Pc_Dsply 1;
BA_ "U_P702_MY2021_Tx" SG_ 786 RgenTrip_L_Dsply 1;
BA_ "GenSigStartValue" SG_ 786 RgenTrip_L_Dsply 65535;
BA_ "GenSigStartValueInteger" SG_ 786 RgenTrip_L_Dsply 65535;
BA_ "CrossOver_InfoCAN" SG_ 786 RgenTrip_L_Dsply 1;
BA_ "ECGUsedRxSignal" SG_ 786 RgenTrip_L_Dsply 1;
BA_ "U_P702_MY2021_Tx" SG_ 786 ChrgStat_D_Dsply 1;
BA_ "ECGUsedRxSignal" SG_ 786 ChrgStat_D_Dsply 1;
BA_ "U_P702_MY2021_Rx" SG_ 912 CabnEvapSovFront_D_Stat 1;
BA_ "U_P702_MY2021_Rx" SG_ 912 BattChlrSov_D_Stat 1;
BA_ "U_P702_MY2021_Rx" SG_ 912 BattTracClntVlv_D_Stat 1;
BA_ "U_P702_MY2021_Rx" SG_ 874 BattTracShrtGrnd_D_Falt 1;
BA_ "U_P702_MY2021_Rx" SG_ 874 BattTracShrtBatt_D_Falt 1;
BA_ "U_P702_MY2021_Rx" SG_ 874 BattTracOpnCirct_D_Falt 1;
BA_ "U_P702_MY2021_Rx" SG_ 874 BattChlrShrtGrnd_D_Falt 1;
BA_ "U_P702_MY2021_Rx" SG_ 874 BattChlrShrtBatt_D_Falt 1;
BA_ "U_P702_MY2021_Rx" SG_ 874 BattChlrOpnCirct_D_Falt 1;
BA_ "U_P702_MY2021_Rx" SG_ 651 TelematicsSrvc_D_St 1;
BA_ "ECGUsedTxSignal" SG_ 651 OfbChrgSetSync_D_Rq 1;
BA_ "U_P702_MY2021_Rx" SG_ 529 OnbChrgToPcWknd_D_Actl 1;
BA_ "CrossOver_InfoCAN" SG_ 529 OnbChrgToPcWknd_D_Actl 1;
BA_ "ECGUsedTxSignal" SG_ 529 OnbChrgToPcWknd_D_Actl 1;
BA_ "U_P702_MY2021_Rx" SG_ 529 OnbChrgToPcWkdy_D_Actl 1;
BA_ "CrossOver_InfoCAN" SG_ 529 OnbChrgToPcWkdy_D_Actl 1;
BA_ "ECGUsedTxSignal" SG_ 529 OnbChrgToPcWkdy_D_Actl 1;
BA_ "U_P702_MY2021_Rx" SG_ 529 OnbChrgSetNow_D_Rq 1;
BA_ "U_P702_MY2021_Rx" SG_ 529 OnbChrgSetDelete_B_Rq 1;
BA_ "CrossOver_InfoCAN" SG_ 529 OnbChrgSetDelete_B_Rq 1;
BA_ "U_P702_MY2021_Rx" SG_ 529 OnbChrgPrflWknd_No_Rq 1;
BA_ "U_P702_MY2021_Rx" SG_ 529 OnbChrgPrflWkdy_No_Rq 1;
BA_ "U_P702_MY2021_Rx" SG_ 529 OnbChrgPrflUpdate_B_Rq 1;
BA_ "CrossOver_InfoCAN" SG_ 529 OnbChrgPrflUpdate_B_Rq 1;
BA_ "U_P702_MY2021_Rx" SG_ 529 OnbChrgLocIdUns_B_Rq 1;
BA_ "CrossOver_InfoCAN" SG_ 529 OnbChrgLocIdUns_B_Rq 1;
BA_ "U_P702_MY2021_Rx" SG_ 529 OnbChrgLocIdTrgt_No_Rq 1;
BA_ "MetaData" SG_ 529 OnbChrgLocIdTrgt_No_Rq 1;
BA_ "CrossOver_InfoCAN" SG_ 529 OnbChrgLocIdTrgt_No_Rq 1;
BA_ "U_P702_MY2021_Rx" SG_ 66 immoControlData_T2 1;
BA_ "ContentDependant" SG_ 66 immoControlData_T2 1;
BA_ "U_P702_MY2021_Rx" SG_ 66 immoControlCmd_T2 1;
BA_ "ContentDependant" SG_ 66 immoControlCmd_T2 1;
BA_ "U_P702_MY2021_Rx" SG_ 2610971864 PARSEDPhysGWM_ECGtoHPCM 1;
BA_ "GenSigSendType" SG_ 2610971864 PARSEDPhysGWM_ECGtoHPCM 3;
BA_ "ECGUsedTxSignal" SG_ 2610971864 PARSEDPhysGWM_ECGtoHPCM 1;
BA_ "ECGUsedTxSignal" SG_ 2612002008 PARSEDFuncGWM_ECG 1;
BA_ "U_T6_MCA_MY2020_Rx" SG_ 2612002008 PARSEDFuncGWM_ECG 1;
BA_ "U_P702_MY2021_Rx" SG_ 2612002008 PARSEDFuncGWM_ECG 1;
BA_ "GenSigSendType" SG_ 2612002008 PARSEDFuncGWM_ECG 3;
BA_ "U_P702_MY2021_Rx" SG_ 2609923288 OTAPhysGWM_ECGtoHPCM 1;
BA_ "GenSigSendType" SG_ 2609923288 OTAPhysGWM_ECGtoHPCM 3;
BA_ "ECGUsedTxSignal" SG_ 2609923288 OTAPhysGWM_ECGtoHPCM 1;
BA_ "ECGUsedTxSignal" SG_ 2610953432 OTAFuncGWM_ECG 1;
BA_ "U_T6_MCA_MY2020_Rx" SG_ 2610953432 OTAFuncGWM_ECG 1;
BA_ "U_P702_MY2021_Rx" SG_ 2610953432 OTAFuncGWM_ECG 1;
BA_ "GenSigSendType" SG_ 2610953432 OTAFuncGWM_ECG 3;
BA_ "GenSigSendType" SG_ 2022 TesterPhysicalReqSOBDMC 3;
BA_ "U_P702_MY2021_Rx" SG_ 2022 TesterPhysicalReqSOBDMC 1;
BA_ "CrossOver_InfoCAN" SG_ 1124 GPS_Vdop 1;
BA_ "CrossOver_InfoCAN" SG_ 1124 GPS_Speed 1;
BA_ "CrossOver_InfoCAN" SG_ 1124 GPS_Sat_num_in_view 1;
BA_ "U_P702_MY2021_Rx" SG_ 1124 GPS_Sat_num_in_view 1;
BA_ "CrossOver_InfoCAN" SG_ 1124 GPS_MSL_altitude 1;
BA_ "CrossOver_InfoCAN" SG_ 1124 GPS_Heading 1;
BA_ "CrossOver_InfoCAN" SG_ 1124 GPS_Hdop 1;
BA_ "CrossOver_InfoCAN" SG_ 1124 GPS_dimension 1;
BA_ "U_P702_MY2021_Rx" SG_ 1124 GPS_dimension 1;
BA_ "U_P702_MY2021_Rx" SG_ 1119 CoolFanDcdc_D_Rq 1;
BA_ "U_P702_MY2021_Rx" SG_ 1119 DcdcClntFlw_D_Rq 1;
BA_ "CrossOver_InfoCAN" SG_ 132 GlblClkYr_No_Actl 1;
BA_ "CrossOver_InfoCAN" SG_ 132 GlblClkScnd_No_Actl 1;
BA_ "CrossOver_InfoCAN" SG_ 132 GlblClkMnte_No_Actl 1;
BA_ "CrossOver_InfoCAN" SG_ 132 GlblClkHr_No_Actl 1;
BA_ "CrossOver_InfoCAN" SG_ 132 GlblClkDay_No_Actl 1;
BA_ "GenSigSendType" SG_ 1990 TesterPhysicalReqSODR 3;
BA_ "GenSigSendType" SG_ 1892 TesterPhysicalReqCCM 3;
BA_ "GenSigSendType" SG_ 1798 TesterPhysicalReqIPMA 3;
BA_ "CrossOver_InfoCAN" SG_ 1123 GpsUtcYr_No_Actl 1;
BA_ "GenSigStartValue" SG_ 1123 GpsUtcMnth_No_Actl 1;
BA_ "GenSigStartValueInteger" SG_ 1123 GpsUtcMnth_No_Actl 1;
BA_ "CrossOver_InfoCAN" SG_ 1123 GpsUtcMnth_No_Actl 1;
BA_ "GenSigStartValue" SG_ 1123 GpsUtcDay_No_Actl 1;
BA_ "GenSigStartValueInteger" SG_ 1123 GpsUtcDay_No_Actl 1;
BA_ "CrossOver_InfoCAN" SG_ 1123 GpsUtcDay_No_Actl 1;
BA_ "CrossOver_InfoCAN" SG_ 1123 GPS_UTC_seconds 1;
BA_ "CrossOver_InfoCAN" SG_ 1123 GPS_UTC_minutes 1;
BA_ "CrossOver_InfoCAN" SG_ 1123 GPS_UTC_hours 1;
BA_ "CrossOver_InfoCAN" SG_ 1123 GPS_Pdop 1;
BA_ "CrossOver_InfoCAN" SG_ 1123 GPS_Compass_direction 1;
BA_ "CrossOver_InfoCAN" SG_ 1123 GPS_Actual_vs_Infer_pos 1;
BA_ "CrossOver_InfoCAN" SG_ 1123 Gps_B_Falt 1;
BA_ "CrossOver_InfoCAN" SG_ 1122 GpsHsphLongEast_D_Actl 1;
BA_ "CrossOver_InfoCAN" SG_ 1122 GpsHsphLattSth_D_Actl 1;
BA_ "CrossOver_InfoCAN" SG_ 1122 GPS_Longitude_Minutes 1;
BA_ "CrossOver_InfoCAN" SG_ 1122 GPS_Longitude_Min_dec 1;
BA_ "GenSigStartValueInteger" SG_ 1122 GPS_Longitude_Degrees 179;
BA_ "CrossOver_InfoCAN" SG_ 1122 GPS_Longitude_Degrees 1;
BA_ "CrossOver_InfoCAN" SG_ 1122 GPS_Latitude_Minutes 1;
BA_ "CrossOver_InfoCAN" SG_ 1122 GPS_Latitude_Min_dec 1;
BA_ "CrossOver_InfoCAN" SG_ 1122 GPS_Latitude_Degrees 1;
BA_ "GenSigStartValue" SG_ 1003 PersNoPos_D_Actl 4;
BA_ "GenSigStartValueInteger" SG_ 1003 PersNoPos_D_Actl 4;
BA_ "CrossOver_InfoCAN" SG_ 1003 PersNoPos_D_Actl 1;
BA_ "CrossOver_InfoCAN" SG_ 1003 PersSetupRestr_D_Actl 1;
BA_ "CrossOver_InfoCAN" SG_ 1003 PersSetupAccessCtrl 1;
BA_ "CrossOver_InfoCAN" SG_ 1003 PersSetup_No_Actl 1;
BA_ "GenSigStartValue" SG_ 1003 PersConflict_D_Actl 1;
BA_ "GenSigStartValueInteger" SG_ 1003 PersConflict_D_Actl 1;
BA_ "CrossOver_InfoCAN" SG_ 1003 PersConflict_D_Actl 1;
BA_ "CrossOver_InfoCAN" SG_ 1003 AssocConfirm_D_Actl 1;
BA_ "MetaData" SG_ 1003 RecallEvent_No_Cnt 1;
BA_ "CrossOver_InfoCAN" SG_ 1003 RecallEvent_No_Cnt 1;
BA_ "GenSigStartValue" SG_ 1003 PersNo_D_Actl 4;
BA_ "GenSigStartValueInteger" SG_ 1003 PersNo_D_Actl 4;
BA_ "CrossOver_InfoCAN" SG_ 1003 PersNo_D_Actl 1;
BA_ "CrossOver_InfoCAN" SG_ 994 PersStore_D_Rq 1;
BA_ "CrossOver_InfoCAN" SG_ 994 Pers4OptIn_B_Stats 1;
BA_ "WakeupSignal" SG_ 994 Pers4OptIn_B_Stats 1;
BA_ "CrossOver_InfoCAN" SG_ 994 Pers3OptIn_B_Stats 1;
BA_ "WakeupSignal" SG_ 994 Pers3OptIn_B_Stats 1;
BA_ "CrossOver_InfoCAN" SG_ 994 Pers2OptIn_B_Stats 1;
BA_ "WakeupSignal" SG_ 994 Pers2OptIn_B_Stats 1;
BA_ "CrossOver_InfoCAN" SG_ 994 Pers1OptIn_B_Stats 1;
BA_ "WakeupSignal" SG_ 994 Pers1OptIn_B_Stats 1;
BA_ "GenSigStartValue" SG_ 994 CtrStkPersIndex_D_Actl 4;
BA_ "GenSigStartValueInteger" SG_ 994 CtrStkPersIndex_D_Actl 4;
BA_ "CrossOver_InfoCAN" SG_ 994 CtrStkPersIndex_D_Actl 1;
BA_ "CrossOver_InfoCAN" SG_ 994 CtrStkFeatNoActl 1;
BA_ "CrossOver_InfoCAN" SG_ 994 CtrStkFeatConfigActl 1;
BA_ "CrossOver_InfoCAN" SG_ 994 CtrStkDsplyOp_D_Rq 1;
BA_ "CrossOver_InfoCAN" SG_ 778 PrkAidFront_D_RqDrv 1;
BA_ "CrossOver_InfoCAN" SG_ 778 Cta_D_Rq 1;
BA_ "GenSigStartValueInteger" SG_ 778 Cta_D_Rq 1;
BA_ "GenSigStartValue" SG_ 778 Cta_D_Rq 1;
BA_ "CrossOver_InfoCAN" SG_ 778 PrkAidRear_D_RqDrv 1;
BA_ "CrossOver_InfoCAN" SG_ 778 Sod_D_Rq 1;
BA_ "GenSigStartValueInteger" SG_ 778 Sod_D_Rq 2;
BA_ "GenSigStartValue" SG_ 778 Sod_D_Rq 2;
BA_ "WakeupSignal" SG_ 549 Power_Up_Chime_Modules 1;
BA_ "WakeupSignal" SG_ 551 Cntr_Plg_Mode_Cmd 1;
BA_ "GenSigStartValue" SG_ 551 Btt_L_Actl2 30;
BA_ "GenSigStartValueInteger" SG_ 551 Btt_L_Actl2 126;
BA_ "WakeupSignal" SG_ 551 Em_D_Stat 1;
BA_ "CrossOver_InfoCAN" SG_ 1010 CbdblActv_B_RqAdas 1;
BA_ "U_P702_MY2021_Rx" SG_ 1010 LightRng_L_Max 1;
BA_ "U_P702_MY2021_Rx" SG_ 1010 LightPathOffst_L_Actl 1;
BA_ "GenSigStartValueInteger" SG_ 1010 LightPathOffst_L_Actl 512;
BA_ "U_P702_MY2021_Rx" SG_ 1010 LightPath_An_Actl 1;
BA_ "GenSigStartValueInteger" SG_ 1010 LightPath_An_Actl 1000;
BA_ "U_P702_MY2021_Rx" SG_ 1010 LightCurv_NoRate_Actl 1;
BA_ "GenSigStartValueInteger" SG_ 1010 LightCurv_NoRate_Actl 4096;
BA_ "U_P702_MY2021_Rx" SG_ 1010 LightCurv_No_Actl 1;
BA_ "GenSigStartValueInteger" SG_ 1010 LightCurv_No_Actl 1000;
BA_ "GenSigStartValue" SG_ 1070 BattULo24_Te_Actl 127;
BA_ "GenSigStartValueInteger" SG_ 1070 BattULo24_Te_Actl 127;
BA_ "U_P702_MY2021_Rx" SG_ 1070 BattULo24State_D_Qlty 1;
BA_ "GenSigStartValue" SG_ 1070 BattULo24State_D_Qlty 1;
BA_ "U_P702_MY2021_Rx" SG_ 1070 BattULo24Soc_Pc_Actl 1;
BA_ "U_CX727_MY2021_Rx" SG_ 1070 BattULo24Soc_Pc_Actl 1;
BA_ "U_P702_MY2021_Rx" SG_ 1070 BattULo24_I_Actl 1;
BA_ "GenSigStartValue" SG_ 1070 BattULo24_I_Actl 8192;
BA_ "U_P702_MY2021_Rx" SG_ 1070 BattULo24_B_Falt 1;
BA_ "U_P702_MY2021_Rx" SG_ 1070 BattULo24_Ah_DeltaRide 1;
BA_ "GenSigStartValue" SG_ 1070 BattULo24_Ah_DeltaRide 12800;
BA_ "GenSigStartValueInteger" SG_ 1186 SelDrvMdeAwd2_D_Stat 31;
BA_ "GenSigStartValue" SG_ 1186 SelDrvMdeAwd2_D_Stat 31;
BA_ "U_CX727_MY2021_Rx" SG_ 1186 SelDrvMdeAwd2_D_Stat 1;
BA_ "U_P702_MY2021_Rx" SG_ 1186 SelDrvMdeAwd2_D_Stat 1;
BA_ "U_P702_MY2021_Tx" SG_ 1186 SelDrvMdeAwd2_D_Stat 1;
BA_ "U_P702_MY2021_Tx" SG_ 1186 RearDiffLckMsg_D_Rq 1;
BA_ "U_P702_MY2021_Rx" SG_ 1186 RearDiffLckLamp_D_Rq 1;
BA_ "U_P702_MY2021_Tx" SG_ 1186 RearDiffLckLamp_D_Rq 1;
BA_ "U_P702_MY2021_Rx" SG_ 1186 RearDiffLck_Tq_Actl 1;
BA_ "U_T6_MCA_MY2020_Rx" SG_ 1186 RearDiffLck_Tq_Actl 1;
BA_ "U_P702_MY2021_Tx" SG_ 1186 RearDiffLck_Tq_Actl 1;
BA_ "U_P702_MY2021_Rx" SG_ 1186 RearDiffFalt_D_Stat 1;
BA_ "U_P702_MY2021_Tx" SG_ 1186 RearDiffFalt_D_Stat 1;
BA_ "CrossOver_InfoCAN" SG_ 1186 LsdSrvcRqd_B_Rq 1;
BA_ "U_P702_MY2021_Tx" SG_ 1186 LsdSrvcRqd_B_Rq 1;
BA_ "U_P702_MY2021_Rx" SG_ 611 AwdSys_D_Stat 1;
BA_ "U_T6_MCA_MY2020_Rx" SG_ 611 AwdSys_D_Stat 1;
BA_ "U_P702_MY2021_Tx" SG_ 611 AwdSys_D_Stat 1;
BA_ "CrossOver_InfoCAN" SG_ 611 AwdStat_D_RqDsply 1;
BA_ "ContentDependant" SG_ 611 AwdStat_D_RqDsply 1;
BA_ "U_P702_MY2021_Rx" SG_ 611 AwdStat_D_RqDsply 1;
BA_ "U_T6_MCA_MY2020_Rx" SG_ 611 AwdStat_D_RqDsply 1;
BA_ "U_P702_MY2021_Tx" SG_ 611 AwdStat_D_RqDsply 1;
BA_ "CrossOver_InfoCAN" SG_ 611 AwdLck_D_Stat 1;
BA_ "U_P702_MY2021_Rx" SG_ 611 AwdLck_D_Stat 1;
BA_ "U_T6_MCA_MY2020_Rx" SG_ 611 AwdLck_D_Stat 1;
BA_ "U_P702_MY2021_Tx" SG_ 611 AwdLck_D_Stat 1;
BA_ "CrossOver_InfoCAN" SG_ 611 AwdSrvcRqd_B_Rq 1;
BA_ "ContentDependant" SG_ 611 AwdSrvcRqd_B_Rq 1;
BA_ "U_P702_MY2021_Rx" SG_ 611 AwdSrvcRqd_B_Rq 1;
BA_ "U_T6_MCA_MY2020_Rx" SG_ 611 AwdSrvcRqd_B_Rq 1;
BA_ "U_P702_MY2021_Tx" SG_ 611 AwdSrvcRqd_B_Rq 1;
BA_ "U_P702_MY2021_Tx" SG_ 611 NtrlTowAvail_B_Stat 1;
BA_ "CrossOver_InfoCAN" SG_ 611 AwdLck_Tq_Rq 1;
BA_ "ContentDependant" SG_ 611 AwdLck_Tq_Rq 1;
BA_ "U_P702_MY2021_Rx" SG_ 611 AwdLck_Tq_Rq 1;
BA_ "U_P702_MY2021_Tx" SG_ 611 AwdLck_Tq_Rq 1;
BA_ "CrossOver_InfoCAN" SG_ 611 TrnAout_Tq_RqMx 1;
BA_ "GenSigStartValueInteger" SG_ 611 TrnAout_Tq_RqMx 8191;
BA_ "GenSigStartValue" SG_ 611 TrnAout_Tq_RqMx 8191;
BA_ "U_P702_MY2021_Rx" SG_ 611 TrnAout_Tq_RqMx 1;
BA_ "U_T6_MCA_MY2020_Rx" SG_ 611 TrnAout_Tq_RqMx 1;
BA_ "U_P702_MY2021_Tx" SG_ 611 TrnAout_Tq_RqMx 1;
BA_ "CrossOver_InfoCAN" SG_ 611 AwdOffRoadMode_D_Stats 1;
BA_ "U_P702_MY2021_Tx" SG_ 611 AwdOffRoadMode_D_Stats 1;
BA_ "CrossOver_InfoCAN" SG_ 611 AwdLoLamp_D_RqDsply 1;
BA_ "U_P702_MY2021_Tx" SG_ 611 AwdLoLamp_D_RqDsply 1;
BA_ "CrossOver_InfoCAN" SG_ 611 AwdHiLamp_D_RqDsply 1;
BA_ "U_P702_MY2021_Rx" SG_ 611 AwdHiLamp_D_RqDsply 1;
BA_ "U_P702_MY2021_Tx" SG_ 611 AwdHiLamp_D_RqDsply 1;
BA_ "CrossOver_InfoCAN" SG_ 611 AwdAutoLamp_D_RqDsply 1;
BA_ "U_P702_MY2021_Rx" SG_ 611 AwdAutoLamp_D_RqDsply 1;
BA_ "U_P702_MY2021_Tx" SG_ 611 AwdAutoLamp_D_RqDsply 1;
BA_ "CrossOver_InfoCAN" SG_ 611 Awd2wdLamp_D_RqDsply 1;
BA_ "U_P702_MY2021_Tx" SG_ 611 Awd2wdLamp_D_RqDsply 1;
BA_ "CrossOver_InfoCAN" SG_ 611 AwdRnge_D_Actl 1;
BA_ "GenSigStartValueInteger" SG_ 611 AwdRnge_D_Actl 7;
BA_ "GenSigStartValue" SG_ 611 AwdRnge_D_Actl 7;
BA_ "U_P702_MY2021_Rx" SG_ 611 AwdRnge_D_Actl 1;
BA_ "U_T6_MCA_MY2020_Rx" SG_ 611 AwdRnge_D_Actl 1;
BA_ "U_P702_MY2021_Tx" SG_ 611 AwdRnge_D_Actl 1;
BA_ "ECGUsedRxSignal" SG_ 611 AwdRnge_D_Actl 1;
BA_ "GenSigStartValueInteger" SG_ 1461 PSCM_GWOnBoardTester 255;
BA_ "ContentDependant" SG_ 1461 PSCM_GWOnBoardTester 1;
BA_ "GenSigStartValue" SG_ 1461 PSCM_GWOnBoardTester 255;
BA_ "U_P702_MY2021_Rx" SG_ 1461 PSCM_GWOnBoardTester 1;
BA_ "U_CX727_MY2021_Tx" SG_ 1461 PSCM_GWOnBoardTester 1;
BA_ "U_P702_MY2021_Tx" SG_ 1461 PSCM_GWOnBoardTester 1;
BA_ "GenSigStartValueInteger" SG_ 1461 PSCM_GWNMProxy 255;
BA_ "ContentDependant" SG_ 1461 PSCM_GWNMProxy 1;
BA_ "GenSigStartValue" SG_ 1461 PSCM_GWNMProxy 255;
BA_ "U_P702_MY2021_Rx" SG_ 1461 PSCM_GWNMProxy 1;
BA_ "U_CX727_MY2021_Tx" SG_ 1461 PSCM_GWNMProxy 1;
BA_ "U_P702_MY2021_Tx" SG_ 1461 PSCM_GWNMProxy 1;
BA_ "GenSigStartValueInteger" SG_ 1461 PSCM_AutoSarNMReserved4 255;
BA_ "ContentDependant" SG_ 1461 PSCM_AutoSarNMReserved4 1;
BA_ "GenSigStartValue" SG_ 1461 PSCM_AutoSarNMReserved4 255;
BA_ "U_P702_MY2021_Rx" SG_ 1461 PSCM_AutoSarNMReserved4 1;
BA_ "U_CX727_MY2021_Tx" SG_ 1461 PSCM_AutoSarNMReserved4 1;
BA_ "U_P702_MY2021_Tx" SG_ 1461 PSCM_AutoSarNMReserved4 1;
BA_ "GenSigStartValueInteger" SG_ 1461 PSCM_AutoSarNMReserved3 255;
BA_ "ContentDependant" SG_ 1461 PSCM_AutoSarNMReserved3 1;
BA_ "GenSigStartValue" SG_ 1461 PSCM_AutoSarNMReserved3 255;
BA_ "U_P702_MY2021_Rx" SG_ 1461 PSCM_AutoSarNMReserved3 1;
BA_ "U_CX727_MY2021_Tx" SG_ 1461 PSCM_AutoSarNMReserved3 1;
BA_ "U_P702_MY2021_Tx" SG_ 1461 PSCM_AutoSarNMReserved3 1;
BA_ "GenSigStartValueInteger" SG_ 1461 PSCM_AutoSarNMReserved2 255;
BA_ "ContentDependant" SG_ 1461 PSCM_AutoSarNMReserved2 1;
BA_ "GenSigStartValue" SG_ 1461 PSCM_AutoSarNMReserved2 255;
BA_ "U_CX727_MY2021_Tx" SG_ 1461 PSCM_AutoSarNMReserved2 1;
BA_ "U_P702_MY2021_Tx" SG_ 1461 PSCM_AutoSarNMReserved2 1;
BA_ "GenSigStartValueInteger" SG_ 1461 PSCM_AutoSarNMReserved1 255;
BA_ "ContentDependant" SG_ 1461 PSCM_AutoSarNMReserved1 1;
BA_ "GenSigStartValue" SG_ 1461 PSCM_AutoSarNMReserved1 255;
BA_ "U_CX727_MY2021_Tx" SG_ 1461 PSCM_AutoSarNMReserved1 1;
BA_ "U_P702_MY2021_Tx" SG_ 1461 PSCM_AutoSarNMReserved1 1;
BA_ "GenSigStartValueInteger" SG_ 1461 PSCM_AutoSarNMNodeId 181;
BA_ "ContentDependant" SG_ 1461 PSCM_AutoSarNMNodeId 1;
BA_ "GenSigStartValue" SG_ 1461 PSCM_AutoSarNMNodeId 181;
BA_ "U_CX727_MY2021_Tx" SG_ 1461 PSCM_AutoSarNMNodeId 1;
BA_ "U_P702_MY2021_Tx" SG_ 1461 PSCM_AutoSarNMNodeId 1;
BA_ "ContentDependant" SG_ 1461 PSCM_AutoSarNMControl 1;
BA_ "U_CX727_MY2021_Tx" SG_ 1461 PSCM_AutoSarNMControl 1;
BA_ "U_P702_MY2021_Tx" SG_ 1461 PSCM_AutoSarNMControl 1;
BA_ "GenSigStartValueInteger" SG_ 1047 TrlrAnOffst_An2_Calc 128;
BA_ "U_P702_MY2021_Tx" SG_ 1047 TrlrAnOffst_An2_Calc 1;
BA_ "U_P702_MY2021_Tx" SG_ 1047 TrlrAn_An_WarnCalc 1;
BA_ "U_P702_MY2021_Tx" SG_ 1047 TrlrAn_An_MxCalc 1;
BA_ "U_P702_MY2021_Tx" SG_ 1047 TrlrAidTrlrId_No_Rq 1;
BA_ "U_P702_MY2021_Tx" SG_ 1047 TrlrAidTrgtId_No_Rq 1;
BA_ "U_P702_MY2021_Tx" SG_ 1047 TrlrAidSetup_D2_Stat 1;
BA_ "GenSigSendType" SG_ 1047 TrlrAidEnbl_D2_Stat 3;
BA_ "U_P702_MY2021_Rx" SG_ 1047 TrlrAidEnbl_D2_Stat 1;
BA_ "U_T6_MCA_MY2020_Rx" SG_ 1047 TrlrAidEnbl_D2_Stat 1;
BA_ "U_P702_MY2021_Tx" SG_ 1047 TrlrAidEnbl_D2_Stat 1;
BA_ "GenSigSendType" SG_ 1047 TrlrAidMsgTxt_D2_Rq 3;
BA_ "U_P702_MY2021_Rx" SG_ 1047 TrlrAidMsgTxt_D2_Rq 1;
BA_ "U_P702_MY2021_Tx" SG_ 1047 TrlrAidMsgTxt_D2_Rq 1;
BA_ "GenSigStartValueInteger" SG_ 1047 EsaOn_B_Stat 1;
BA_ "GenSigStartValue" SG_ 1047 EsaOn_B_Stat 1;
BA_ "GenSigSendType" SG_ 1047 EsaOn_B_Stat 3;
BA_ "U_CX727_MY2021_Tx" SG_ 1047 EsaOn_B_Stat 1;
BA_ "U_P702_MY2021_Tx" SG_ 1047 EsaOn_B_Stat 1;
BA_ "U_P702_MY2021_Tx" SG_ 1047 HitchToTrlrAxle_L_Calc 1;
BA_ "GenSigSendType" SG_ 1047 SelDrvMdeSte_D_Stat 3;
BA_ "U_CX727_MY2021_Rx" SG_ 1047 SelDrvMdeSte_D_Stat 1;
BA_ "U_P702_MY2021_Rx" SG_ 1047 SelDrvMdeSte_D_Stat 1;
BA_ "U_CX727_MY2021_Tx" SG_ 1047 SelDrvMdeSte_D_Stat 1;
BA_ "U_P702_MY2021_Tx" SG_ 1047 SelDrvMdeSte_D_Stat 1;
BA_ "GenSigSendType" SG_ 972 LatCtlSte_D_Stat 3;
BA_ "U_CX727_MY2021_Tx" SG_ 972 LatCtlSte_D_Stat 1;
BA_ "U_P702_MY2021_Tx" SG_ 972 LatCtlSte_D_Stat 1;
BA_ "GenSigSendType" SG_ 972 LatCtlLim_D_Stat 3;
BA_ "U_CX727_MY2021_Tx" SG_ 972 LatCtlLim_D_Stat 1;
BA_ "U_P702_MY2021_Tx" SG_ 972 LatCtlLim_D_Stat 1;
BA_ "MetaData" SG_ 972 LatCtlCpbltyDStat_No_Cnt 1;
BA_ "MetaData" SG_ 972 LatCtlCpbltyDStat_No_Cs 1;
BA_ "GenSigStartValueInteger" SG_ 972 TrlrAn_An_TrgtCalc 128;
BA_ "U_P702_MY2021_Tx" SG_ 972 TrlrAn_An_TrgtCalc 1;
BA_ "U_P702_MY2021_Rx" SG_ 972 LsmcBrkDecelEnbl_D_Rq 1;
BA_ "U_P702_MY2021_Tx" SG_ 972 LsmcBrkDecelEnbl_D_Rq 1;
BA_ "GenSigStartValueInteger" SG_ 972 TjaHandsOnCnfdnc_B_Est 1;
BA_ "GenSigStartValue" SG_ 972 TjaHandsOnCnfdnc_B_Est 1;
BA_ "U_CX727_MY2021_Tx" SG_ 972 TjaHandsOnCnfdnc_B_Est 1;
BA_ "U_P702_MY2021_Tx" SG_ 972 TjaHandsOnCnfdnc_B_Est 1;
BA_ "CrossOver_InfoCAN" SG_ 972 LaHandsOff_B_Actl 1;
BA_ "GenSigStartValueInteger" SG_ 972 LaHandsOff_B_Actl 1;
BA_ "GenSigStartValue" SG_ 972 LaHandsOff_B_Actl 1;
BA_ "U_CX727_MY2021_Tx" SG_ 972 LaHandsOff_B_Actl 1;
BA_ "U_P702_MY2021_Tx" SG_ 972 LaHandsOff_B_Actl 1;
BA_ "CrossOver_InfoCAN" SG_ 972 LaActDeny_B_Actl 1;
BA_ "U_CX727_MY2021_Tx" SG_ 972 LaActDeny_B_Actl 1;
BA_ "U_P702_MY2021_Tx" SG_ 972 LaActDeny_B_Actl 1;
BA_ "CrossOver_InfoCAN" SG_ 972 LaActAvail_D_Actl 1;
BA_ "U_CX727_MY2021_Tx" SG_ 972 LaActAvail_D_Actl 1;
BA_ "U_P702_MY2021_Tx" SG_ 972 LaActAvail_D_Actl 1;
BA_ "U_P702_MY2021_Rx" SG_ 972 LsmcBrk_Tq_Rq 1;
BA_ "U_P702_MY2021_Tx" SG_ 972 LsmcBrk_Tq_Rq 1;
BA_ "CrossOver_InfoCAN" SG_ 130 TrlrHitchLamp_D_Rqst 1;
BA_ "U_P702_MY2021_Tx" SG_ 130 TrlrHitchLamp_D_Rqst 1;
BA_ "CrossOver_InfoCAN" SG_ 130 VehVTrlrAid_B_Rq 1;
BA_ "U_P702_MY2021_Rx" SG_ 130 VehVTrlrAid_B_Rq 1;
BA_ "U_T6_MCA_MY2020_Rx" SG_ 130 VehVTrlrAid_B_Rq 1;
BA_ "U_P702_MY2021_Tx" SG_ 130 VehVTrlrAid_B_Rq 1;
BA_ "GenSigStartValueInteger" SG_ 130 Veh_V_RqMxTrlrAid 255;
BA_ "GenSigStartValue" SG_ 130 Veh_V_RqMxTrlrAid 255;
BA_ "U_P702_MY2021_Rx" SG_ 130 Veh_V_RqMxTrlrAid 1;
BA_ "U_T6_MCA_MY2020_Rx" SG_ 130 Veh_V_RqMxTrlrAid 1;
BA_ "U_P702_MY2021_Tx" SG_ 130 Veh_V_RqMxTrlrAid 1;
BA_ "U_P702_MY2021_Rx" SG_ 130 DrvSteActv_B_Stat 1;
BA_ "U_P702_MY2021_Tx" SG_ 130 DrvSteActv_B_Stat 1;
BA_ "GenSigStartValueInteger" SG_ 130 DrvSte_Tq_Actl 128;
BA_ "U_P702_MY2021_Rx" SG_ 130 DrvSte_Tq_Actl 1;
BA_ "U_P702_MY2021_Tx" SG_ 130 DrvSte_Tq_Actl 1;
BA_ "U_CX727_MY2021_Tx" SG_ 130 SteMdule_D_Stat 1;
BA_ "U_P702_MY2021_Tx" SG_ 130 SteMdule_D_Stat 1;
BA_ "GenSigStartValueInteger" SG_ 130 SteMdule_U_Meas 255;
BA_ "GenSigStartValue" SG_ 130 SteMdule_U_Meas 255;
BA_ "U_CX727_MY2021_Tx" SG_ 130 SteMdule_U_Meas 1;
BA_ "U_P702_MY2021_Tx" SG_ 130 SteMdule_U_Meas 1;
BA_ "GenSigStartValueInteger" SG_ 130 SteMdule_I_Est 4095;
BA_ "GenSigStartValue" SG_ 130 SteMdule_I_Est 4095;
BA_ "U_CX727_MY2021_Tx" SG_ 130 SteMdule_I_Est 1;
BA_ "U_P702_MY2021_Tx" SG_ 130 SteMdule_I_Est 1;
BA_ "CrossOver_InfoCAN" SG_ 130 EPAS_Failure 1;
BA_ "U_CX727_MY2021_Tx" SG_ 130 EPAS_Failure 1;
BA_ "U_P702_MY2021_Tx" SG_ 130 EPAS_Failure 1;
BA_ "GenSigStartValueInteger" SG_ 130 SteeringColumnTorque 254;
BA_ "GenSigStartValue" SG_ 130 SteeringColumnTorque 254;
BA_ "U_CX727_MY2021_Rx" SG_ 130 SteeringColumnTorque 1;
BA_ "U_P702_MY2021_Rx" SG_ 130 SteeringColumnTorque 1;
BA_ "U_CX727_MY2021_Tx" SG_ 130 SteeringColumnTorque 1;
BA_ "U_P702_MY2021_Tx" SG_ 130 SteeringColumnTorque 1;
BA_ "U_CX727_MY2021_Tx" SG_ 130 SAPPAngleControlStat6 1;
BA_ "U_P702_MY2021_Tx" SG_ 130 SAPPAngleControlStat6 1;
BA_ "U_CX727_MY2021_Tx" SG_ 130 SAPPAngleControlStat5 1;
BA_ "U_P702_MY2021_Tx" SG_ 130 SAPPAngleControlStat5 1;
BA_ "U_CX727_MY2021_Tx" SG_ 130 SAPPAngleControlStat4 1;
BA_ "U_P702_MY2021_Tx" SG_ 130 SAPPAngleControlStat4 1;
BA_ "U_CX727_MY2021_Tx" SG_ 130 SAPPAngleControlStat3 1;
BA_ "U_P702_MY2021_Tx" SG_ 130 SAPPAngleControlStat3 1;
BA_ "U_CX727_MY2021_Tx" SG_ 130 SAPPAngleControlStat2 1;
BA_ "U_P702_MY2021_Tx" SG_ 130 SAPPAngleControlStat2 1;
BA_ "U_CX727_MY2021_Tx" SG_ 130 SAPPAngleControlStat1 1;
BA_ "U_P702_MY2021_Tx" SG_ 130 SAPPAngleControlStat1 1;
BA_ "U_P702_MY2021_Rx" SG_ 126 StePw_B_Rq 1;
BA_ "U_T6_MCA_MY2020_Rx" SG_ 126 StePw_B_Rq 1;
BA_ "U_P702_MY2021_Tx" SG_ 126 StePw_B_Rq 1;
BA_ "GenSigStartValueInteger" SG_ 126 StePinRelInit_An_Sns 65535;
BA_ "ContentDependant" SG_ 126 StePinRelInit_An_Sns 1;
BA_ "GenSigStartValue" SG_ 126 StePinRelInit_An_Sns 65535;
BA_ "U_P702_MY2021_Rx" SG_ 126 StePinRelInit_An_Sns 1;
BA_ "U_CX727_MY2021_Rx" SG_ 126 StePinRelInit_An_Sns 1;
BA_ "U_T6_MCA_MY2020_Rx" SG_ 126 StePinRelInit_An_Sns 1;
BA_ "U_CX727_MY2021_Tx" SG_ 126 StePinRelInit_An_Sns 1;
BA_ "U_P702_MY2021_Tx" SG_ 126 StePinRelInit_An_Sns 1;
BA_ "CrossOver_InfoCAN" SG_ 126 StePinCompAnEst_D_Qf 1;
BA_ "GenSigStartValueInteger" SG_ 126 StePinCompAnEst_D_Qf 1;
BA_ "GenSigStartValue" SG_ 126 StePinCompAnEst_D_Qf 1;
BA_ "U_P702_MY2021_Rx" SG_ 126 StePinCompAnEst_D_Qf 1;
BA_ "U_CX727_MY2021_Rx" SG_ 126 StePinCompAnEst_D_Qf 1;
BA_ "U_T6_MCA_MY2020_Rx" SG_ 126 StePinCompAnEst_D_Qf 1;
BA_ "U_CX727_MY2021_Tx" SG_ 126 StePinCompAnEst_D_Qf 1;
BA_ "U_P702_MY2021_Tx" SG_ 126 StePinCompAnEst_D_Qf 1;
BA_ "ECGUsedRxSignal" SG_ 126 StePinCompAnEst_D_Qf 1;
BA_ "GenSigStartValueInteger" SG_ 126 StePinComp_An_Est 16000;
BA_ "U_P702_MY2021_Rx" SG_ 126 StePinComp_An_Est 1;
BA_ "U_CX727_MY2021_Rx" SG_ 126 StePinComp_An_Est 1;
BA_ "U_T6_MCA_MY2020_Rx" SG_ 126 StePinComp_An_Est 1;
BA_ "U_CX727_MY2021_Tx" SG_ 126 StePinComp_An_Est 1;
BA_ "U_P702_MY2021_Tx" SG_ 126 StePinComp_An_Est 1;
BA_ "ECGUsedRxSignal" SG_ 126 StePinComp_An_Est 1;
BA_ "ContentDependant" SG_ 126 StePinAn_No_Cs 1;
BA_ "MetaData" SG_ 126 StePinAn_No_Cs 1;
BA_ "U_P702_MY2021_Rx" SG_ 126 StePinAn_No_Cs 1;
BA_ "U_CX727_MY2021_Rx" SG_ 126 StePinAn_No_Cs 1;
BA_ "U_CX727_MY2021_Tx" SG_ 126 StePinAn_No_Cs 1;
BA_ "U_P702_MY2021_Tx" SG_ 126 StePinAn_No_Cs 1;
BA_ "CrossOver_InfoCAN" SG_ 126 StePinAn_No_Cnt 1;
BA_ "MetaData" SG_ 126 StePinAn_No_Cnt 1;
BA_ "U_P702_MY2021_Rx" SG_ 126 StePinAn_No_Cnt 1;
BA_ "U_CX727_MY2021_Rx" SG_ 126 StePinAn_No_Cnt 1;
BA_ "U_CX727_MY2021_Tx" SG_ 126 StePinAn_No_Cnt 1;
BA_ "U_P702_MY2021_Tx" SG_ 126 StePinAn_No_Cnt 1;
BA_ "GenSigStartValueInteger" SG_ 1430 ABS_GWOnBoardTester 255;
BA_ "ContentDependant" SG_ 1430 ABS_GWOnBoardTester 1;
BA_ "GenSigStartValue" SG_ 1430 ABS_GWOnBoardTester 255;
BA_ "U_CX727_MY2021_Tx" SG_ 1430 ABS_GWOnBoardTester 1;
BA_ "U_P702_MY2021_Tx" SG_ 1430 ABS_GWOnBoardTester 1;
BA_ "GenSigStartValueInteger" SG_ 1430 ABS_GWNMProxy 255;
BA_ "ContentDependant" SG_ 1430 ABS_GWNMProxy 1;
BA_ "GenSigStartValue" SG_ 1430 ABS_GWNMProxy 255;
BA_ "U_CX727_MY2021_Tx" SG_ 1430 ABS_GWNMProxy 1;
BA_ "U_P702_MY2021_Tx" SG_ 1430 ABS_GWNMProxy 1;
BA_ "GenSigStartValueInteger" SG_ 1430 ABS_AutoSarNMReserved4 255;
BA_ "ContentDependant" SG_ 1430 ABS_AutoSarNMReserved4 1;
BA_ "GenSigStartValue" SG_ 1430 ABS_AutoSarNMReserved4 255;
BA_ "U_CX727_MY2021_Tx" SG_ 1430 ABS_AutoSarNMReserved4 1;
BA_ "U_P702_MY2021_Tx" SG_ 1430 ABS_AutoSarNMReserved4 1;
BA_ "GenSigStartValueInteger" SG_ 1430 ABS_AutoSarNMReserved3 255;
BA_ "ContentDependant" SG_ 1430 ABS_AutoSarNMReserved3 1;
BA_ "GenSigStartValue" SG_ 1430 ABS_AutoSarNMReserved3 255;
BA_ "U_CX727_MY2021_Tx" SG_ 1430 ABS_AutoSarNMReserved3 1;
BA_ "U_P702_MY2021_Tx" SG_ 1430 ABS_AutoSarNMReserved3 1;
BA_ "GenSigStartValueInteger" SG_ 1430 ABS_AutoSarNMReserved2 255;
BA_ "ContentDependant" SG_ 1430 ABS_AutoSarNMReserved2 1;
BA_ "GenSigStartValue" SG_ 1430 ABS_AutoSarNMReserved2 255;
BA_ "U_CX727_MY2021_Tx" SG_ 1430 ABS_AutoSarNMReserved2 1;
BA_ "U_P702_MY2021_Tx" SG_ 1430 ABS_AutoSarNMReserved2 1;
BA_ "GenSigStartValueInteger" SG_ 1430 ABS_AutoSarNMReserved1 255;
BA_ "ContentDependant" SG_ 1430 ABS_AutoSarNMReserved1 1;
BA_ "GenSigStartValue" SG_ 1430 ABS_AutoSarNMReserved1 255;
BA_ "U_CX727_MY2021_Tx" SG_ 1430 ABS_AutoSarNMReserved1 1;
BA_ "U_P702_MY2021_Tx" SG_ 1430 ABS_AutoSarNMReserved1 1;
BA_ "GenSigStartValueInteger" SG_ 1430 ABS_AutoSarNMNodeId 150;
BA_ "ContentDependant" SG_ 1430 ABS_AutoSarNMNodeId 1;
BA_ "GenSigStartValue" SG_ 1430 ABS_AutoSarNMNodeId 150;
BA_ "U_CX727_MY2021_Tx" SG_ 1430 ABS_AutoSarNMNodeId 1;
BA_ "U_P702_MY2021_Tx" SG_ 1430 ABS_AutoSarNMNodeId 1;
BA_ "ContentDependant" SG_ 1430 ABS_AutoSarNMControl 1;
BA_ "U_CX727_MY2021_Tx" SG_ 1430 ABS_AutoSarNMControl 1;
BA_ "U_P702_MY2021_Tx" SG_ 1430 ABS_AutoSarNMControl 1;
VAL_ 984 PersIndexIpma_D_Actl 7 "Unused_3" 6 "Unused_2" 5 "Unused_1" 4 "Vehicle" 3 "PERS_4" 2 "PERS_3" 1 "PERS_2" 0 "PERS_1";
VAL_ 984 AhbcRampingV_D_Rq 3 "Slow" 2 "Medium" 1 "Fast" 0 "Immediately";
VAL_ 984 LaActvStats_D_Dsply 31 "Unused7" 30 "LA_Off" 29 "Unused5" 28 "Unused4" 27 "Unused3" 26 "Unused2" 25 "Unused1" 24 "InerveneLeft_InterveneRght" 23 "WarnLeft_InterveneRight" 22 "SuppressLeft_InterveneRght" 21 "AvailLeft_InterveneRhtt" 20 "NoLeft_InterveneRight" 19 "InterveneLeft_WarnRight" 18 "WarnLeft_WarnRight" 17 "SuppressLeft_WarnRight" 16 "AvailableLeft_WarnRight" 15 "NoLeft_WarnRight" 14 "InterveneLeft_SuppressRght" 13 "WarnLeft_SuppressRight" 12 "SuppressLeft_SuppressRight" 11 "AvailLeft_SuppressRight" 10 "NoLeft_SuppressRight" 9 "InterveneLeft_AvailRight" 8 "WarnLeft_AvailRight" 7 "SuppressLeft_AvailRight" 6 "AvailableLeft_AvailRight" 5 "NoLeft_AvailableRight" 4 "InterveneLeft_NoRight" 3 "WarnLeft_NoRight" 2 "SuppressLeft_NoRight" 1 "AvailableLeft_NoRight" 0 "NoLeft_NoRight";
VAL_ 984 LaDenyStats_B_Dsply 1 "Unavailable" 0 "Available";
VAL_ 984 LaHandsOff_D_Dsply 3 "Suppressed" 2 "Level2" 1 "Level1" 0 "HandsOn";
VAL_ 984 CamraDefog_B_Req 1 "On" 0 "Off";
VAL_ 984 CamraStats_D_Dsply 3 "FrtCam_TempUnavailOther" 2 "FrtCam_TempUnavailVisibile" 1 "Front_Camera_Service_Reqd" 0 "Front_Camera_OK";
VAL_ 984 DasAlrtLvl_D_Dsply 5 "Alertness_Level_5" 4 "Alertness_Level_4" 3 "Alertness_Level_3" 2 "Alertness_Level_2" 1 "Alertness_Level_1" 0 "Undefined";
VAL_ 984 DasStats_D_Dsply 3 "Available" 2 "Unavailable_Other" 1 "Feedback_due_to_Speed" 0 "Off";
VAL_ 984 DasWarn_D_Dsply 3 "Undefined" 2 "Warning_Level_2" 1 "Warning_Level_1" 0 "No_Warning";
VAL_ 984 AhbHiBeam_D_Rq 3 "NotUsed" 2 "HighBeamRecommended" 1 "LowBeamRecommended" 0 "DeactivatedUnavailable";
VAL_ 985 LdwChime_B_Rq 1 "On" 0 "Off";
VAL_ 985 TsrRegionTxt_D_Stat 31 "Faulty" 30 "NotUsed_8" 29 "NotUsed_7" 28 "NotUsed_6" 27 "NotUsed_5" 26 "NotUsed_4" 25 "NotUsed_3" 24 "NotUsed_2" 23 "NotUsed_1" 22 "Region_22" 21 "Region_21" 20 "Region_20" 19 "Region_19" 18 "Region_18" 17 "Region_17" 16 "Region_16" 15 "Region_15" 14 "Region_14" 13 "Region_13" 12 "Region_12" 11 "Region_11" 10 "Region_10" 9 "Region_09" 8 "Region_08" 7 "Region_07" 6 "Region_06" 5 "Region_05" 4 "Region_04" 3 "Region_03" 2 "Region_02" 1 "Region_01" 0 "NotDetermined";
VAL_ 985 SblmPedCrossScnr_B_Stat 1 "Yes" 0 "No";
VAL_ 985 LongCtrlEnbl_D_Rq 7 "NotUsed_4" 6 "NotUsed_3" 5 "NotUsed_2" 4 "NotUsed_1" 3 "RemoteParking" 2 "Autohitch" 1 "AutomaticParking" 0 "None";
VAL_ 985 SblmRndAbtScnr_B_Stat 1 "Yes" 0 "No";
VAL_ 985 DasAlrtInfo_D_Dsply 3 "NotUsed" 2 "On" 1 "Off" 0 "Null";
VAL_ 985 IaccVLim_D_Rq 252 "NotUsed_2" 250 "LimitSpeed_250" 240 "LimitSpeed_240" 230 "LimitSpeed_230" 220 "LimitSpeed_220" 210 "LimitSpeed_210" 200 "LimitSpeed_200" 190 "LimitSpeed_190" 150 "LimitSpeed_150" 140 "LimitSpeed_140" 130 "LimitSpeed_130" 120 "LimitSpeed_120" 110 "LimitSpeed_110" 100 "LimitSpeed_100" 90 "LimitSpeed_90" 80 "LimitSpeed_80" 70 "LimitSpeed_70" 60 "LimitSpeed_60" 50 "LimitSpeed_50" 40 "LimitSpeed_40" 30 "LimitSpeed_30" 20 "LimtSpeed_20" 251 "NotUsed_1" 255 "Faulty" 254 "NoDataExists" 253 "NotUsed_3" 180 "LimitSpeed_180" 179 "LimitSpeed_179" 178 "LimitSpeed_178" 177 "LimitSpeed_177" 176 "LimitSpeed_176" 175 "LimitSpeed_175" 174 "LimitSpeed_174" 173 "LimitSpeed_173" 172 "LimitSpeed_172" 171 "LimitSpeed_171" 170 "LimitSpeed_170" 169 "LimitSpeed_169" 168 "LimitSpeed_168" 167 "LimitSpeed_167" 166 "LimitSpeed_166" 165 "LimitSpeed_165" 164 "LimitSpeed_164" 163 "LimitSpeed_163" 162 "LimitSpeed_162" 161 "LimitSpeed_161" 160 "LimitSpeed_160" 15 "LimitSpeed_15" 14 "LimitSpeed_14" 13 "LimitSpeed_13" 12 "LimitSpeed_12" 11 "LimitSpeed_11" 10 "LimitSpeed_10" 9 "LimitSpeed_9" 8 "LimitSpeed_8" 7 "LimitSpeed_7" 6 "LimitSpeed_6" 5 "LimitSpeed_5" 4 "LimitSpeed_4" 3 "LimitSpeed_3" 2 "LimitSpeed_2" 1 "LimitSpeed_1" 0 "LimitSpeed_0";
VAL_ 985 IaccVLimUnit_D_Rq 3 "NoDataExists" 2 "Mph" 1 "Kph" 0 "Null";
VAL_ 985 IsaVLim_D_Rq 252 "NotUsed_2" 250 "LimitSpeed_250" 240 "LimitSpeed_240" 230 "LimitSpeed_230" 220 "LimitSpeed_220" 210 "LimitSpeed_210" 200 "LimitSpeed_200" 190 "LimitSpeed_190" 150 "LimitSpeed_150" 140 "LimitSpeed_140" 130 "LimitSpeed_130" 120 "LimitSpeed_120" 110 "LimitSpeed_110" 100 "LimitSpeed_100" 90 "LimitSpeed_90" 80 "LimitSpeed_80" 70 "LimitSpeed_70" 60 "LimitSpeed_60" 50 "LimitSpeed_50" 40 "LimitSpeed_40" 30 "LimitSpeed_30" 20 "LimtSpeed_20" 251 "NotUsed_1" 255 "Faulty" 254 "NoDataExists" 253 "NotUsed_3" 180 "LimitSpeed_180" 179 "LimitSpeed_179" 178 "LimitSpeed_178" 177 "LimitSpeed_177" 176 "LimitSpeed_176" 175 "LimitSpeed_175" 174 "LimitSpeed_174" 173 "LimitSpeed_173" 172 "LimitSpeed_172" 171 "LimitSpeed_171" 170 "LimitSpeed_170" 169 "LimitSpeed_169" 168 "LimitSpeed_168" 167 "LimitSpeed_167" 166 "LimitSpeed_166" 165 "LimitSpeed_165" 164 "LimitSpeed_164" 163 "LimitSpeed_163" 162 "LimitSpeed_162" 161 "LimitSpeed_161" 160 "LimitSpeed_160" 15 "LimitSpeed_15" 14 "LimitSpeed_14" 13 "LimitSpeed_13" 12 "LimitSpeed_12" 11 "LimitSpeed_11" 10 "LimitSpeed_10" 9 "LimitSpeed_9" 8 "LimitSpeed_8" 7 "LimitSpeed_7" 6 "LimitSpeed_6" 5 "LimitSpeed_5" 4 "LimitSpeed_4" 3 "LimitSpeed_3" 2 "LimitSpeed_2" 1 "LimitSpeed_1" 0 "LimitSpeed_0";
VAL_ 985 SblmStopScnr_B_Stat 1 "Yes" 0 "No";
VAL_ 985 SblmYieldScnr_B_Stat 1 "Yes" 0 "No";
VAL_ 985 IsaVLimUnit_D_Rq 3 "NoDataExists" 2 "Mph" 1 "Kph" 0 "Null";
VAL_ 985 AdbDividedRoad_B_Stat 1 "Yes" 0 "No";
VAL_ 985 LcwaMsgTxt_D_Stat 3 "SodXFaulty" 2 "SodXBlocked" 1 "TrailerConnected" 0 "NoMessage";
VAL_ 985 AdbDrvSide_B_Stat 1 "Left_Hand_Traffic" 0 "Right_Hand_Traffic";
VAL_ 992 MsgCntrDsplyOp_D_Rq 7 "Unused_2" 6 "Unused_1" 5 "Copy" 4 "Restore" 3 "Upload" 2 "Set" 1 "Query" 0 "Null";
VAL_ 992 MsgCntrPersIndex_D_Rq 7 "Unused_3" 6 "Unused_2" 5 "Unused_1" 4 "Vehicle" 3 "PERS_4" 2 "PERS_3" 1 "PERS_2" 0 "PERS_1";
VAL_ 943 VehVActlAdas_D_Qf 3 "OK" 2 "Not_Within_Specifications" 1 "No_Data_Exists" 0 "Faulty";
VAL_ 943 AdasLcDistToObj_L_Actl 4095 "Faulty" 4094 "NoDataExists";
VAL_ 515 PtIgnSwtch_D_Stat 3 "Faulty" 2 "No_Data_Exists" 1 "On" 0 "Off";
VAL_ 1111 TrlrYawWActl_D_Qf 3 "OK" 2 "Not_Within_Specifications" 1 "No_Data_Exists" 0 "Faulty";
VAL_ 1111 TrlrYaw_W_Actl 65535 "Faulty" 65534 "NoDataExists";
VAL_ 1111 TrlrHitYaw_AnRate_Actl 4095 "Fault" 4094 "NoDataExists";
VAL_ 1111 TrlrHitchYaw_D_Stat 15 "Faulty" 14 "NotUsed_4" 13 "NotUsed_3" 12 "NotUsed_2" 11 "NotUsed_1" 10 "FaultyYrsuConnection" 9 "FaultyYrsu" 8 "HiConfdLrndAngle" 7 "LowConfdLrndAngle" 6 "HiConfdAngleMem" 5 "LowConfdAngleMem" 4 "InitNoTadAngle" 3 "InitInputs" 2 "TadTrlrDataOutOfRange" 1 "TadNotWithinSpecification" 0 "NoConnectionWithYrsu";
VAL_ 1111 TrlrHitchYaw_An_Actl 4095 "Faulty" 4094 "NoDataExists";
VAL_ 1106 TrlrSnsId_No_Actl -1 "Faulty_FFFFFFFFFFFF" -2 "NoDataExists_FFFFFFFFFFFE";
VAL_ 1104 DrvEngageLevel_D_Stat 7 "Faulty" 6 "NotUsed_2" 5 "NotUsed_1" 4 "Disengaged" 3 "Distracted" 2 "Attentive" 1 "Invalid" 0 "NotDetermined";
VAL_ 1104 DrvImpLvlConfid_D_Stat 7 "Faulty" 6 "NotUsed" 5 "High" 4 "MediumHigh" 3 "Medium" 2 "LowMedium" 1 "Low" 0 "NotDetermined";
VAL_ 1104 DrvImpairLvl_D_Stat 15 "Faulty" 14 "NotUsed_5" 13 "NotUsed_4" 12 "NotUsed_3" 11 "NotUsed_2" 10 "NotUsed_1" 9 "Incapacitated" 8 "Asleep" 7 "Microsleep" 6 "MostDrowsy" 5 "Drowsy_4" 4 "Drowsy_3" 3 "Drowsy_2" 2 "LeastDrowsy" 1 "Alert" 0 "NotDetermined";
VAL_ 1104 DrvEngLvlConfid_D_Stat 7 "Faulty" 6 "NotUsed" 5 "High" 4 "MediumHigh" 3 "Medium" 2 "LowMedium" 1 "Low" 0 "NotDetermined";
VAL_ 1104 DrvCamPassIR_D_Stat 3 "Faulty" 2 "Blocked" 1 "Ok" 0 "TemporaryUnavailable";
VAL_ 1104 DrvCamera_D_Stat 3 "Faulty" 2 "Blocked" 1 "Ok" 0 "TemporaryUnavailable";
VAL_ 1104 DrvCamDrvIR_D_Stat 3 "Faulty" 2 "Blocked" 1 "Ok" 0 "TemporaryUnavailable";
VAL_ 1104 DrvAttentZone_D_Stat 15 "Faulty" 14 "NotUsed_5" 13 "NotUsed_4" 12 "NotUsed_3" 11 "NotUsed_2" 10 "NotUsed_1" 9 "PassengerSideWindow" 8 "DriverSideWindow" 7 "DriverSideMirror" 6 "RearviewMirror" 5 "PassengerSideMirror" 4 "Infotainment" 3 "Cluster" 2 "FrontWindshield" 1 "Other" 0 "NotDetermined";
VAL_ 1104 DrvAlertSt_D_Stat 3 "Faulty" 2 "EyesOffRoad" 1 "EyesOnRoad" 0 "NotDetermined";
VAL_ 1114 TrailCtlSwtch_B_Stat2 1 "Pressed" 0 "Not_Pressed";
VAL_ 1114 TrlBrkInitOut_D_Rq 3 "Heavy" 2 "Medium" 1 "Light" 0 "Null";
VAL_ 1116 TrlrAidSetup_D2_Rq 15 "NotUsed_9" 14 "NotUsed_8" 13 "NotUsed_7" 12 "NotUsed_6" 11 "NotUsed_5" 10 "NotUsed_4" 9 "NotUsed_3" 8 "NotUsed_2" 7 "NotUsed_1" 6 "CompleteSetup" 5 "ReturnToSetup" 4 "StickerNotCircled" 3 "ConfirmSetup" 2 "EndSetup" 1 "BeginSetup" 0 "Inactive";
VAL_ 1116 TrlrAidEnbl_D2_Rq 7 "NotUsed_4" 6 "NotUsed_3" 5 "NotUsed_2" 4 "NotUsed_1" 3 "Deactivate" 2 "ActivateTrg" 1 "ActivateTba" 0 "Inactive";
VAL_ 1116 TrlrRvrseCancl_B_Rq 1 "Cancel" 0 "Null";
VAL_ 1116 TrlrIdType_D_Stat 3 "Gooseneck" 2 "FifthWheel" 1 "Conventional" 0 "Null";
VAL_ 1116 TrlrAnOffstDir_D_Mem 3 "NotUSed" 2 "Right" 1 "Left_or_Center" 0 "Null";
VAL_ 1085 ULoRgenTestMde_B_Stat 1 "Active" 0 "Inactive";
VAL_ 1085 PwSrcULoOvrTe_B_Actl 1 "Yes" 0 "No";
VAL_ 1085 PwSrcULoFalt_D_Stat 3 "Fault_No_Output" 2 "Fault_Reduced_Output" 1 "Fault_NonSpecific" 0 "No_Fault";
VAL_ 1085 PwSrcULoDcnnt_B_Stat 1 "Loose_or_Disconnected" 0 "Connected";
VAL_ 1085 PwSrcULo_Pc_Mx 255 "Fault";
VAL_ 1085 PwSrcULoComm_B_Falt 1 "Fault" 0 "No_Fault";
VAL_ 1085 PwSrcULo_I_Mx 255 "Fault";
VAL_ 1085 PwSrcULo_I_Actl 255 "Fault";
VAL_ 791 EngAirFilt_B_RqReset 1 "Yes" 0 "No";
VAL_ 791 GpsElMdeSel_B_Rq 1 "On" 0 "Off";
VAL_ 791 LongTermReset_B_Rq 1 "On" 0 "Off";
VAL_ 791 DrvEffLvl_No_Stat 63 "Fault" 62 "NoDataExists";
VAL_ 868 BattRgenLoStat_D_Qlty 3 "OK" 2 "Not_Within_Spec" 1 "Eval_In_Progress" 0 "Faulty";
VAL_ 868 BattRgenLoPrtct_B_Stat 1 "Yes" 0 "No";
VAL_ 868 BattRgenLoDChrg_D_Stat 3 "StuckClosed" 2 "StuckOpen" 1 "Closed" 0 "Open";
VAL_ 868 BattRgenLoDchrg_B_Rq 1 "Yes" 0 "No";
VAL_ 868 BattRgenLoChrg_D_Stat 3 "StuckClosed" 2 "StuckOpen" 1 "Closed" 0 "Open";
VAL_ 868 BattRgenLoChrg_B_Rq 1 "Yes" 0 "No";
VAL_ 868 BattRgenLo_B_Falt 1 "Yes" 0 "No";
VAL_ 867 BattRgenLoBalnc_B_Rq 1 "Yes" 0 "No";
VAL_ 867 BattRgenLo_Te_Actl 255 "Fault";
VAL_ 865 BattRgenLo_U_Actl 2047 "Faulty";
VAL_ 865 BattRgenLo_I_Actl 65535 "Faulty";
VAL_ 1144 WakeAlarm0_B_Typ 1 "CanAndEcuDriveCircuit" 0 "CanOnly";
VAL_ 1144 PreCondBatt_B_Actl 1 "On" 0 "Off";
VAL_ 1144 HtrnDcdcDis_B_Rq 1 "Yes" 0 "No";
VAL_ 1144 ChrgNowEvnt_B_Stat 1 "Active" 0 "Inactive";
VAL_ 1144 CabinDrvSustn_B_Rq 1 "Active" 0 "Inactive";
VAL_ 1144 BattChrgTrgtSoC_D_Rq 7 "Percent_50" 6 "Percent_60" 5 "Percent_70" 4 "Percent_80" 3 "Percent_85" 2 "Percent_90" 1 "Percent_95" 0 "Percent_100";
VAL_ 1144 CabnEvapSovFront_B_Rq 1 "On" 0 "Off";
VAL_ 1144 HeatCoreSovRear_B_Rq 1 "On" 0 "Off";
VAL_ 1144 BattChlrSov_B_Rq 1 "On" 0 "Off";
VAL_ 1144 CabnEvapSovRear_B_Rq 1 "On" 0 "Off";
VAL_ 1144 BrkAppl_D_RqPt 3 "BrakesSlowRelease" 2 "BrakesFastRelease" 1 "BrakesEngage" 0 "NotActive";
VAL_ 1144 HtrnCnnctPwr_B_Stat 1 "Asserted" 0 "NotAsserted";
VAL_ 1144 PtcHtr_D_Stat 3 "Faulty" 2 "NotUsed" 1 "On" 0 "Off";
VAL_ 1144 HtrnClntFlw_D_Rq 3 "High" 2 "Medium" 1 "Low" 0 "Off";
VAL_ 1144 BattTracDrvSustn_B_Rq 1 "Active" 0 "Inactive";
VAL_ 1144 BattTracClntVlv_B_Rq 1 "On" 0 "Off";
VAL_ 1141 OfbChrgSetSync_D_Stat 3 "Fail" 2 "Success" 1 "InProgress" 0 "NoSyncInProgress";
VAL_ 1141 PtRmtRprt_D_Rq 15 "NotUsed_4" 14 "NotUsed_3" 13 "NotUsed_2" 12 "PlugInToMaintain12vBattery" 11 "SettingUpdated" 10 "FastChargeComplete" 9 "ChargeNotOccurring" 8 "OneTimeSocReached" 7 "BatteryTemperatureReminder" 6 "ReducedPerformance" 5 "LimitedPerformance" 4 "ChargeFault" 3 "ChargeComplete" 2 "VehiclePreconditioned" 1 "TripDistanceAchieved" 0 "NoReportRequest";
VAL_ 1141 NtfctnConflict1_D_Rq 7 "NotUsed5" 6 "NotUsed4" 5 "NotUsed3" 4 "NotUsed2" 3 "NotUsed1" 2 "Clonflict_Exists" 1 "No_Conflict" 0 "Invalid";
VAL_ 1140 RgenEvntLvl_Pc_Dsply 1023 "Fault" 1022 "NoDataExists";
VAL_ 1140 BrkEvntComplt_B_Dsply 1 "On" 0 "Off";
VAL_ 1140 PreCondStat_D_Dsply 7 "Reserved3" 6 "Reserved2" 5 "Reserved1" 4 "Faulted" 3 "Complete" 2 "In_Progress" 1 "Scheduled" 0 "Not_Scheduled";
VAL_ 1139 BattChrgTrgtLMax_T_Est 2047 "Faulty" 2046 "NoDataExists";
VAL_ 1139 ActChrgStrtYr_No_Actl 31 "Invalid";
VAL_ 1139 ActChrgStrtMin_No_Actl 63 "Invalid" 62 "Unknown";
VAL_ 1139 ActChrgStrtHr_No_Actl 31 "Invalid" 30 "Unknown";
VAL_ 1139 ActChrgStrtDay_No_Actl 31 "Invalid";
VAL_ 1139 ActChrgStrMnth_No_Actl 15 "Invalid";
VAL_ 1138 BattChrgTrgtLMin_T_Est 2047 "Faulty" 2046 "NoDataExists";
VAL_ 1138 ActChrgEndYr_No_Actl 31 "Invalid";
VAL_ 1138 ActChrgEndMnth_No_Actl 15 "Invalid";
VAL_ 1138 ActChrgEndMin_No_Actl 63 "Invalid" 62 "Unknown";
VAL_ 1138 ActChrgEndHr_No_Actl 31 "Invalid" 30 "Unknown";
VAL_ 1138 ActChrgEndDay_No_Actl 31 "Invalid";
VAL_ 1089 Mtr2Aout_W_ActlMntr 1023 "Faulty";
VAL_ 1089 Inv1_Te_Actl 255 "Faulty" 254 "NoDataExists";
VAL_ 1089 MtrTrac2Coil_Te_Actl 255 "Faulty" 254 "NoDataExists";
VAL_ 1089 MtrTrac2Falt_B_Stat 1 "Active" 0 "Inactive";
VAL_ 1089 MtrTrac2TeAlrm_B_Stat 1 "Active" 0 "Inactive";
VAL_ 1089 Mtr2CntlTeAlrm_B_Stat 1 "Active" 0 "Inactive";
VAL_ 1089 MtrTrac2Inv_Te_Actl 255 "Faulty" 254 "NoDataExists";
VAL_ 1089 MtrTrac2_I_Actl 65535 "Faulty";
VAL_ 1088 ChrgTMatch_B_Stat 1 "True" 0 "False";
VAL_ 1088 ChrgStat_D2_Dsply 15 "NotUsed_2" 14 "NotUsed_1" 13 "ChargeTargetReached" 12 "DriveConditioning" 11 "CabinPreconditioning" 10 "ChargingSystemMaintain" 9 "ChargingInductive" 8 "ChargingDCFastChange" 7 "ChargingAC" 6 "ChargeScheduled" 5 "EvsePaused" 4 "EvseNotDetected" 3 "EvseNotCompatible" 2 "FaultOutsideCar" 1 "FaultInsideCar" 0 "NotReady";
VAL_ 1088 HvacPrecondRecirc_D_Rq 3 "Last_User_Setting" 2 "Auto" 1 "Recirc" 0 "Outside";
VAL_ 1088 HvacPrecondMode2_D_Rq 15 "NotUsed4" 14 "NotUsed3" 13 "NotUsed2" 12 "NotUsed1" 11 "Last_User_Settings" 10 "Auto" 9 "Max_Defrost" 8 "Windshield_Panel_Floor" 7 "Windshield_Panel" 6 "Windshield" 5 "Windshield_Floor" 4 "Floor" 3 "Panel_Floor" 2 "Panel" 1 "MAX_AC" 0 "Off";
VAL_ 1088 HvacPrecondBlwr2_D_Rq 15 "NotUsed6" 14 "NotUsed5" 13 "NotUsed4" 12 "NotUsed3" 11 "NotUsed2" 10 "NotUsed1" 9 "Last_User_Setting" 8 "Auto" 7 "Speed7" 6 "Speed6" 5 "Speed5" 4 "Speed4" 3 "Speed3" 2 "Speed2" 1 "Speed1" 0 "Off";
VAL_ 1088 HvacPrecondAC_D_Rq 3 "Last_User_Setting" 2 "Auto" 1 "On" 0 "Off";
VAL_ 1088 BattChrgInhbt_D_Rq 3 "MaintainTargetSoc" 2 "NotUsed" 1 "InhibitChargingThermal" 0 "Enable_Charging";
VAL_ 1040 ElCmprEnbl_B_Rq 1 "Enable" 0 "Disable";
VAL_ 1016 ChrgGoTElement_B_Dsply 1 "Yes" 0 "No";
VAL_ 1016 ChrgGoTTouchEnbl_B_Rq 1 "Request" 0 "NoRequest";
VAL_ 1016 ChrgGoTTouch_B_Stat 1 "On" 0 "Off";
VAL_ 1016 ChrgGoTPrcond_D_Stat 3 "High" 2 "Medium" 1 "Low" 0 "Off";
VAL_ 1016 ChrgGoTMnte_D_Stat 15 "NotUsed_4" 14 "NotUsed_3" 13 "NotUsed_2" 12 "NotUsed_1" 11 "Minute_55" 10 "Minute_50" 9 "Minute_45" 8 "Minute_40" 7 "Minute_35" 6 "Minute_30" 5 "Minute_25" 4 "Minute_20" 3 "Minute_15" 2 "Minute_10" 1 "Minute_5" 0 "Minute_0";
VAL_ 1016 ChrgGoTHr_T_Stat 31 "Faulty" 30 "NoDataExists";
VAL_ 1016 ChrgGoTExtHtrEnbl_B_Rq 1 "Request" 0 "NoRequest";
VAL_ 1016 ChrgGoTExtHtr_B_Stat 1 "On" 0 "Off";
VAL_ 1016 ChrgGoTAllOn_B_Stat 1 "On" 0 "Off";
VAL_ 1013 ChrgToPcWkndSav_D_Stat 7 "Percent_50" 6 "Percent_60" 5 "Percent_70" 4 "Percent_80" 3 "Percent_85" 2 "Percent_90" 1 "Percent_95" 0 "Percent_100";
VAL_ 1013 ChrgToPcWkdySav_D_Stat 7 "Percent_50" 6 "Percent_60" 5 "Percent_70" 4 "Percent_80" 3 "Percent_85" 2 "Percent_90" 1 "Percent_95" 0 "Percent_100";
VAL_ 1013 ChrgNowEnbl_B_Saved 1 "On" 0 "Off";
VAL_ 1013 ChrgLocIdUnsAck_B_Stat 1 "Yes" 0 "No";
VAL_ 1012 ChrgNowCurnt_B_Dsply 1 "On" 0 "Off";
VAL_ 1012 ChrgLocSaved_B_Dsply 1 "Yes" 0 "No";
VAL_ 1012 ChrgLocLongPostv_B_Sav 1 "Yes" 0 "No";
VAL_ 1012 ChrgLocLattPostv_B_Sav 1 "Yes" 0 "No";
VAL_ 1011 ChrgLocLongPostv_B_Uns 1 "Yes" 0 "No";
VAL_ 1011 ChrgLocLattPostv_B_Uns 1 "Yes" 0 "No";
VAL_ 871 BattElecPerf_D_Actl 7 "NotUsed" 6 "Hot_Batt_Severe_Lim_Perf" 5 "Hot_Batt_Reduced_Perf" 4 "Hot_Batt_Close_to_lim_Per" 3 "Cold_Batt_Severe_Lim_Perf" 2 "Cold_Batt_Reduced_Perf" 1 "Cold_Batt_Close_to_lim_Pe" 0 "Ok_no_message_displayed";
VAL_ 871 BattChrgTrgtLPt_T_Est 2047 "Faulty" 2046 "NoDataExists";
VAL_ 871 BattChrgTrgSocPt_T_Est 2047 "Faulty" 2046 "NoDataExists";
VAL_ 871 BattChrgCmpltPt_T_Est 2047 "Faulty" 2046 "NoDataExists";
VAL_ 786 RgenTrip_L_Dsply 65535 "Fault" 65534 "NoDataExists";
VAL_ 786 ChrgStat_D_Dsply 7 "NotUsed" 6 "Complete" 5 "Scheduled" 4 "In_Progress" 3 "Fault_Outside_Car" 2 "Fault_Inside_Car" 1 "Fault_Unknown_Location" 0 "Not_Ready";
VAL_ 72 immoTarget2Status 7 "Unused4" 6 "Unused3" 5 "Unused2" 4 "Unused1" 3 "DISABLED_RESET   " 2 "ENABLED_NONMOTIVE_START" 1 "ENABLED_MOTIVE_START" 0 "DISABLED";
VAL_ 72 immoTarget2Cmd 7 "Unused4" 6 "Unused3" 5 "Unused2" 4 "Unused1" 3 "TARGET1_IDBLOCK2" 2 "TARGET1_IDBLOCK1" 1 "CHALLENGE" 0 "IDLE";
VAL_ 912 CabnEvapSovFront_D_Stat 7 "NotUsed_1" 6 "FetLifeLimitReached" 5 "FetOpenCircuit" 4 "FetOutputShortToPower" 3 "FetOutputShortToGround" 2 "FetNotControlled" 1 "OnPowerToLoad" 0 "OffNoPowerToLoad";
VAL_ 912 BattChlrSov_D_Stat 7 "NotUsed_1" 6 "FetLifeLimitReached" 5 "FetOpenCircuit" 4 "FetOutputShortToPower" 3 "FetOutputShortToGround" 2 "FetNotControlled" 1 "OnPowerToLoad" 0 "OffNoPowerToLoad";
VAL_ 912 BattTracClntVlv_D_Stat 7 "NotUsed" 6 "FetLifeLimitReached" 5 "FetOpenCircuit" 4 "FetOutputShortToPower" 3 "FetOutputShortToGround" 2 "FetNotControlled" 1 "OnPowerToLoad" 0 "OffNoPowerToLoad";
VAL_ 874 AirCondCluOpen_D_Falt 3 "NotUsed" 2 "Pass" 1 "Fail" 0 "Not_Diagnose_Yet";
VAL_ 874 AirCondCluLife_D_Falt 3 "NotUsed" 2 "Pass" 1 "Fail" 0 "Not_Diagnose_Yet";
VAL_ 874 AirCondCluGnd_D_Falt 3 "NotUsed" 2 "Pass" 1 "Fail" 0 "Not_Diagnose_Yet";
VAL_ 874 AirCondClu_D_Stat 7 "NotUsed" 6 "FetLifeLimitReached" 5 "FetOpenCircuit" 4 "FetOutputShortToPower" 3 "FetOutputShortToGround" 2 "FetNotControlled" 1 "OnPowerToLoad" 0 "OffNoPowerToLoad";
VAL_ 874 AirCondCluBatt_D_Falt 3 "NotUsed" 2 "Pass" 1 "Fail" 0 "Not_Diagnose_Yet";
VAL_ 874 BattTracShrtGrnd_D_Falt 3 "NotUsed" 2 "Pass" 1 "Fail" 0 "Not_Diagnose_Yet";
VAL_ 874 BattTracShrtBatt_D_Falt 3 "NotUsed" 2 "Pass" 1 "Fail" 0 "Not_Diagnose_Yet";
VAL_ 874 BattTracOpnCirct_D_Falt 3 "NotUsed" 2 "Pass" 1 "Fail" 0 "Not_Diagnose_Yet";
VAL_ 874 BattTracLifeLim_D_Falt 3 "NotUsed" 2 "Pass" 1 "Fail" 0 "Not_Diagnose_Yet";
VAL_ 874 BattChlrShrtGrnd_D_Falt 3 "NotUsed" 2 "Pass" 1 "Fail" 0 "Not_Diagnose_Yet";
VAL_ 874 BattChlrShrtBatt_D_Falt 3 "NotUsed" 2 "Pass" 1 "Fail" 0 "Not_Diagnose_Yet";
VAL_ 874 BattChlrOpnCirct_D_Falt 3 "NotUsed" 2 "Pass" 1 "Fail" 0 "Not_Diagnose_Yet";
VAL_ 874 BattChlrLifeLim_D_Falt 3 "NotUsed" 2 "Pass" 1 "Fail" 0 "Not_Diagnose_Yet";
VAL_ 874 BattTracLow_D_Falt 3 "NotUsed" 2 "Pass" 1 "Fail" 0 "Not_Diagnose_Yet";
VAL_ 651 TelematicsSrvc_D_St 7 "NotUsed" 6 "NotifyNotActivatedYet" 5 "NotActivatedYet" 4 "NotifyExpired" 3 "Expired" 2 "ExpiringSoon" 1 "Active" 0 "Null";
VAL_ 651 EmgcyCallMute_D_Stat 7 "NotUsed4" 6 "NotUsed3" 5 "NotUsed2" 4 "NotUsed1" 3 "ManualEmergencyCallMute" 2 "AutomaticEmergencyCallMute" 1 "EmergencyCallUnmute" 0 "Null";
VAL_ 651 OfbChrgSetSync_D_Rq 3 "Fail" 2 "Success" 1 "InProgress" 0 "NoSyncInProgress";
VAL_ 529 OnbChrgToPcWknd_D_Actl 7 "Percent_50" 6 "Percent_60" 5 "Percent_70" 4 "Percent_80" 3 "Percent_85" 2 "Percent_90" 1 "Percent_95" 0 "Percent_100";
VAL_ 529 OnbChrgToPcWkdy_D_Actl 7 "Percent_50" 6 "Percent_60" 5 "Percent_70" 4 "Percent_80" 3 "Percent_85" 2 "Percent_90" 1 "Percent_95" 0 "Percent_100";
VAL_ 529 OnbChrgSetNow_D_Rq 3 "NotUsed" 2 "On" 1 "Off" 0 "Null";
VAL_ 529 OnbChrgSetDelete_B_Rq 1 "Request" 0 "NoRequest";
VAL_ 529 OnbChrgPrflUpdate_B_Rq 1 "Request" 0 "NoRequest";
VAL_ 529 OnbChrgLocIdUns_B_Rq 1 "Request" 0 "NoRequest";
VAL_ 66 immoControlCmd_T2 0 "IDLE" 1 "MOTIVE_START_RQST" 2 "NONMOTIVE_START_RQST" 3 "RQST_TARGET2_IDBLOCK1" 4 "RQST_TARGET2_IDBLOCK2" 5 "Unused" 6 "ECHO_TARGET2_IDBLOCK2" 7 "SHUTDOWN";
VAL_ 1124 GPS_Vdop 31 "Invalid" 30 "Unknown";
VAL_ 1124 GPS_Speed 255 "Invalid" 254 "Unknown";
VAL_ 1124 GPS_Sat_num_in_view 31 "Invalid" 30 "Unknown";
VAL_ 1124 GPS_MSL_altitude 4095 "Fault" 4094 "Unknown";
VAL_ 1124 GPS_Heading 65535 "Fault" 65534 "Unknown";
VAL_ 1124 GPS_Hdop 31 "Invalid" 30 "Unknown";
VAL_ 1124 GPS_dimension 2 "_3D" 1 "_2D" 0 "No_Fix";
VAL_ 1119 CoolFanDcdc_D_Rq 3 "High" 2 "Medium" 1 "Low" 0 "Off";
VAL_ 1119 DcdcClntFlw_D_Rq 3 "High" 2 "Medium" 1 "Low" 0 "Off";
VAL_ 1123 GpsUtcYr_No_Actl 31 "Fault";
VAL_ 1123 GpsUtcMnth_No_Actl 15 "Fault";
VAL_ 1123 GPS_UTC_seconds 63 "Fault" 62 "Unknown";
VAL_ 1123 GPS_UTC_minutes 63 "Fault" 62 "Unknown";
VAL_ 1123 GPS_UTC_hours 31 "Invalid" 30 "Unknown";
VAL_ 1123 GPS_Pdop 31 "Invalid" 30 "Unknown";
VAL_ 1123 GPS_Compass_direction 7 "NorthWest" 6 "West" 5 "SouthWest" 4 "South" 3 "SouthEast" 2 "East" 1 "NorthEast" 0 "North";
VAL_ 1123 GPS_Actual_vs_Infer_pos 1 "Inferred_Position" 0 "Actual_Postition";
VAL_ 1123 Gps_B_Falt 1 "Yes" 0 "No";
VAL_ 1122 GpsHsphLongEast_D_Actl 0 "Invalid" 1 "Eastern" 2 "Western" 3 "Fault";
VAL_ 1122 GpsHsphLattSth_D_Actl 3 "Fault" 2 "Northern" 1 "Southern" 0 "Invalid";
VAL_ 1122 GPS_Longitude_Minutes 63 "Fault" 62 "Unknown";
VAL_ 1122 GPS_Longitude_Min_dec 16383 "Invalid" 16382 "Unknown";
VAL_ 1122 GPS_Longitude_Degrees 511 "Fault" 510 "Unknown";
VAL_ 1122 GPS_Latitude_Minutes 63 "Fault" 62 "Unknown";
VAL_ 1122 GPS_Latitude_Min_dec 16383 "Invalid" 16382 "Unknown";
VAL_ 1122 GPS_Latitude_Degrees 255 "Invalid" 254 "Unknown";
VAL_ 1003 PersRecallSrc_D_Actl 7 "NotUsed_3" 6 "NotUsed_2" 5 "NotUsed_1" 4 "MemorySwitch" 3 "RemoteStart" 2 "KeyFob" 1 "CenterStack" 0 "Null";
VAL_ 1003 Pers4Key_D_Stat 3 "NotUsed_1" 2 "KeyUnAssociated" 1 "KeyAssociated" 0 "Null";
VAL_ 1003 Pers3Key_D_Stat 3 "NotUsed_1" 2 "KeyUnAssociated" 1 "KeyAssociated" 0 "Null";
VAL_ 1003 Pers2Key_D_Stat 3 "NotUsed_1" 2 "KeyUnAssociated" 1 "KeyAssociated" 0 "Null";
VAL_ 1003 Pers1Key_D_Stat 3 "NotUsed_1" 2 "KeyUnAssociated" 1 "KeyAssociated" 0 "Null";
VAL_ 1003 EmPrflNo_D_Stat 7 "NotUsed_3" 6 "NotUsed_2" 5 "NotUsed_1" 4 "Pers4" 3 "Pers3" 2 "Pers2" 1 "Pers1" 0 "Null";
VAL_ 1003 EmPrflKeyAssoc_D_Stat 7 "WrongDevice" 6 "KeyAssociateFailed" 5 "KeyAssociateSuccess" 4 "KeyAlreadyInUse" 3 "KeyDisassociated" 2 "KeyAssociationExited" 1 "KeyAssociationEntered" 0 "Null";
VAL_ 1003 VehKeyActv_D_Stat 15 "NotUsed7" 14 "NotUsed6" 13 "NotUsed5" 12 "NotUsed4" 11 "NotUsed3" 10 "NotUsed2" 9 "NotUsed1" 8 "Key8Active" 7 "Key7Active" 6 "Key6Active" 5 "Key5Active" 4 "Key4Active" 3 "Key3Active" 2 "Key2Active" 1 "Key1Active" 0 "NoKeyActive";
VAL_ 1003 PersNoPos_D_Actl 7 "Unused_3" 6 "Unused_2" 5 "Unused_1" 4 "Vehicle" 3 "PERS_4" 2 "PERS_3" 1 "PERS_2" 0 "PERS_1";
VAL_ 1003 PersSetupRestr_D_Actl 3 "Non_Moveable_Person" 2 "Moveable_Person" 1 "Vehicle" 0 "Factory";
VAL_ 1003 PersSetupAccessCtrl 1 "Limited" 0 "Full";
VAL_ 1003 PersConflict_D_Actl 1 "Conflict" 0 "No_Conflict";
VAL_ 1003 AssocConfirm_D_Actl 0 "None" 7 "Associate" 6 "Keycode_Rejected" 5 "Keycode_Accepted" 4 "In_Progress" 3 "Erase" 2 "Duplicate" 1 "Disassociate";
VAL_ 1003 PersNo_D_Actl 7 "Unused_3" 6 "Unused_2" 5 "NotDetermined" 4 "Vehicle" 3 "PERS_4" 2 "PERS_3" 1 "PERS_2" 0 "PERS_1";
VAL_ 994 PersStore_D_Rq 7 "Unused_2" 6 "Unused_1" 5 "Vehicle" 4 "PERS_4" 3 "PERS_3" 2 "PERS_2" 1 "PERS_1" 0 "Null";
VAL_ 994 Pers4OptIn_B_Stats 1 "OPTED_IN" 0 "NOT_OPTED_IN";
VAL_ 994 Pers3OptIn_B_Stats 1 "OPTED_IN" 0 "NOT_OPTED_IN";
VAL_ 994 Pers2OptIn_B_Stats 1 "OPTED_IN" 0 "NOT_OPTED_IN";
VAL_ 994 Pers1OptIn_B_Stats 1 "OPTED_IN" 0 "NOT_OPTED_IN";
VAL_ 994 CtrStkPersIndex_D_Actl 7 "Unused_3" 6 "Unused_2" 5 "Unused_1" 4 "Vehicle" 3 "PERS_4" 2 "PERS_3" 1 "PERS_2" 0 "PERS_1";
VAL_ 994 CtrStkDsplyOp_D_Rq 7 "Unused_2" 6 "Unused_1" 5 "Copy" 4 "Restore" 3 "Upload" 2 "Set" 1 "Query" 0 "Null";
VAL_ 778 PrkAidFront_D_RqDrv 2 "Status" 3 "NotUsed" 1 "Enabled" 0 "Disabled";
VAL_ 778 PrkAidAcsyRear_D_RqDrv 3 "NotUsed" 2 "On" 1 "Off" 0 "Null";
VAL_ 778 PrkAidAcsyFront_D_RqDrv 3 "NotUsed" 2 "On" 1 "Off" 0 "Null";
VAL_ 778 Cta_D_Rq 3 "Unused" 2 "NoDataExists" 1 "On" 0 "Off";
VAL_ 778 PrkAidRear_D_RqDrv 2 "Status" 3 "NotUsed" 1 "Enabled" 0 "Disabled";
VAL_ 778 SteEffort_D_Rq 7 "NotUsed_3" 6 "NotUsed_2" 5 "NotUsed_1" 4 "SpecialMode_2" 3 "SpecialMode_1" 2 "Comfort" 1 "Sport" 0 "Normal";
VAL_ 778 Sod_D_Rq 2 "BLIS_On_Second_Warning_ON" 1 "BLIS_On_Second_Warning_OFF" 0 "Off";
VAL_ 549 IPC_MyKeyVolLimit_St 0 "Invalid" 1 "Off" 2 "On";
VAL_ 549 HdcOn_B_Rq 1 "On" 0 "Off";
VAL_ 549 IPC_Attn_Info_Audio 7 "Unknown" 6 "Attenuation_6" 5 "Attenuation_5" 4 "Attenuation_4" 3 "Attenuation_3" 2 "Attenuation_2" 1 "Attenuation_1" 0 "No_Attenuation_of_Audio";
VAL_ 549 BeltminderAudioMute 2 "On" 1 "Off" 0 "Invalid";
VAL_ 549 Power_Up_Chime_Modules 1 "Active" 0 "Inactive";
VAL_ 549 Chime_Source 2 "Cluster" 1 "Infotainment_Sys" 0 "Invalid";
VAL_ 549 IPC_New_Attn_Event 1 "Active" 0 "Inactive";
VAL_ 551 PmCabnLvl_D_Stat 7 "NotUsed_1" 6 "Level_6_Worst" 5 "Level_5" 4 "Level_4" 3 "Level_3" 2 "Level_2" 1 "Level_1_Best" 0 "NotKnown";
VAL_ 551 PmCabn_D_Stat 3 "FilteringComplete" 2 "FilteringOn" 1 "FilteringOff" 0 "NotKnown";
VAL_ 551 Cntr_Plg_Mode_Cmd 1 "Enable" 0 "Disable";
VAL_ 551 ChrgCrdLckEnbl_B_Stat 1 "Enable" 0 "Disable";
VAL_ 551 PwRnngBoardT_D_Rq 3 "NotUsed" 2 "Timer2" 1 "Timer1" 0 "Inactive";
VAL_ 551 PwRnngBoardSwtch_D_Rq 3 "NotUsed" 2 "DeployUnlocked" 1 "AlwaysActive" 0 "Inactive";
VAL_ 551 PwRnngBoardMde_D_Rq 0 "Inactive" 1 "Off" 2 "Out" 3 "Auto";
VAL_ 551 Btt_L_Actl2 127 "Faulty" 126 "NoDataExists";
VAL_ 551 Rba_D_Rq 3 "NotUsed" 2 "On" 1 "Off" 0 "Null";
VAL_ 551 EmPrflNo_D_Rq 7 "NotUsed_3" 6 "NotUsed_2" 5 "NotUsed_1" 4 "Pers4" 3 "Pers3" 2 "Pers2" 1 "Pers1" 0 "Null";
VAL_ 551 EmPrflButtnAssoc_D_Rq 3 "NotUsed" 2 "ExitButtonAssociation" 1 "EnterButtonAssociation" 0 "Null";
VAL_ 551 EmPrflKeyAssoc_D_Rq 7 "NotUsed_3" 6 "DisassociatePhone" 5 "EnterPhoneAssociation" 4 "OverwriteKey" 3 "DisassociateKey" 2 "ExitKeyAssociation" 1 "EnterKeyAssociation" 0 "Null";
VAL_ 551 Em_D_Stat 3 "NotSupported" 2 "ProfilesOff" 1 "ProfilesOn" 0 "Null";
VAL_ 551 ChrgOvrdExitScrn_D_Rq 3 "NotUsed_1" 2 "Request_override" 1 "Do_not_request_override" 0 "Inactive";
VAL_ 1010 MbdblActv_B_RqAdas 1 "Yes" 0 "No";
VAL_ 1010 CbdblActv_B_RqAdas 1 "Yes" 0 "No";
VAL_ 1010 AdbUrbanArea_B_Stat 1 "Yes" 0 "No";
VAL_ 1070 BattULo24_D_Falt 3 "NotUsed" 2 "TemporaryFault" 1 "Fault" 0 "NoFault";
VAL_ 1070 BattULo24_Te_Actl 127 "Fault";
VAL_ 1070 BattULo24State_D_Qlty 3 "OK" 2 "Not_Within_Spec" 1 "Eval_In_Progress" 0 "Faulty";
VAL_ 1070 BattULo24_I_Actl 16383 "Faulty";
VAL_ 1070 BattULo24_B_Falt 1 "Yes" 0 "No";
VAL_ 1186 SelDrvMdeAwd2_D_Stat 31 "Faulty" 30 "NotUsed_17" 29 "NotUsed_16" 28 "NotUsed_15" 27 "NotUsed_14" 26 "NotUsed_13" 25 "NotUsed_12" 24 "NotUsed_11" 23 "NotUsed_10" 22 "NotUsed_9" 21 "NotUsed_8" 20 "NotUsed_7" 19 "NotUsed_6" 18 "NotUsed_5" 17 "EvLaterChargeMode" 16 "EvNowMode" 15 "TrackMode" 14 "RoughRoadMode" 13 "NotAvailable" 12 "HighSpeedDesertMode_Baja" 11 "SportAdaptiveMode" 10 "RockCrawlMode" 9 "MudRutsMode" 8 "SandMode" 7 "EconomyMode" 6 "GrassGravelSnow" 5 "TowHaulMode" 4 "SportMode" 3 "Normal_4L" 2 "Normal_4A" 1 "Normal_2H" 0 "NormalMode";
VAL_ 1186 RearDiffLckMsg_D_Rq 7 "Locker_Disabled" 6 "Locker_Enabled" 5 "Locker_Accel_Pedal" 4 "Speed4" 3 "Speed3" 2 "Spee2" 1 "Speed1" 0 "Normal__No_Message ";
VAL_ 1186 RearDiffLckLamp_D_Rq 3 "Not_Used" 2 "Flash" 1 "On" 0 "Off";
VAL_ 1186 RearDiffLck_Tq_Actl 4095 "Fault" 4094 "Unknown";
VAL_ 1186 RearDiffFalt_D_Stat 3 "Diff_Failed_Closed" 2 "Diff_Failed_Open" 1 "Fault_Non_Specific" 0 "No_Fault";
VAL_ 1186 LsdSrvcRqd_B_Rq 1 "On" 0 "Off";
VAL_ 611 AwdSys_D_Stat 3 "Faulty" 2 "NotUsed" 1 "_4x4_L_H_Active" 0 "_4x4_L_H_Inactive";
VAL_ 611 AwdStat_D_RqDsply 31 "NotUsed9" 30 "NotUsed8" 29 "NotUsed7" 28 "To_Engage_4x4_Release_Aped" 27 "To_Engage_4x4_Slow_To_3MPH" 26 "Shift_To_Neutral" 25 "Lkr_Mode_Unavail_TMS" 24 " _4x4_Mode_Unavail_TMS" 23 "Out_of_4Low_Crawl" 22 "AWD_PTU_Oil_Changed" 21 "Change_AWD_PTU_Oil" 20 "Neutral_Tow_Disabled" 19 "Neutral_Tow_Enabled" 18 "AWD_OFF" 17 "_4x4_Off_Road_Speed" 16 "_4x4_Extreme_Off_Road_Mode" 15 "_4x4_Exiting_Off_Road" 14 "_4x4_Off_Road_Mode" 10 "_4x4_Locked_Temporarily" 9 "Shift_In_Progress" 13 "Blocked_Shift_Assist" 12 "_4x4_Auto_Restored" 11 "_4x4_Disabled_Temporarily" 7 "Out_of_4Low__Neutral" 6 "Out_of_4Low__Brake" 5 "Out_of_4Low__Speed" 4 "Into_4Low__Clutch" 3 "Into_4Low__Neutral" 2 "Into_4Low__Brake" 1 "Into_4Low__Speed" 0 "Normal__No_Message" 8 "Out_of_4Low__Clutch";
VAL_ 611 AwdLck_D_Stat 9 "Undefined" 8 "Under_External_Torque_Ctrl" 7 "Torque_Limited_by_Cmd" 6 "Fully_Locked_by_Cmd" 5 "Disabled" 4 "Warning" 3 "Fault" 2 "Inactive" 1 "Completely_Opened_by_Cmd" 0 "OK";
VAL_ 611 AwdSrvcRqd_B_Rq 1 "On" 0 "Off";
VAL_ 611 NtrlTowAvail_B_Stat 1 "Available" 0 "NotAvailable";
VAL_ 611 AwdLck_Tq_Rq 4095 "Fault" 4094 "Unknown";
VAL_ 611 AwdOffRoadMode_D_Stats 3 "Invalid" 2 "Extreme_Off_Road" 1 "Off_Road" 0 "Normal_Mode";
VAL_ 611 AwdLoLamp_D_RqDsply 3 "Not_Used" 2 "Flash" 1 "On" 0 "Off";
VAL_ 611 AwdHiLamp_D_RqDsply 3 "Not_Used" 2 "Flash" 1 "On" 0 "Off";
VAL_ 611 AwdAutoLamp_D_RqDsply 3 "Not_Used" 2 "Flash" 1 "On" 0 "Off";
VAL_ 611 Awd2wdLamp_D_RqDsply 3 "Not_Used" 2 "Flash" 1 "On" 0 "Off";
VAL_ 611 AwdRnge_D_Actl 7 "Unknown" 6 "High_Range_2wd" 5 "High_Range_Auto" 4 "High_Range_Locked" 3 "Neutral" 2 "Low_Range_2wd" 1 "Low_Range_Auto" 0 "Low_Range_Locked";
VAL_ 1047 TrlrAidSetup_D2_Stat 7 "NotUsed_2" 6 "NotUsed_1" 5 "SetupAcquisitionSuccess" 4 "TbaTadMonitor" 3 "SetupStartAcquisition" 2 "SetupPrepForAcquisition" 1 "TbaActive" 0 "Null";
VAL_ 1047 TrlrAidEnbl_D2_Stat 7 "NotUsed_1" 6 "TbaActiveExpertActive" 5 "TbaActiveExpertAvail" 4 "TbaOffTrgActive" 3 "TbaOffTrgSetup" 2 "TbaSetup" 1 "TbaActive" 0 "Inactive";
VAL_ 1047 TrlrAidMsgTxt_D2_Rq 63 "Message63" 62 "Message62" 61 "Message61" 60 "Message60" 55 "Message55" 50 "Message50" 45 "Message45" 40 "Message40" 35 "Message35" 31 "Message31" 30 "Message30" 29 "Message29" 28 "Message28" 27 "Message27" 26 "Message26" 25 "Message25" 24 "Message24" 23 "Message23" 22 "Message22" 21 "Message21" 20 "Message20" 19 "Message19" 18 "Message18" 17 "Message17" 16 "Message16" 15 "Message15" 14 "Message14" 13 "Message13" 12 "Message12" 11 "Message11" 10 "Message10" 9 "Message9" 8 "Message8" 7 "Message7" 6 "Message6" 5 "Message5" 4 "Message4" 3 "Message3" 2 "Message2" 1 "Message1" 0 "NoMessage";
VAL_ 1047 EsaOn_B_Stat 1 "On" 0 "Off";
VAL_ 1047 SelDrvMdeSte_D_Stat 0 "NotAvailable" 1 "Available" 2 "TemporarilyNotAvailable" 3 "Faulty";
VAL_ 972 LatCtlSte_D_Stat 7 "NotUsed3" 6 "NotUsed2" 5 "NotUsed1" 4 "Denied" 3 "RampOut" 2 "ContLatControlInProgress" 1 "Available" 0 "Unavailable";
VAL_ 972 LatCtlLim_D_Stat 3 "LimitWithDriverActive" 2 "LimitReached" 1 "LimitClose" 0 "LimitNotReached";
VAL_ 972 LatCtlCpblty_D_Stat 3 "Faulty" 2 "ExtendedModeAvailable" 1 "LimitedModeAvailable" 0 "NoModeAvailable";
VAL_ 972 LsmcBrkDecelEnbl_D_Rq 3 "NotUsed2" 2 "NotUsed1" 1 "On" 0 "Off";
VAL_ 972 TjaHandsOnCnfdnc_B_Est 1 "High_Confidence" 0 "Low_Confidence";
VAL_ 972 LaHandsOff_B_Actl 1 "Hands_Off" 0 "Hands_On";
VAL_ 972 LaActDeny_B_Actl 1 "LA_Denied" 0 "LA_Not_Denied";
VAL_ 972 LaActAvail_D_Actl 3 "LKA_LCA_LDW_Avail" 2 "LCA_LKA_Avail_LDW_Suppress" 1 "LCA_LKA_Suppress_LDW_Avail" 0 "LCA_LKA_LDW_Suppress";
VAL_ 130 TrlrHitchLamp_D_Rqst 1 "On" 0 "Off";
VAL_ 130 VehVTrlrAid_B_Rq 1 "Request" 0 "NoRequest";
VAL_ 130 DrvSteActv_B_Stat 1 "Active" 0 "Inactive";
VAL_ 130 DrvSte_Tq_Actl 255 "Invalid" 254 "Unknown";
VAL_ 130 SteMdule_D_Stat 7 "NotUsed" 6 "EPAS_Failure3" 5 "EPAS_Failure2" 4 "System_Failure" 3 "EPAS_Shutdown" 2 "Normal_Op_Full_Assist" 1 "Normal_Op_Limited_Assist" 0 "EPAS_Initialization";
VAL_ 130 SteMdule_U_Meas 255 "Invalid";
VAL_ 130 SteMdule_I_Est 4095 "Invalid";
VAL_ 130 EPAS_Failure 3 "SERVICE_POWER_STEERING_NOW" 2 "SERVICE_POWER_STEERING" 1 "POWER_STRG_ASSIST_FAULT" 0 "EPAS_OK_NO_MESSAGE";
VAL_ 130 SteeringColumnTorque 255 "Invalid" 254 "Unknown";
VAL_ 130 SAPPAngleControlStat6 1 "RequestedAngleNotReached" 0 "RequestedAngleCanBeReached";
VAL_ 130 SAPPAngleControlStat5 1 "StrgColTorqueExceed_EAROn" 0 "ExternalSigContentOKforEAC";
VAL_ 130 SAPPAngleControlStat4 1 "SpeedLimitExceededEAROn" 0 "ExternalSigContentOKforEAC";
VAL_ 130 SAPPAngleControlStat3 1 "EARactiveNoReverseEngage" 0 "ExternalSigContentOKforEAC";
VAL_ 130 SAPPAngleControlStat2 1 "Rel_ExtSteeringAngleReqx" 0 "NoRel_ExtSteeringAngleReqx";
VAL_ 130 SAPPAngleControlStat1 3 "Fault" 2 "Active" 1 "Open" 0 "Closed";
VAL_ 126 StePw_B_Rq 1 "Yes" 0 "No";
VAL_ 126 StePinRelInit_An_Sns 65535 "Faulty" 65534 "NoDataExists";
VAL_ 126 StePinCompAnEst_D_Qf 3 "OK" 2 "Degraded" 1 "No_Data_Exists" 0 "Faulty";
VAL_ 133 StePw_B_Rq 1 "Yes" 0 "No";
VAL_ 133 StePinRelInit_An_Sns 65535 "Faulty" 65534 "NoDataExists";
VAL_ 133 StePinCompAnEst_D_Qf 3 "OK" 2 "Degraded" 1 "No_Data_Exists" 0 "Faulty";
